VERSION ""

NS_ :

BS_:

BU_:

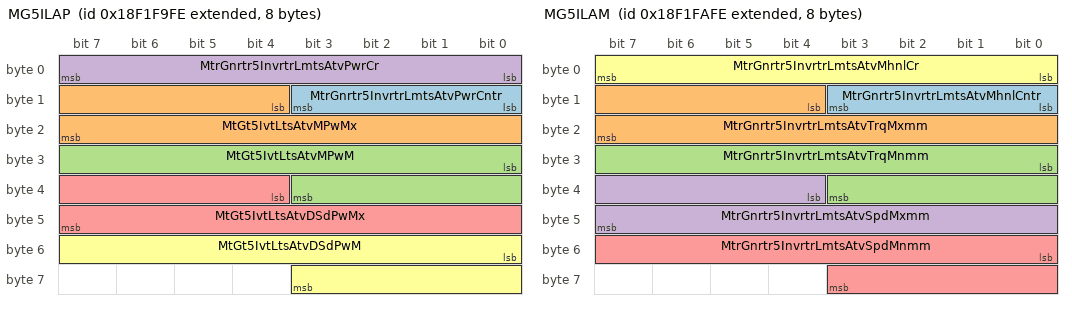
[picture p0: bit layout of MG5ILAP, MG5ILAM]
BO_ 2565995006 MG5ILAP: 8 Vector__XXX
 SG_ MtrGnrtr5InvrtrLmtsAtvPwrCntr : 8|4@1+ (1,0) [0|15] "" Vector__XXX
 SG_ MtGt5IvtLtsAtvMPwMx : 12|12@1+ (0.0625,-125) [-125|125.9375] "%" Vector__XXX
 SG_ MtGt5IvtLtsAtvMPwM : 24|12@1+ (0.0625,-125) [-125|125.9375] "%" Vector__XXX
 SG_ MtrGnrtr5InvrtrLmtsAtvPwrCr : 0|8@1+ (1,0) [0|250] "count" Vector__XXX
 SG_ MtGt5IvtLtsAtvDSdPwMx : 36|12@1+ (0.0625,-125) [-125|125.9375] "%" Vector__XXX
 SG_ MtGt5IvtLtsAtvDSdPwM : 48|12@1+ (0.0625,-125) [-125|125.9375] "%" Vector__XXX

BO_ 2565995262 MG5ILAM: 8 Vector__XXX
 SG_ MtrGnrtr5InvrtrLmtsAtvMhnlCntr : 8|4@1+ (1,0) [0|15] "" Vector__XXX
 SG_ MtrGnrtr5InvrtrLmtsAtvTrqMxmm : 12|12@1+ (0.0625,-125) [-125|125.9375] "%" Vector__XXX
 SG_ MtrGnrtr5InvrtrLmtsAtvTrqMnmm : 24|12@1+ (0.0625,-125) [-125|125.9375] "%" Vector__XXX
 SG_ MtrGnrtr5InvrtrLmtsAtvSpdMxmm : 36|12@1+ (0.0625,-125) [-125|125.9375] "%" Vector__XXX
 SG_ MtrGnrtr5InvrtrLmtsAtvSpdMnmm : 48|12@1+ (0.0625,-125) [-125|125.9375] "%" Vector__XXX
 SG_ MtrGnrtr5InvrtrLmtsAtvMhnlCr : 0|8@1+ (1,0) [0|250] "count" Vector__XXX

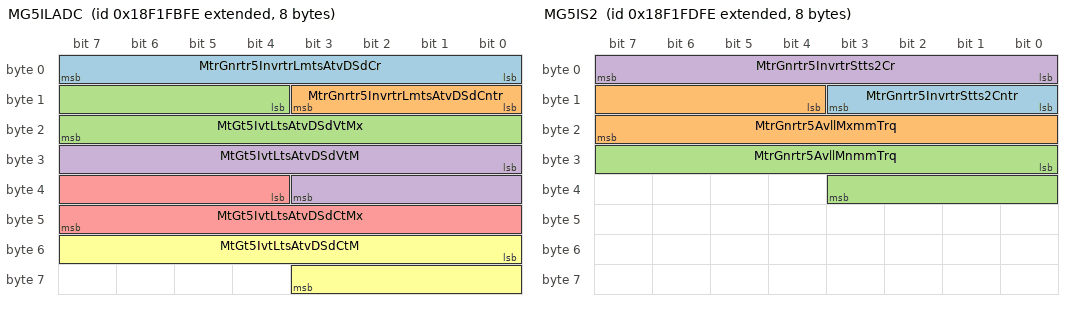
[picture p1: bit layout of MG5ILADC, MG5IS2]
BO_ 2565995518 MG5ILADC: 8 Vector__XXX
 SG_ MtrGnrtr5InvrtrLmtsAtvDSdCr : 0|8@1+ (1,0) [0|250] "count" Vector__XXX
 SG_ MtrGnrtr5InvrtrLmtsAtvDSdCntr : 8|4@1+ (1,0) [0|15] "" Vector__XXX
 SG_ MtGt5IvtLtsAtvDSdVtMx : 12|12@1+ (0.0625,-125) [-125|125.9375] "%" Vector__XXX
 SG_ MtGt5IvtLtsAtvDSdVtM : 24|12@1+ (0.0625,-125) [-125|125.9375] "%" Vector__XXX
 SG_ MtGt5IvtLtsAtvDSdCtMx : 36|12@1+ (0.0625,-125) [-125|125.9375] "%" Vector__XXX
 SG_ MtGt5IvtLtsAtvDSdCtM : 48|12@1+ (0.0625,-125) [-125|125.9375] "%" Vector__XXX

BO_ 2565995774 MG5ILV: 8 Vector__XXX
 SG_ MtrGnrtr5InvrtrSwthdIgntnVltg : 0|16@1+ (0.05,0) [0|3212.75] "V" Vector__XXX
 SG_ MtrGnrtr5InvrtrUnswthdSlVltg : 16|16@1+ (0.05,0) [0|3212.75] "V" Vector__XXX

BO_ 2565996030 MG5IS2: 8 Vector__XXX
 SG_ MtrGnrtr5InvrtrStts2Cntr : 8|4@1+ (1,0) [0|15] "" Vector__XXX
 SG_ MtrGnrtr5AvllMxmmTrq : 12|12@1+ (0.0625,-125) [-125|125.9375] "%" Vector__XXX
 SG_ MtrGnrtr5AvllMnmmTrq : 24|12@1+ (0.0625,-125) [-125|125.9375] "%" Vector__XXX
 SG_ MtrGnrtr5InvrtrStts2Cr : 0|8@1+ (1,0) [0|250] "count" Vector__XXX

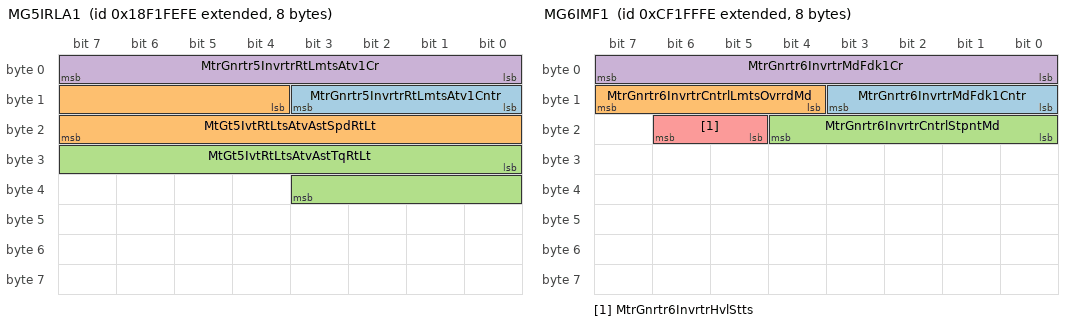
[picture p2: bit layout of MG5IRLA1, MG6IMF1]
BO_ 2565996286 MG5IRLA1: 8 Vector__XXX
 SG_ MtrGnrtr5InvrtrRtLmtsAtv1Cntr : 8|4@1+ (1,0) [0|15] "" Vector__XXX
 SG_ MtGt5IvtRtLtsAtvAstSpdRtLt : 12|12@1+ (0.25,0) [0|1003.75] "%/s" Vector__XXX
 SG_ MtGt5IvtRtLtsAtvAstTqRtLt : 24|12@1+ (2,0) [0|8030] "%/s" Vector__XXX
 SG_ MtrGnrtr5InvrtrRtLmtsAtv1Cr : 0|8@1+ (1,0) [0|250] "count" Vector__XXX

BO_ 2364669950 MG6IMF1: 8 Vector__XXX
 SG_ MtrGnrtr6InvrtrMdFdk1Cntr : 8|4@1+ (1,0) [0|15] "" Vector__XXX
 SG_ MtrGnrtr6InvrtrCntrlLmtsOvrrdMd : 12|4@1+ (1,0) [0|15] "" Vector__XXX
 SG_ MtrGnrtr6InvrtrCntrlStpntMd : 16|5@1+ (1,0) [0|31] "" Vector__XXX
 SG_ MtrGnrtr6InvrtrMdFdk1Cr : 0|8@1+ (1,0) [0|250] "count" Vector__XXX
 SG_ MtrGnrtr6InvrtrHvlStts : 21|2@1+ (1,0) [0|3] "" Vector__XXX

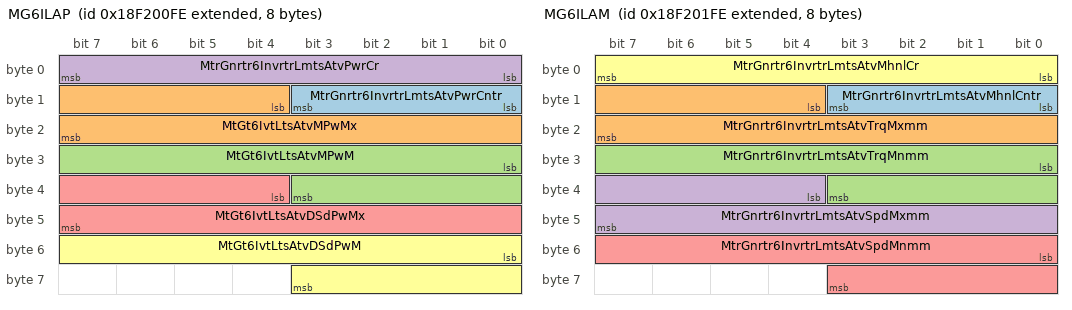
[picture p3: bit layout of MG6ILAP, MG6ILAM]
BO_ 2565996798 MG6ILAP: 8 Vector__XXX
 SG_ MtrGnrtr6InvrtrLmtsAtvPwrCntr : 8|4@1+ (1,0) [0|15] "" Vector__XXX
 SG_ MtGt6IvtLtsAtvMPwMx : 12|12@1+ (0.0625,-125) [-125|125.9375] "%" Vector__XXX
 SG_ MtGt6IvtLtsAtvMPwM : 24|12@1+ (0.0625,-125) [-125|125.9375] "%" Vector__XXX
 SG_ MtrGnrtr6InvrtrLmtsAtvPwrCr : 0|8@1+ (1,0) [0|250] "count" Vector__XXX
 SG_ MtGt6IvtLtsAtvDSdPwMx : 36|12@1+ (0.0625,-125) [-125|125.9375] "%" Vector__XXX
 SG_ MtGt6IvtLtsAtvDSdPwM : 48|12@1+ (0.0625,-125) [-125|125.9375] "%" Vector__XXX

BO_ 2565997054 MG6ILAM: 8 Vector__XXX
 SG_ MtrGnrtr6InvrtrLmtsAtvMhnlCntr : 8|4@1+ (1,0) [0|15] "" Vector__XXX
 SG_ MtrGnrtr6InvrtrLmtsAtvTrqMxmm : 12|12@1+ (0.0625,-125) [-125|125.9375] "%" Vector__XXX
 SG_ MtrGnrtr6InvrtrLmtsAtvTrqMnmm : 24|12@1+ (0.0625,-125) [-125|125.9375] "%" Vector__XXX
 SG_ MtrGnrtr6InvrtrLmtsAtvSpdMxmm : 36|12@1+ (0.0625,-125) [-125|125.9375] "%" Vector__XXX
 SG_ MtrGnrtr6InvrtrLmtsAtvSpdMnmm : 48|12@1+ (0.0625,-125) [-125|125.9375] "%" Vector__XXX
 SG_ MtrGnrtr6InvrtrLmtsAtvMhnlCr : 0|8@1+ (1,0) [0|250] "count" Vector__XXX

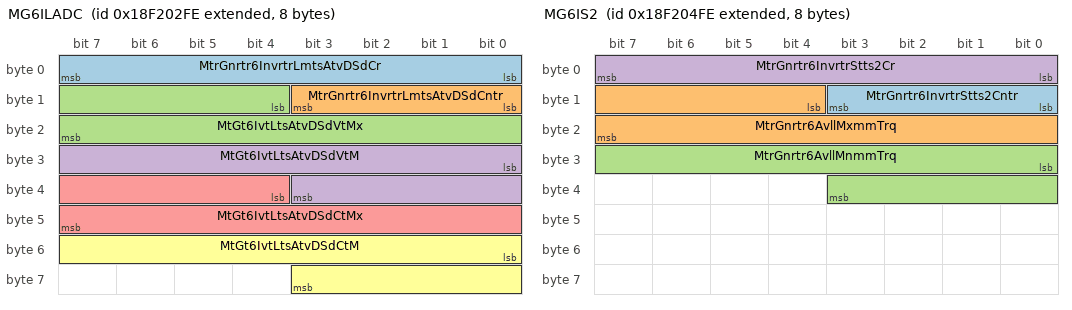
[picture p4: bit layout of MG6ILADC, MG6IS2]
BO_ 2565997310 MG6ILADC: 8 Vector__XXX
 SG_ MtrGnrtr6InvrtrLmtsAtvDSdCr : 0|8@1+ (1,0) [0|250] "count" Vector__XXX
 SG_ MtrGnrtr6InvrtrLmtsAtvDSdCntr : 8|4@1+ (1,0) [0|15] "" Vector__XXX
 SG_ MtGt6IvtLtsAtvDSdVtMx : 12|12@1+ (0.0625,-125) [-125|125.9375] "%" Vector__XXX
 SG_ MtGt6IvtLtsAtvDSdVtM : 24|12@1+ (0.0625,-125) [-125|125.9375] "%" Vector__XXX
 SG_ MtGt6IvtLtsAtvDSdCtMx : 36|12@1+ (0.0625,-125) [-125|125.9375] "%" Vector__XXX
 SG_ MtGt6IvtLtsAtvDSdCtM : 48|12@1+ (0.0625,-125) [-125|125.9375] "%" Vector__XXX

BO_ 2565997566 MG6ILV: 8 Vector__XXX
 SG_ MtrGnrtr6InvrtrSwthdIgntnVltg : 0|16@1+ (0.05,0) [0|3212.75] "V" Vector__XXX
 SG_ MtrGnrtr6InvrtrUnswthdSlVltg : 16|16@1+ (0.05,0) [0|3212.75] "V" Vector__XXX

BO_ 2565997822 MG6IS2: 8 Vector__XXX
 SG_ MtrGnrtr6InvrtrStts2Cntr : 8|4@1+ (1,0) [0|15] "" Vector__XXX
 SG_ MtrGnrtr6AvllMxmmTrq : 12|12@1+ (0.0625,-125) [-125|125.9375] "%" Vector__XXX
 SG_ MtrGnrtr6AvllMnmmTrq : 24|12@1+ (0.0625,-125) [-125|125.9375] "%" Vector__XXX
 SG_ MtrGnrtr6InvrtrStts2Cr : 0|8@1+ (1,0) [0|250] "count" Vector__XXX

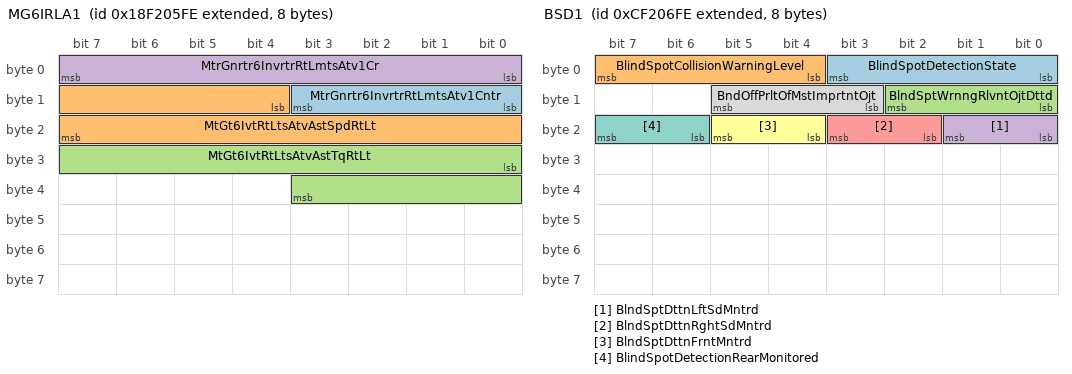
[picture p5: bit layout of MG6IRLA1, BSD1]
BO_ 2565998078 MG6IRLA1: 8 Vector__XXX
 SG_ MtrGnrtr6InvrtrRtLmtsAtv1Cntr : 8|4@1+ (1,0) [0|15] "" Vector__XXX
 SG_ MtGt6IvtRtLtsAtvAstSpdRtLt : 12|12@1+ (0.25,0) [0|1003.75] "%/s" Vector__XXX
 SG_ MtGt6IvtRtLtsAtvAstTqRtLt : 24|12@1+ (2,0) [0|8030] "%/s" Vector__XXX
 SG_ MtrGnrtr6InvrtrRtLmtsAtv1Cr : 0|8@1+ (1,0) [0|250] "count" Vector__XXX

BO_ 2364671742 BSD1: 8 Vector__XXX
 SG_ BlindSpotDetectionState : 0|4@1+ (1,0) [0|15] "" Vector__XXX
 SG_ BlindSpotCollisionWarningLevel : 4|4@1+ (1,0) [0|15] "" Vector__XXX
 SG_ BlndSptWrnngRlvntOjtDttd : 8|3@1+ (1,0) [0|7] "" Vector__XXX
 SG_ BlndSptDttnLftSdMntrd : 16|2@1+ (1,0) [0|3] "" Vector__XXX
 SG_ BlndSptDttnRghtSdMntrd : 18|2@1+ (1,0) [0|3] "" Vector__XXX
 SG_ BlndSptDttnFrntMntrd : 20|2@1+ (1,0) [0|3] "" Vector__XXX
 SG_ BlindSpotDetectionRearMonitored : 22|2@1+ (1,0) [0|3] "" Vector__XXX
 SG_ BndOffPrltOfMstImprtntOjt : 11|3@1+ (1,0) [0|7] "" Vector__XXX

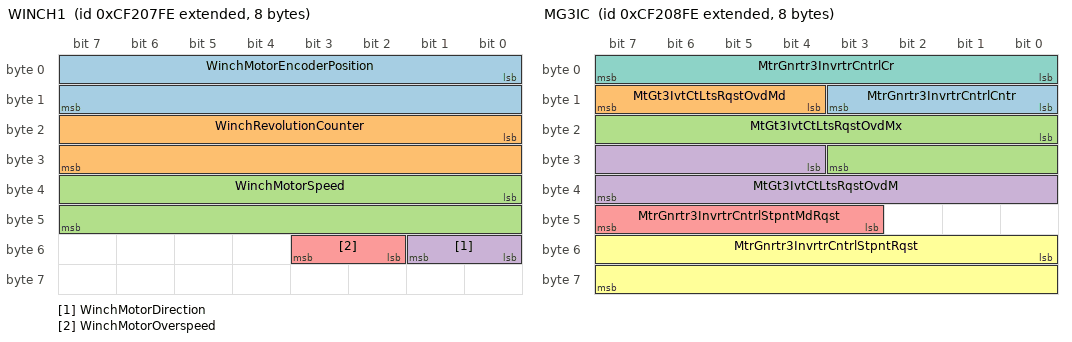
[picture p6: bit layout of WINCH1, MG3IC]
BO_ 2364671998 WINCH1: 8 Vector__XXX
 SG_ WinchMotorEncoderPosition : 0|16@1+ (1,0) [0|32767] "count" Vector__XXX
 SG_ WinchRevolutionCounter : 16|16@1+ (1,-32128) [-32128|32127] "count" Vector__XXX
 SG_ WinchMotorSpeed : 32|16@1+ (0.125,0) [0|8031.875] "rpm" Vector__XXX
 SG_ WinchMotorDirection : 48|2@1+ (1,0) [0|3] "" Vector__XXX
 SG_ WinchMotorOverspeed : 50|2@1+ (1,0) [0|3] "" Vector__XXX

BO_ 2364672254 MG3IC: 8 Vector__XXX
 SG_ MtrGnrtr3InvrtrCntrlCntr : 8|4@1+ (1,0) [0|15] "" Vector__XXX
 SG_ MtGt3IvtCtLtsRqstOvdMd : 12|4@1+ (1,0) [0|15] "" Vector__XXX
 SG_ MtGt3IvtCtLtsRqstOvdMx : 16|12@1+ (0.0625,-125) [-125|125.9375] "%" Vector__XXX
 SG_ MtGt3IvtCtLtsRqstOvdM : 28|12@1+ (0.0625,-125) [-125|125.9375] "%" Vector__XXX
 SG_ MtrGnrtr3InvrtrCntrlStpntMdRqst : 43|5@1+ (1,0) [0|31] "" Vector__XXX
 SG_ MtrGnrtr3InvrtrCntrlStpntRqst : 48|16@1+ (0.00390625,-125) [-125|125.99609375] "%" Vector__XXX
 SG_ MtrGnrtr3InvrtrCntrlCr : 0|8@1+ (1,0) [0|250] "count" Vector__XXX

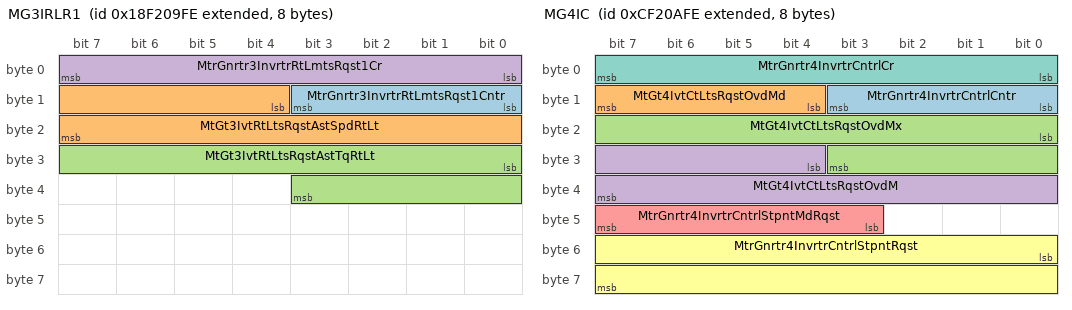
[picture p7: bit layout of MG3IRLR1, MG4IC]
BO_ 2565999102 MG3IRLR1: 8 Vector__XXX
 SG_ MtrGnrtr3InvrtrRtLmtsRqst1Cntr : 8|4@1+ (1,0) [0|15] "" Vector__XXX
 SG_ MtGt3IvtRtLtsRqstAstSpdRtLt : 12|12@1+ (0.25,0) [0|1003.75] "%/s" Vector__XXX
 SG_ MtGt3IvtRtLtsRqstAstTqRtLt : 24|12@1+ (2,0) [0|8030] "%/s" Vector__XXX
 SG_ MtrGnrtr3InvrtrRtLmtsRqst1Cr : 0|8@1+ (1,0) [0|250] "count" Vector__XXX

BO_ 2364672766 MG4IC: 8 Vector__XXX
 SG_ MtrGnrtr4InvrtrCntrlCntr : 8|4@1+ (1,0) [0|15] "" Vector__XXX
 SG_ MtGt4IvtCtLtsRqstOvdMd : 12|4@1+ (1,0) [0|15] "" Vector__XXX
 SG_ MtGt4IvtCtLtsRqstOvdMx : 16|12@1+ (0.0625,-125) [-125|125.9375] "%" Vector__XXX
 SG_ MtGt4IvtCtLtsRqstOvdM : 28|12@1+ (0.0625,-125) [-125|125.9375] "%" Vector__XXX
 SG_ MtrGnrtr4InvrtrCntrlStpntMdRqst : 43|5@1+ (1,0) [0|31] "" Vector__XXX
 SG_ MtrGnrtr4InvrtrCntrlStpntRqst : 48|16@1+ (0.00390625,-125) [-125|125.99609375] "%" Vector__XXX
 SG_ MtrGnrtr4InvrtrCntrlCr : 0|8@1+ (1,0) [0|250] "count" Vector__XXX

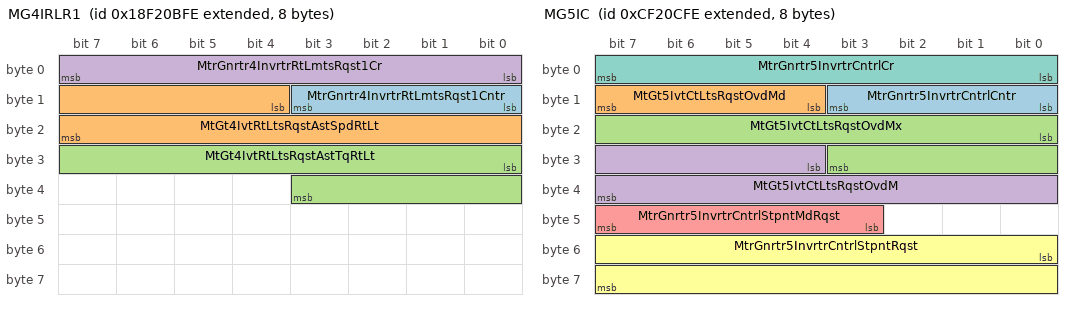
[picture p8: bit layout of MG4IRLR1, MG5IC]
BO_ 2565999614 MG4IRLR1: 8 Vector__XXX
 SG_ MtrGnrtr4InvrtrRtLmtsRqst1Cntr : 8|4@1+ (1,0) [0|15] "" Vector__XXX
 SG_ MtGt4IvtRtLtsRqstAstSpdRtLt : 12|12@1+ (0.25,0) [0|1003.75] "%/s" Vector__XXX
 SG_ MtGt4IvtRtLtsRqstAstTqRtLt : 24|12@1+ (2,0) [0|8030] "%/s" Vector__XXX
 SG_ MtrGnrtr4InvrtrRtLmtsRqst1Cr : 0|8@1+ (1,0) [0|250] "count" Vector__XXX

BO_ 2364673278 MG5IC: 8 Vector__XXX
 SG_ MtrGnrtr5InvrtrCntrlCntr : 8|4@1+ (1,0) [0|15] "" Vector__XXX
 SG_ MtGt5IvtCtLtsRqstOvdMd : 12|4@1+ (1,0) [0|15] "" Vector__XXX
 SG_ MtGt5IvtCtLtsRqstOvdMx : 16|12@1+ (0.0625,-125) [-125|125.9375] "%" Vector__XXX
 SG_ MtGt5IvtCtLtsRqstOvdM : 28|12@1+ (0.0625,-125) [-125|125.9375] "%" Vector__XXX
 SG_ MtrGnrtr5InvrtrCntrlStpntMdRqst : 43|5@1+ (1,0) [0|31] "" Vector__XXX
 SG_ MtrGnrtr5InvrtrCntrlStpntRqst : 48|16@1+ (0.00390625,-125) [-125|125.99609375] "%" Vector__XXX
 SG_ MtrGnrtr5InvrtrCntrlCr : 0|8@1+ (1,0) [0|250] "count" Vector__XXX

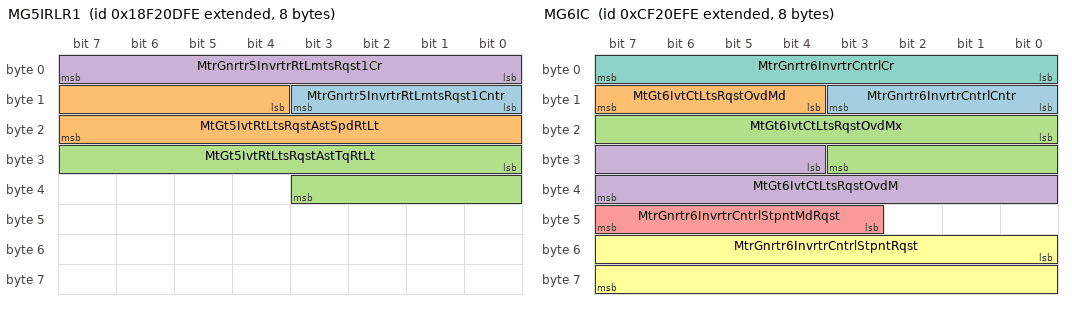
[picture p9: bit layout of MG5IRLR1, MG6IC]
BO_ 2566000126 MG5IRLR1: 8 Vector__XXX
 SG_ MtrGnrtr5InvrtrRtLmtsRqst1Cntr : 8|4@1+ (1,0) [0|15] "" Vector__XXX
 SG_ MtGt5IvtRtLtsRqstAstSpdRtLt : 12|12@1+ (0.25,0) [0|1003.75] "%/s" Vector__XXX
 SG_ MtGt5IvtRtLtsRqstAstTqRtLt : 24|12@1+ (2,0) [0|8030] "%/s" Vector__XXX
 SG_ MtrGnrtr5InvrtrRtLmtsRqst1Cr : 0|8@1+ (1,0) [0|250] "count" Vector__XXX

BO_ 2364673790 MG6IC: 8 Vector__XXX
 SG_ MtrGnrtr6InvrtrCntrlCntr : 8|4@1+ (1,0) [0|15] "" Vector__XXX
 SG_ MtGt6IvtCtLtsRqstOvdMd : 12|4@1+ (1,0) [0|15] "" Vector__XXX
 SG_ MtGt6IvtCtLtsRqstOvdMx : 16|12@1+ (0.0625,-125) [-125|125.9375] "%" Vector__XXX
 SG_ MtGt6IvtCtLtsRqstOvdM : 28|12@1+ (0.0625,-125) [-125|125.9375] "%" Vector__XXX
 SG_ MtrGnrtr6InvrtrCntrlStpntMdRqst : 43|5@1+ (1,0) [0|31] "" Vector__XXX
 SG_ MtrGnrtr6InvrtrCntrlStpntRqst : 48|16@1+ (0.00390625,-125) [-125|125.99609375] "%" Vector__XXX
 SG_ MtrGnrtr6InvrtrCntrlCr : 0|8@1+ (1,0) [0|250] "count" Vector__XXX

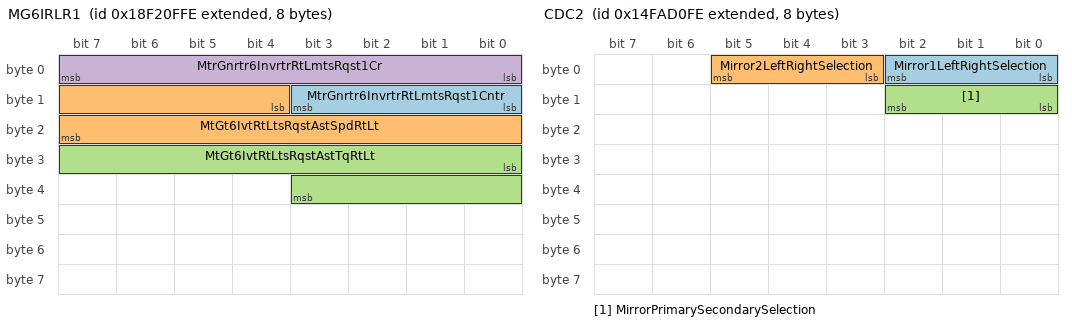
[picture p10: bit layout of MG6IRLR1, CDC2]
BO_ 2566000638 MG6IRLR1: 8 Vector__XXX
 SG_ MtrGnrtr6InvrtrRtLmtsRqst1Cntr : 8|4@1+ (1,0) [0|15] "" Vector__XXX
 SG_ MtGt6IvtRtLtsRqstAstSpdRtLt : 12|12@1+ (0.25,0) [0|1003.75] "%/s" Vector__XXX
 SG_ MtGt6IvtRtLtsRqstAstTqRtLt : 24|12@1+ (2,0) [0|8030] "%/s" Vector__XXX
 SG_ MtrGnrtr6InvrtrRtLmtsRqst1Cr : 0|8@1+ (1,0) [0|250] "count" Vector__XXX

BO_ 2566574078 EVCCD1: 12 Vector__XXX
 SG_ EvccControlPilotMaximumVoltage : 0|16@1+ (0.05,-1606) [-1606|1606.75] "V" Vector__XXX
 SG_ EvccControlPilotMinimumVoltage : 16|16@1+ (0.05,-1606) [-1606|1606.75] "V" Vector__XXX
 SG_ EvccControlPilotPwmFrequency : 32|16@1+ (1,0) [0|64255] "Hz" Vector__XXX
 SG_ EvccControlPilotDutyCycle : 48|8@1+ (0.5,0) [0|100] "%" Vector__XXX
 SG_ EvccControlPilotState : 56|4@1+ (1,0) [0|15] "" Vector__XXX
 SG_ EvccControlPilotSubState : 60|4@1+ (1,0) [0|15] "" Vector__XXX
 SG_ EvccProximityCircuitVoltage : 64|16@1+ (0.01,0) [0|642.55] "V" Vector__XXX
 SG_ EvccInletConnectorTemperature : 80|8@1+ (1,-40) [-40|210] "degC" Vector__XXX
 SG_ EvccCompatibilityCode : 88|4@1+ (1,0) [0|15] "" Vector__XXX

BO_ 2499465470 CDC2: 8 Vector__XXX
 SG_ Mirror1LeftRightSelection : 0|3@1+ (1,0) [0|7] "" Vector__XXX
 SG_ Mirror2LeftRightSelection : 3|3@1+ (1,0) [0|7] "" Vector__XXX
 SG_ MirrorPrimarySecondarySelection : 8|3@1+ (1,0) [0|7] "" Vector__XXX

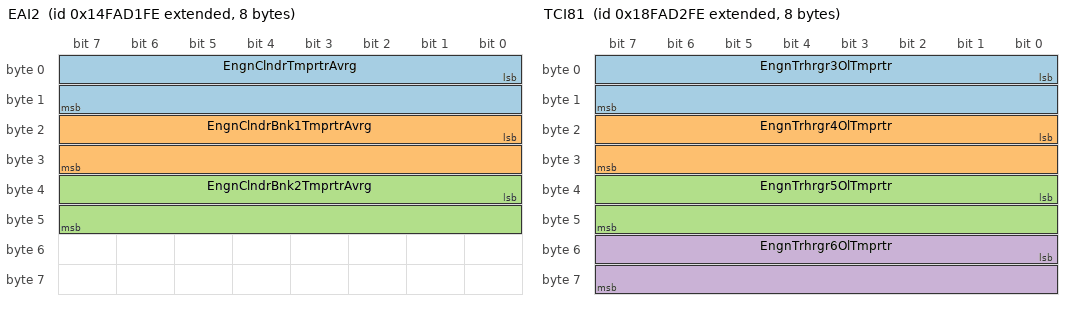
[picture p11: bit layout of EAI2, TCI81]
BO_ 2499465726 EAI2: 8 Vector__XXX
 SG_ EngnClndrTmprtrAvrg : 0|16@1+ (0.03125,-273) [-273|1734.96875] "degC" Vector__XXX
 SG_ EngnClndrBnk1TmprtrAvrg : 16|16@1+ (0.03125,-273) [-273|1734.96875] "degC" Vector__XXX
 SG_ EngnClndrBnk2TmprtrAvrg : 32|16@1+ (0.03125,-273) [-273|1734.96875] "degC" Vector__XXX

BO_ 2566574846 TCI81: 8 Vector__XXX
 SG_ EngnTrhrgr3OlTmprtr : 0|16@1+ (0.03125,-273) [-273|1734.96875] "degC" Vector__XXX
 SG_ EngnTrhrgr4OlTmprtr : 16|16@1+ (0.03125,-273) [-273|1734.96875] "degC" Vector__XXX
 SG_ EngnTrhrgr5OlTmprtr : 32|16@1+ (0.03125,-273) [-273|1734.96875] "degC" Vector__XXX
 SG_ EngnTrhrgr6OlTmprtr : 48|16@1+ (0.03125,-273) [-273|1734.96875] "degC" Vector__XXX

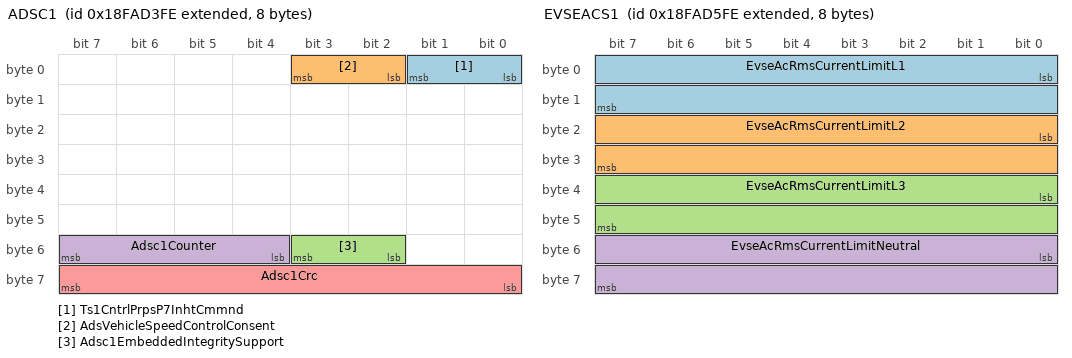
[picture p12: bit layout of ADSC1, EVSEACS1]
BO_ 2566575102 ADSC1: 8 Vector__XXX
 SG_ Ts1CntrlPrpsP7InhtCmmnd : 0|2@1+ (1,0) [0|3] "" Vector__XXX
 SG_ AdsVehicleSpeedControlConsent : 2|2@1+ (1,0) [0|3] "" Vector__XXX
 SG_ Adsc1EmbeddedIntegritySupport : 50|2@1+ (1,0) [0|3] "" Vector__XXX
 SG_ Adsc1Counter : 52|4@1+ (1,0) [0|15] "" Vector__XXX
 SG_ Adsc1Crc : 56|8@1+ (1,0) [0|250] "count" Vector__XXX

BO_ 2566575358 EVSEACS2: 8 Vector__XXX
 SG_ EvseAcRmsCurrent : 0|16@1+ (0.05,-1600) [-1600|1612.75] "A" Vector__XXX
 SG_ EvseAcRmsVoltage : 16|16@1+ (0.05,0) [0|3212.75] "V" Vector__XXX

BO_ 2566575614 EVSEACS1: 8 Vector__XXX
 SG_ EvseAcRmsCurrentLimitL1 : 0|16@1+ (0.0625,0) [0|4015.9375] "A" Vector__XXX
 SG_ EvseAcRmsCurrentLimitL2 : 16|16@1+ (0.0625,0) [0|4015.9375] "A" Vector__XXX
 SG_ EvseAcRmsCurrentLimitL3 : 32|16@1+ (0.0625,0) [0|4015.9375] "A" Vector__XXX
 SG_ EvseAcRmsCurrentLimitNeutral : 48|16@1+ (0.0625,0) [0|4015.9375] "A" Vector__XXX

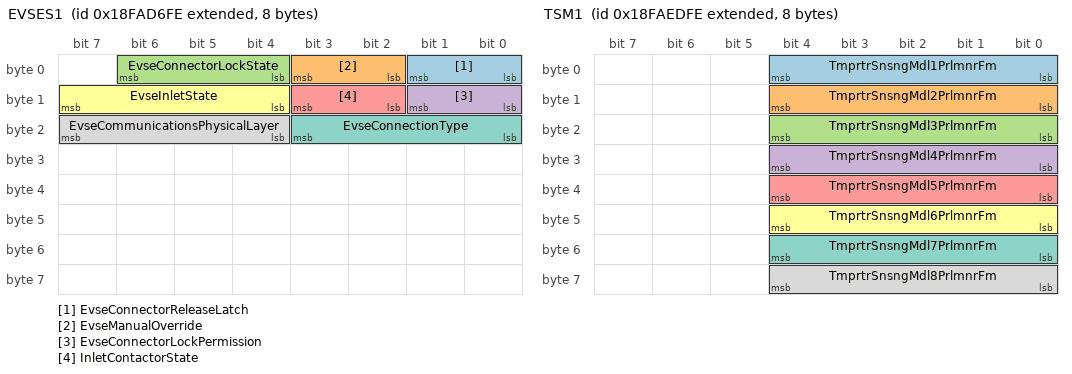
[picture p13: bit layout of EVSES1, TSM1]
BO_ 2566575870 EVSES1: 8 Vector__XXX
 SG_ EvseConnectorReleaseLatch : 0|2@1+ (1,0) [0|3] "" Vector__XXX
 SG_ EvseManualOverride : 2|2@1+ (1,0) [0|3] "" Vector__XXX
 SG_ EvseConnectorLockState : 4|3@1+ (1,0) [0|7] "" Vector__XXX
 SG_ EvseConnectorLockPermission : 8|2@1+ (1,0) [0|3] "" Vector__XXX
 SG_ InletContactorState : 10|2@1+ (1,0) [0|3] "" Vector__XXX
 SG_ EvseInletState : 12|4@1+ (1,0) [0|15] "" Vector__XXX
 SG_ EvseConnectionType : 16|4@1+ (1,0) [0|15] "" Vector__XXX
 SG_ EvseCommunicationsPhysicalLayer : 20|4@1+ (1,0) [0|15] "" Vector__XXX

BO_ 2566581758 TSM1: 8 Vector__XXX
 SG_ TmprtrSnsngMdl1PrlmnrFm : 0|5@1+ (1,0) [0|31] "" Vector__XXX
 SG_ TmprtrSnsngMdl2PrlmnrFm : 8|5@1+ (1,0) [0|31] "" Vector__XXX
 SG_ TmprtrSnsngMdl3PrlmnrFm : 16|5@1+ (1,0) [0|31] "" Vector__XXX
 SG_ TmprtrSnsngMdl4PrlmnrFm : 24|5@1+ (1,0) [0|31] "" Vector__XXX
 SG_ TmprtrSnsngMdl5PrlmnrFm : 32|5@1+ (1,0) [0|31] "" Vector__XXX
 SG_ TmprtrSnsngMdl6PrlmnrFm : 40|5@1+ (1,0) [0|31] "" Vector__XXX
 SG_ TmprtrSnsngMdl7PrlmnrFm : 48|5@1+ (1,0) [0|31] "" Vector__XXX
 SG_ TmprtrSnsngMdl8PrlmnrFm : 56|5@1+ (1,0) [0|31] "" Vector__XXX

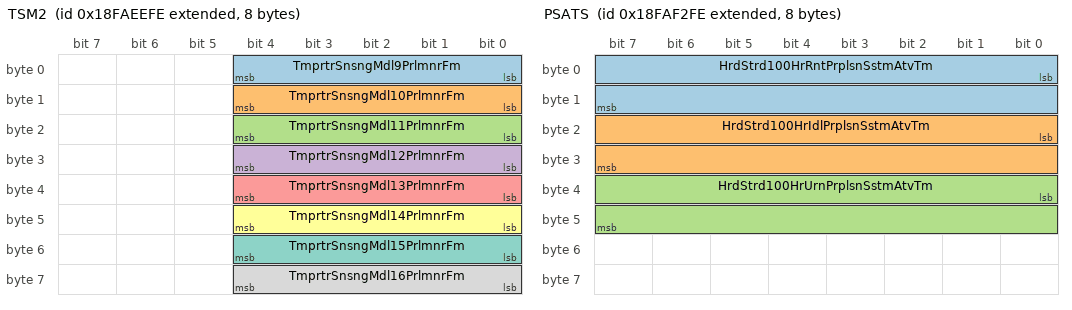
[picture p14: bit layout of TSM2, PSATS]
BO_ 2566582014 TSM2: 8 Vector__XXX
 SG_ TmprtrSnsngMdl9PrlmnrFm : 0|5@1+ (1,0) [0|31] "" Vector__XXX
 SG_ TmprtrSnsngMdl10PrlmnrFm : 8|5@1+ (1,0) [0|31] "" Vector__XXX
 SG_ TmprtrSnsngMdl11PrlmnrFm : 16|5@1+ (1,0) [0|31] "" Vector__XXX
 SG_ TmprtrSnsngMdl12PrlmnrFm : 24|5@1+ (1,0) [0|31] "" Vector__XXX
 SG_ TmprtrSnsngMdl13PrlmnrFm : 32|5@1+ (1,0) [0|31] "" Vector__XXX
 SG_ TmprtrSnsngMdl14PrlmnrFm : 40|5@1+ (1,0) [0|31] "" Vector__XXX
 SG_ TmprtrSnsngMdl15PrlmnrFm : 48|5@1+ (1,0) [0|31] "" Vector__XXX
 SG_ TmprtrSnsngMdl16PrlmnrFm : 56|5@1+ (1,0) [0|31] "" Vector__XXX

BO_ 2566582270 A2SCRSI3: 8 Vector__XXX
 SG_ Aftrtrtmnt2SrNrmlzdCnvrsnEffn : 0|8@1+ (0.4,0) [0|100] "%" Vector__XXX

BO_ 2566582526 A1SCRSI3: 8 Vector__XXX
 SG_ Aftrtrtmnt1SrNrmlzdCnvrsnEffn : 0|8@1+ (0.4,0) [0|100] "%" Vector__XXX
 SG_ Atttt1DsExstFdUsdTsOptC : 8|16@1+ (0.1,0) [0|6425.5] "l" Vector__XXX

BO_ 2566582782 PSATL: 12 Vector__XXX
 SG_ HrdLftmPrplsnSstmAtvTm : 0|32@1+ (1,0) [0|4211081215] "s" Vector__XXX
 SG_ HrdLftmIdlPrplsnSstmAtvTm : 32|32@1+ (1,0) [0|4211081215] "s" Vector__XXX
 SG_ HrdLftmUrnPrplsnSstmAtvTm : 64|32@1+ (1,0) [0|4211081215] "s" Vector__XXX

BO_ 2566583038 PSATS: 8 Vector__XXX
 SG_ HrdStrd100HrRntPrplsnSstmAtvTm : 0|16@1+ (10,0) [0|642550] "s" Vector__XXX
 SG_ HrdStrd100HrIdlPrplsnSstmAtvTm : 16|16@1+ (10,0) [0|642550] "s" Vector__XXX
 SG_ HrdStrd100HrUrnPrplsnSstmAtvTm : 32|16@1+ (10,0) [0|642550] "s" Vector__XXX

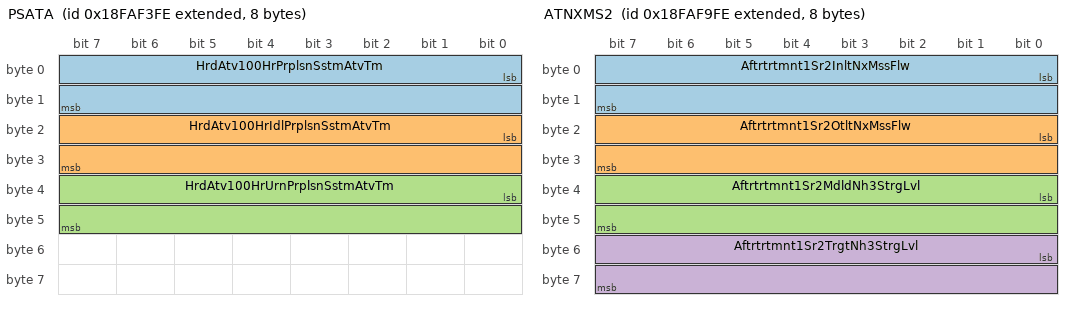
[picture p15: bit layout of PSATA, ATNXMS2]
BO_ 2566583294 PSATA: 8 Vector__XXX
 SG_ HrdAtv100HrPrplsnSstmAtvTm : 0|16@1+ (10,0) [0|642550] "s" Vector__XXX
 SG_ HrdAtv100HrIdlPrplsnSstmAtvTm : 16|16@1+ (10,0) [0|642550] "s" Vector__XXX
 SG_ HrdAtv100HrUrnPrplsnSstmAtvTm : 32|16@1+ (10,0) [0|642550] "s" Vector__XXX

BO_ 2566583550 HCDIOL: 32 Vector__XXX
 SG_ HdLtDstTvdICDptOptWtEO : 0|32@1+ (5,0) [0|21055406075] "m" Vector__XXX
 SG_ HdLtDstTvdICDptOptWtER : 32|32@1+ (5,0) [0|21055406075] "m" Vector__XXX
 SG_ HdLtDstTvdIDvStCIsOpt : 64|32@1+ (5,0) [0|21055406075] "m" Vector__XXX
 SG_ HrdLftmFlCnsmdInChrgDpltngOprtn : 96|32@1+ (0.5,0) [0|2105540607.5] "l" Vector__XXX
 SG_ HdLtFCsdIDvStCIsOpt : 128|32@1+ (0.5,0) [0|2105540607.5] "l" Vector__XXX
 SG_ HdLtGdECsdICDptOptWtEO : 160|32@1+ (1,0) [0|4211081215] "kWh" Vector__XXX
 SG_ HdLtGdECsdICDptOptWtER : 192|32@1+ (1,0) [0|4211081215] "kWh" Vector__XXX
 SG_ HrdLftmGrdEnrgIntThBttr : 224|32@1+ (1,0) [0|4211081215] "kWh" Vector__XXX

BO_ 2566583806 HCDIOS: 16 Vector__XXX
 SG_ HdStd100HDstTvdICDptOptWtEO : 0|16@1+ (0.25,0) [0|16063.75] "km" Vector__XXX
 SG_ HdStd100HDstTvdICDptOptWtER : 16|16@1+ (0.25,0) [0|16063.75] "km" Vector__XXX
 SG_ HdStd100HDstTvdIDvStCIsOpt : 32|16@1+ (0.25,0) [0|16063.75] "km" Vector__XXX
 SG_ HdStd100HFCsdICDptOpt : 48|16@1+ (0.5,0) [0|32127.5] "l" Vector__XXX
 SG_ HdStd100HFCsdIDvStCIsOpt : 64|16@1+ (0.5,0) [0|32127.5] "l" Vector__XXX
 SG_ HdStd100HGdECsdICDptOptWtEO : 80|16@1+ (1,0) [0|64255] "kWh" Vector__XXX
 SG_ HdStd100HGdECsdICDptOptWtER : 96|16@1+ (1,0) [0|64255] "kWh" Vector__XXX
 SG_ HrdStrd100HrGrdEnrgIntThBttr : 112|16@1+ (1,0) [0|64255] "kWh" Vector__XXX

BO_ 2566584062 HCDIOA: 16 Vector__XXX
 SG_ HdAtv100HDstTvdICDptOptWtEO : 0|16@1+ (0.25,0) [0|16063.75] "km" Vector__XXX
 SG_ HdAtv100HDstTvdICDptOptWtER : 16|16@1+ (0.25,0) [0|16063.75] "km" Vector__XXX
 SG_ HdAtv100HDstTvdIDvStCIsOpt : 32|16@1+ (0.25,0) [0|16063.75] "km" Vector__XXX
 SG_ HdAtv100HFCsdICDptOpt : 48|16@1+ (0.5,0) [0|32127.5] "l" Vector__XXX
 SG_ HdAtv100HFCsdIDvStCIsOpt : 64|16@1+ (0.5,0) [0|32127.5] "l" Vector__XXX
 SG_ HdAtv100HGdECsdICDptOptWtEO : 80|16@1+ (1,0) [0|64255] "kWh" Vector__XXX
 SG_ HdAtv100HGdECsdICDptOptWtER : 96|16@1+ (1,0) [0|64255] "kWh" Vector__XXX
 SG_ HrdAtv100HrGrdEnrgIntThBttr : 112|16@1+ (1,0) [0|64255] "kWh" Vector__XXX

BO_ 2566584318 AT1HI3: 32 Vector__XXX
 SG_ Atttt1TtERtWtNDDv : 192|32@1+ (1,0) [0|4211081215] "s" Vector__XXX
 SG_ Atttt1DpRtCptSttEVDst1 : 0|32@1+ (5,0) [0|21055406075] "m" Vector__XXX
 SG_ Atttt1DpRtCptEdEVDst1 : 32|32@1+ (5,0) [0|21055406075] "m" Vector__XXX
 SG_ Atttt1DpRtCptSttEVDst2 : 64|32@1+ (5,0) [0|21055406075] "m" Vector__XXX
 SG_ Atttt1DpRtCptEdEVDst2 : 96|32@1+ (0.125,0) [0|526385151.875] "km" Vector__XXX
 SG_ Atttt1DpRtCptSttEVDst3 : 128|32@1+ (5,0) [0|21055406075] "m" Vector__XXX
 SG_ Atttt1DpRtCptEdEVDst3 : 160|32@1+ (5,0) [0|21055406075] "m" Vector__XXX
 SG_ Atttt1TtTSItTptBw200Css : 224|32@1+ (1,0) [0|4211081215] "s" Vector__XXX

BO_ 2566584830 ATNXMS2: 8 Vector__XXX
 SG_ Aftrtrtmnt1Sr2InltNxMssFlw : 0|16@1+ (0.0001,0) [0|6.4255] "g/s" Vector__XXX
 SG_ Aftrtrtmnt1Sr2OtltNxMssFlw : 16|16@1+ (0.0001,0) [0|6.4255] "g/s" Vector__XXX
 SG_ Aftrtrtmnt1Sr2MdldNh3StrgLvl : 32|16@1+ (1,0) [0|64255] "mg/l" Vector__XXX
 SG_ Aftrtrtmnt1Sr2TrgtNh3StrgLvl : 48|16@1+ (1,0) [0|64255] "mg/l" Vector__XXX

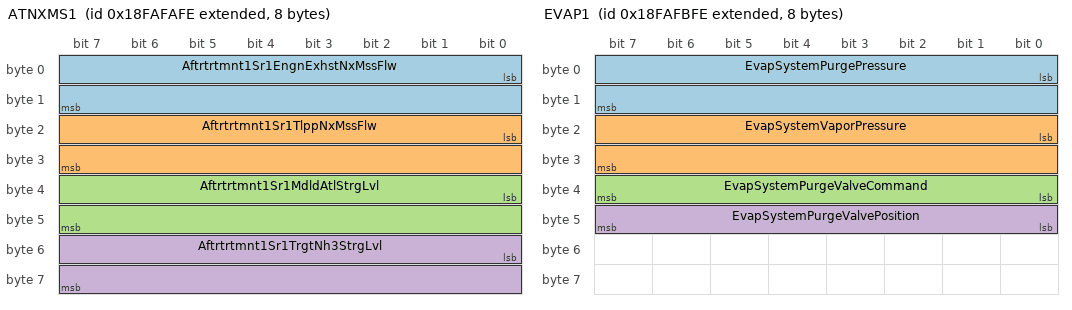
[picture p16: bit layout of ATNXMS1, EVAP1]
BO_ 2566585086 ATNXMS1: 8 Vector__XXX
 SG_ Aftrtrtmnt1Sr1EngnExhstNxMssFlw : 0|16@1+ (0.0001,0) [0|6.4255] "g/s" Vector__XXX
 SG_ Aftrtrtmnt1Sr1TlppNxMssFlw : 16|16@1+ (0.0001,0) [0|6.4255] "g/s" Vector__XXX
 SG_ Aftrtrtmnt1Sr1MdldAtlStrgLvl : 32|16@1+ (1,0) [0|64255] "mg/l" Vector__XXX
 SG_ Aftrtrtmnt1Sr1TrgtNh3StrgLvl : 48|16@1+ (1,0) [0|64255] "mg/l" Vector__XXX

BO_ 2566585342 EVAP1: 8 Vector__XXX
 SG_ EvapSystemPurgePressure : 0|16@1+ (4,0) [0|257020] "Pa" Vector__XXX
 SG_ EvapSystemVaporPressure : 16|16@1+ (4,0) [0|257020] "Pa" Vector__XXX
 SG_ EvapSystemPurgeValveCommand : 32|8@1+ (0.4,0) [0|100] "%" Vector__XXX
 SG_ EvapSystemPurgeValvePosition : 40|8@1+ (0.4,0) [0|100] "%" Vector__XXX

BO_ 2566585598 GHGTL: 52 Vector__XXX
 SG_ GhgTrkngLftmEngnRnTm : 0|32@1+ (1,0) [0|4211081215] "s" Vector__XXX
 SG_ GhgTrkngLftmVhlDstn : 32|32@1+ (5,0) [0|21055406075] "m" Vector__XXX
 SG_ GhgTrkngLftmVhlFlCnsmptn : 64|32@1+ (0.05,0) [0|210554060.75] "l" Vector__XXX
 SG_ GhgTrkngLftmEngnFlCnsmptn : 96|32@1+ (0.05,0) [0|210554060.75] "l" Vector__XXX
 SG_ GhgTrkngLftmEngnOtptEnrg : 128|32@1+ (1,0) [0|4211081215] "kWh" Vector__XXX
 SG_ GhgTrkngLftmPstvKntEnrgNmrtr : 160|32@1+ (5,0) [0|21055406075] "(km*km)/(h*h)" Vector__XXX
 SG_ GhgTrkngLftmUrnSpdRnTm : 192|32@1+ (1,0) [0|4211081215] "s" Vector__XXX
 SG_ GhgTrackingLifetimeIdleRunTime : 224|32@1+ (1,0) [0|4211081215] "s" Vector__XXX
 SG_ GhgTrkngLftmEngnIdlFlCnsmptn : 256|32@1+ (0.05,0) [0|210554060.75] "l" Vector__XXX
 SG_ GhgTrkngLftmEngnPwrTkOffRnTm : 288|32@1+ (1,0) [0|4211081215] "s" Vector__XXX
 SG_ GhgTrkngLftmStpStrtThnlgRnTm : 384|32@1+ (1,0) [0|4211081215] "s" Vector__XXX
 SG_ GTLtEPwTOFCspt : 320|32@1+ (0.05,0) [0|210554060.75] "l" Vector__XXX
 SG_ GTLtAttEStdwTAtvtCt : 352|32@1+ (1,0) [0|4211081215] "count" Vector__XXX

BO_ 2566585854 GHGTS1: 28 Vector__XXX
 SG_ GhgTrkngStrd100HrEngnRnTm : 0|16@1+ (10,0) [0|642550] "s" Vector__XXX
 SG_ GhgTrkngStrd100HrVhlDstn : 16|16@1+ (0.25,0) [0|16063.75] "km" Vector__XXX
 SG_ GhgTrkngStrd100HrVhlFlCnsmptn : 32|16@1+ (0.5,0) [0|32127.5] "l" Vector__XXX
 SG_ GhgTrkngStrd100HrEngnFlCnsmptn : 48|16@1+ (0.5,0) [0|32127.5] "l" Vector__XXX
 SG_ GhgTrkngStrd100HrEngnOtptEnrg : 64|16@1+ (1,0) [0|64255] "kWh" Vector__XXX
 SG_ GhgTrkngStrd100HrUrnSpdRnTm : 112|16@1+ (10,0) [0|642550] "s" Vector__XXX
 SG_ GhgTrkngStrd100HrIdlRnTm : 128|16@1+ (10,0) [0|642550] "s" Vector__XXX
 SG_ GTStd100HPstvKtENt : 80|32@1+ (1,0) [0|4211081215] "(km*km)/(h*h)" Vector__XXX
 SG_ GTStd100HEIdFCspt : 144|16@1+ (0.5,0) [0|32127.5] "l" Vector__XXX
 SG_ GTStd100HEPwTORT : 160|16@1+ (10,0) [0|642550] "s" Vector__XXX
 SG_ GTStd100HEPwTOFCspt : 176|16@1+ (0.5,0) [0|32127.5] "l" Vector__XXX
 SG_ GTStd100HAttEStdwTAtvtCt : 192|16@1+ (1,0) [0|64255] "count" Vector__XXX
 SG_ GTStd100HStpSttTRT : 208|16@1+ (10,0) [0|642550] "s" Vector__XXX

BO_ 2566586110 GHGTA1: 28 Vector__XXX
 SG_ GhgTrkngAtv100HrEngnRnTm : 0|16@1+ (10,0) [0|642550] "s" Vector__XXX
 SG_ GhgTrkngAtv100HrVhlDstn : 16|16@1+ (0.25,0) [0|16063.75] "km" Vector__XXX
 SG_ GhgTrkngAtv100HrVhlFlCnsmptn : 32|16@1+ (0.5,0) [0|32127.5] "l" Vector__XXX
 SG_ GhgTrkngAtv100HrEngnFlCnsmptn : 48|16@1+ (0.5,0) [0|32127.5] "l" Vector__XXX
 SG_ GhgTrkngAtv100HrEngnOtptEnrg : 64|16@1+ (1,0) [0|64255] "kWh" Vector__XXX
 SG_ GhgTrkngAtv100HrUrnSpdRnTm : 112|16@1+ (10,0) [0|642550] "s" Vector__XXX
 SG_ GhgTrkngAtv100HrIdlRnTm : 128|16@1+ (10,0) [0|642550] "s" Vector__XXX
 SG_ GTAtv100HPstvKtENt : 80|32@1+ (1,0) [0|4211081215] "(km*km)/(h*h)" Vector__XXX
 SG_ GTAtv100HEIdFCspt : 144|16@1+ (0.5,0) [0|32127.5] "l" Vector__XXX
 SG_ GTAtv100HEPwTORT : 160|16@1+ (10,0) [0|642550] "s" Vector__XXX
 SG_ GTAtv100HEPwTOFCspt : 176|16@1+ (0.5,0) [0|32127.5] "l" Vector__XXX
 SG_ GTAtv100HAttEStdwTAtvtCt : 192|16@1+ (1,0) [0|64255] "count" Vector__XXX
 SG_ GTAtv100HStpSttTRT : 208|16@1+ (10,0) [0|642550] "s" Vector__XXX

BO_ 2566587134 NTFCEA: 68 Vector__XXX
 SG_ NxTEAtvtLtFCsptB1Tt : 0|32@1+ (0.05,0) [0|210554060.75] "l" Vector__XXX
 SG_ NxTrkngEngnAtvtLftmFlCnsmptnBn2 : 32|32@1+ (0.05,0) [0|210554060.75] "l" Vector__XXX
 SG_ NxTrkngEngnAtvtLftmFlCnsmptnBn3 : 64|32@1+ (0.05,0) [0|210554060.75] "l" Vector__XXX
 SG_ NxTrkngEngnAtvtLftmFlCnsmptnBn4 : 96|32@1+ (0.05,0) [0|210554060.75] "l" Vector__XXX
 SG_ NxTrkngEngnAtvtLftmFlCnsmptnBn5 : 128|32@1+ (0.05,0) [0|210554060.75] "l" Vector__XXX
 SG_ NxTrkngEngnAtvtLftmFlCnsmptnBn6 : 160|32@1+ (0.05,0) [0|210554060.75] "l" Vector__XXX
 SG_ NxTrkngEngnAtvtLftmFlCnsmptnBn7 : 192|32@1+ (0.05,0) [0|210554060.75] "l" Vector__XXX
 SG_ NxTrkngEngnAtvtLftmFlCnsmptnBn8 : 224|32@1+ (0.05,0) [0|210554060.75] "l" Vector__XXX
 SG_ NxTrkngEngnAtvtLftmFlCnsmptnBn9 : 256|32@1+ (0.05,0) [0|210554060.75] "l" Vector__XXX
 SG_ NxTEAtvtLtFCsptB10 : 288|32@1+ (0.05,0) [0|210554060.75] "l" Vector__XXX
 SG_ NxTEAtvtLtFCsptB11 : 320|32@1+ (0.05,0) [0|210554060.75] "l" Vector__XXX
 SG_ NxTEAtvtLtFCsptB12 : 352|32@1+ (0.05,0) [0|210554060.75] "l" Vector__XXX
 SG_ NxTEAtvtLtFCsptB13 : 384|32@1+ (0.05,0) [0|210554060.75] "l" Vector__XXX
 SG_ NxTEAtvtLtFCsptB14 : 416|32@1+ (0.05,0) [0|210554060.75] "l" Vector__XXX
 SG_ NxTEAtvtLtFCsptB15NtB : 448|32@1+ (0.05,0) [0|210554060.75] "l" Vector__XXX
 SG_ NxTEAtvtLtFCsptB16RB : 480|32@1+ (0.05,0) [0|210554060.75] "l" Vector__XXX
 SG_ NxTEAtvtLtFCsptB17MOB : 512|32@1+ (0.05,0) [0|210554060.75] "l" Vector__XXX

BO_ 2566587390 NTEHEA: 68 Vector__XXX
 SG_ NxTEAtvtLtERTB1Tt : 0|32@1+ (1,0) [0|4211081215] "s" Vector__XXX
 SG_ NxTrkngEngnAtvtLftmEngnRnTmBn2 : 32|32@1+ (1,0) [0|4211081215] "s" Vector__XXX
 SG_ NxTrkngEngnAtvtLftmEngnRnTmBn3 : 64|32@1+ (1,0) [0|4211081215] "s" Vector__XXX
 SG_ NxTrkngEngnAtvtLftmEngnRnTmBn4 : 96|32@1+ (1,0) [0|4211081215] "s" Vector__XXX
 SG_ NxTrkngEngnAtvtLftmEngnRnTmBn5 : 128|32@1+ (1,0) [0|4211081215] "s" Vector__XXX
 SG_ NxTrkngEngnAtvtLftmEngnRnTmBn6 : 160|32@1+ (1,0) [0|4211081215] "s" Vector__XXX
 SG_ NxTrkngEngnAtvtLftmEngnRnTmBn7 : 192|32@1+ (1,0) [0|4211081215] "s" Vector__XXX
 SG_ NxTrkngEngnAtvtLftmEngnRnTmBn8 : 224|32@1+ (1,0) [0|4211081215] "s" Vector__XXX
 SG_ NxTrkngEngnAtvtLftmEngnRnTmBn9 : 256|32@1+ (1,0) [0|4211081215] "s" Vector__XXX
 SG_ NxTrkngEngnAtvtLftmEngnRnTmBn10 : 288|32@1+ (1,0) [0|4211081215] "s" Vector__XXX
 SG_ NxTrkngEngnAtvtLftmEngnRnTmBn11 : 320|32@1+ (1,0) [0|4211081215] "s" Vector__XXX
 SG_ NxTrkngEngnAtvtLftmEngnRnTmBn12 : 352|32@1+ (1,0) [0|4211081215] "s" Vector__XXX
 SG_ NxTrkngEngnAtvtLftmEngnRnTmBn13 : 384|32@1+ (1,0) [0|4211081215] "s" Vector__XXX
 SG_ NxTrkngEngnAtvtLftmEngnRnTmBn14 : 416|32@1+ (1,0) [0|4211081215] "s" Vector__XXX
 SG_ NxTEAtvtLtERTB15NtB : 448|32@1+ (1,0) [0|4211081215] "s" Vector__XXX
 SG_ NxTEAtvtLtERTB16RB : 480|32@1+ (1,0) [0|4211081215] "s" Vector__XXX
 SG_ NxTEAtvtLtERTB17MOB : 512|32@1+ (1,0) [0|4211081215] "s" Vector__XXX

BO_ 2566587646 NTVMEA: 68 Vector__XXX
 SG_ NxTEAtvtLtVDstB1Tt : 0|32@1+ (5,0) [0|21055406075] "m" Vector__XXX
 SG_ NxTrkngEngnAtvtLftmVhlDstnBn2 : 32|32@1+ (5,0) [0|21055406075] "m" Vector__XXX
 SG_ NxTrkngEngnAtvtLftmVhlDstnBn3 : 64|32@1+ (5,0) [0|21055406075] "m" Vector__XXX
 SG_ NxTrkngEngnAtvtLftmVhlDstnBn4 : 96|32@1+ (5,0) [0|21055406075] "m" Vector__XXX
 SG_ NxTrkngEngnAtvtLftmVhlDstnBn5 : 128|32@1+ (5,0) [0|21055406075] "m" Vector__XXX
 SG_ NxTrkngEngnAtvtLftmVhlDstnBn6 : 160|32@1+ (5,0) [0|21055406075] "m" Vector__XXX
 SG_ NxTrkngEngnAtvtLftmVhlDstnBn7 : 192|32@1+ (5,0) [0|21055406075] "m" Vector__XXX
 SG_ NxTrkngEngnAtvtLftmVhlDstnBn8 : 224|32@1+ (5,0) [0|21055406075] "m" Vector__XXX
 SG_ NxTrkngEngnAtvtLftmVhlDstnBn9 : 256|32@1+ (5,0) [0|21055406075] "m" Vector__XXX
 SG_ NxTrkngEngnAtvtLftmVhlDstnBn10 : 288|32@1+ (5,0) [0|21055406075] "m" Vector__XXX
 SG_ NxTrkngEngnAtvtLftmVhlDstnBn11 : 320|32@1+ (5,0) [0|21055406075] "m" Vector__XXX
 SG_ NxTrkngEngnAtvtLftmVhlDstnBn12 : 352|32@1+ (5,0) [0|21055406075] "m" Vector__XXX
 SG_ NxTrkngEngnAtvtLftmVhlDstnBn13 : 384|32@1+ (5,0) [0|21055406075] "m" Vector__XXX
 SG_ NxTrkngEngnAtvtLftmVhlDstnBn14 : 416|32@1+ (5,0) [0|21055406075] "m" Vector__XXX
 SG_ NxTEAtvtLtVDstB15NtB : 448|32@1+ (5,0) [0|21055406075] "m" Vector__XXX
 SG_ NxTEAtvtLtVDstB16RB : 480|32@1+ (5,0) [0|21055406075] "m" Vector__XXX
 SG_ NxTEAtvtLtVDstB17MOB : 512|32@1+ (5,0) [0|21055406075] "m" Vector__XXX

BO_ 2566587902 NTEEEA: 68 Vector__XXX
 SG_ NxTEAtvtLtEOtptEB1Tt : 0|32@1+ (1,0) [0|4211081215] "kWh" Vector__XXX
 SG_ NxTEAtvtLtEOtptEB2 : 32|32@1+ (1,0) [0|4211081215] "kWh" Vector__XXX
 SG_ NxTEAtvtLtEOtptEB3 : 64|32@1+ (1,0) [0|4211081215] "kWh" Vector__XXX
 SG_ NxTEAtvtLtEOtptEB4 : 96|32@1+ (1,0) [0|4211081215] "kWh" Vector__XXX
 SG_ NxTEAtvtLtEOtptEB5 : 128|32@1+ (1,0) [0|4211081215] "kWh" Vector__XXX
 SG_ NxTEAtvtLtEOtptEB6 : 160|32@1+ (1,0) [0|4211081215] "kWh" Vector__XXX
 SG_ NxTEAtvtLtEOtptEB7 : 192|32@1+ (1,0) [0|4211081215] "kWh" Vector__XXX
 SG_ NxTEAtvtLtEOtptEB8 : 224|32@1+ (1,0) [0|4211081215] "kWh" Vector__XXX
 SG_ NxTEAtvtLtEOtptEB9 : 256|32@1+ (1,0) [0|4211081215] "kWh" Vector__XXX
 SG_ NxTEAtvtLtEOtptEB10 : 288|32@1+ (1,0) [0|4211081215] "kWh" Vector__XXX
 SG_ NxTEAtvtLtEOtptEB11 : 320|32@1+ (1,0) [0|4211081215] "kWh" Vector__XXX
 SG_ NxTEAtvtLtEOtptEB12 : 352|32@1+ (1,0) [0|4211081215] "kWh" Vector__XXX
 SG_ NxTEAtvtLtEOtptEB13 : 384|32@1+ (1,0) [0|4211081215] "kWh" Vector__XXX
 SG_ NxTEAtvtLtEOtptEB14 : 416|32@1+ (1,0) [0|4211081215] "kWh" Vector__XXX
 SG_ NxTEAtvtLtEOtptEB15NtB : 448|32@1+ (1,0) [0|4211081215] "kWh" Vector__XXX
 SG_ NxTEAtvtLtEOtptEB16RB : 480|32@1+ (1,0) [0|4211081215] "kWh" Vector__XXX
 SG_ NxTEAtvtLtEOtptEB17MOB : 512|32@1+ (1,0) [0|4211081215] "kWh" Vector__XXX

BO_ 2566588158 NTFCV: 68 Vector__XXX
 SG_ NxTrkngVldNxLftmFlCnsmptnBn1Ttl : 0|32@1+ (0.05,0) [0|210554060.75] "l" Vector__XXX
 SG_ NxTrkngVldNxLftmFlCnsmptnBn2 : 32|32@1+ (0.05,0) [0|210554060.75] "l" Vector__XXX
 SG_ NxTrkngVldNxLftmFlCnsmptnBn3 : 64|32@1+ (0.05,0) [0|210554060.75] "l" Vector__XXX
 SG_ NxTrkngVldNxLftmFlCnsmptnBn4 : 96|32@1+ (0.05,0) [0|210554060.75] "l" Vector__XXX
 SG_ NxTrkngVldNxLftmFlCnsmptnBn5 : 128|32@1+ (0.05,0) [0|210554060.75] "l" Vector__XXX
 SG_ NxTrkngVldNxLftmFlCnsmptnBn6 : 160|32@1+ (0.05,0) [0|210554060.75] "l" Vector__XXX
 SG_ NxTrkngVldNxLftmFlCnsmptnBn7 : 192|32@1+ (0.05,0) [0|210554060.75] "l" Vector__XXX
 SG_ NxTrkngVldNxLftmFlCnsmptnBn8 : 224|32@1+ (0.05,0) [0|210554060.75] "l" Vector__XXX
 SG_ NxTrkngVldNxLftmFlCnsmptnBn9 : 256|32@1+ (0.05,0) [0|210554060.75] "l" Vector__XXX
 SG_ NxTrkngVldNxLftmFlCnsmptnBn10 : 288|32@1+ (0.05,0) [0|210554060.75] "l" Vector__XXX
 SG_ NxTrkngVldNxLftmFlCnsmptnBn11 : 320|32@1+ (0.05,0) [0|210554060.75] "l" Vector__XXX
 SG_ NxTrkngVldNxLftmFlCnsmptnBn12 : 352|32@1+ (0.05,0) [0|210554060.75] "l" Vector__XXX
 SG_ NxTrkngVldNxLftmFlCnsmptnBn13 : 384|32@1+ (0.05,0) [0|210554060.75] "l" Vector__XXX
 SG_ NxTrkngVldNxLftmFlCnsmptnBn14 : 416|32@1+ (0.05,0) [0|210554060.75] "l" Vector__XXX
 SG_ NxTVdNxLtFCsptB15NtB : 448|32@1+ (0.05,0) [0|210554060.75] "l" Vector__XXX
 SG_ NxTVdNxLtFCsptB16RB : 480|32@1+ (0.05,0) [0|210554060.75] "l" Vector__XXX
 SG_ NxTVdNxLtFCsptB17MOB : 512|32@1+ (0.05,0) [0|210554060.75] "l" Vector__XXX

BO_ 2566588414 NTEHV: 68 Vector__XXX
 SG_ NxTrkngVldNxLftmEngnRnTmBn1Ttl : 0|32@1+ (1,0) [0|4211081215] "s" Vector__XXX
 SG_ NxTrkngVldNxLftmEngnRnTmBn2 : 32|32@1+ (1,0) [0|4211081215] "s" Vector__XXX
 SG_ NxTrkngVldNxLftmEngnRnTmBn3 : 64|32@1+ (1,0) [0|4211081215] "s" Vector__XXX
 SG_ NxTrkngVldNxLftmEngnRnTmBn4 : 96|32@1+ (1,0) [0|4211081215] "s" Vector__XXX
 SG_ NxTrkngVldNxLftmEngnRnTmBn5 : 128|32@1+ (1,0) [0|4211081215] "s" Vector__XXX
 SG_ NxTrkngVldNxLftmEngnRnTmBn6 : 160|32@1+ (1,0) [0|4211081215] "s" Vector__XXX
 SG_ NxTrkngVldNxLftmEngnRnTmBn7 : 192|32@1+ (1,0) [0|4211081215] "s" Vector__XXX
 SG_ NxTrkngVldNxLftmEngnRnTmBn8 : 224|32@1+ (1,0) [0|4211081215] "s" Vector__XXX
 SG_ NxTrkngVldNxLftmEngnRnTmBn9 : 256|32@1+ (1,0) [0|4211081215] "s" Vector__XXX
 SG_ NxTrkngVldNxLftmEngnRnTmBn10 : 288|32@1+ (1,0) [0|4211081215] "s" Vector__XXX
 SG_ NxTrkngVldNxLftmEngnRnTmBn11 : 320|32@1+ (1,0) [0|4211081215] "s" Vector__XXX
 SG_ NxTrkngVldNxLftmEngnRnTmBn12 : 352|32@1+ (1,0) [0|4211081215] "s" Vector__XXX
 SG_ NxTrkngVldNxLftmEngnRnTmBn13 : 384|32@1+ (1,0) [0|4211081215] "s" Vector__XXX
 SG_ NxTrkngVldNxLftmEngnRnTmBn14 : 416|32@1+ (1,0) [0|4211081215] "s" Vector__XXX
 SG_ NxTVdNxLtERTB15NtB : 448|32@1+ (1,0) [0|4211081215] "s" Vector__XXX
 SG_ NxTVdNxLtERTB16RB : 480|32@1+ (1,0) [0|4211081215] "s" Vector__XXX
 SG_ NxTVdNxLtERTB17MOB : 512|32@1+ (1,0) [0|4211081215] "s" Vector__XXX

BO_ 2566588670 NTVMV: 68 Vector__XXX
 SG_ NxTrkngVldNxLftmVhlDstnBn1Ttl : 0|32@1+ (5,0) [0|21055406075] "m" Vector__XXX
 SG_ NxTrkngVldNxLftmVhlDstnBn2 : 32|32@1+ (5,0) [0|21055406075] "m" Vector__XXX
 SG_ NxTrkngVldNxLftmVhlDstnBn3 : 64|32@1+ (5,0) [0|21055406075] "m" Vector__XXX
 SG_ NxTrkngVldNxLftmVhlDstnBn4 : 96|32@1+ (5,0) [0|21055406075] "m" Vector__XXX
 SG_ NxTrkngVldNxLftmVhlDstnBn5 : 128|32@1+ (5,0) [0|21055406075] "m" Vector__XXX
 SG_ NxTrkngVldNxLftmVhlDstnBn6 : 160|32@1+ (5,0) [0|21055406075] "m" Vector__XXX
 SG_ NxTrkngVldNxLftmVhlDstnBn7 : 192|32@1+ (5,0) [0|21055406075] "m" Vector__XXX
 SG_ NxTrkngVldNxLftmVhlDstnBn8 : 224|32@1+ (5,0) [0|21055406075] "m" Vector__XXX
 SG_ NxTrkngVldNxLftmVhlDstnBn9 : 256|32@1+ (5,0) [0|21055406075] "m" Vector__XXX
 SG_ NxTrkngVldNxLftmVhlDstnBn10 : 288|32@1+ (5,0) [0|21055406075] "m" Vector__XXX
 SG_ NxTrkngVldNxLftmVhlDstnBn11 : 320|32@1+ (5,0) [0|21055406075] "m" Vector__XXX
 SG_ NxTrkngVldNxLftmVhlDstnBn12 : 352|32@1+ (5,0) [0|21055406075] "m" Vector__XXX
 SG_ NxTrkngVldNxLftmVhlDstnBn13 : 384|32@1+ (5,0) [0|21055406075] "m" Vector__XXX
 SG_ NxTrkngVldNxLftmVhlDstnBn14 : 416|32@1+ (5,0) [0|21055406075] "m" Vector__XXX
 SG_ NxTrkngVldNxLftmVhlDstnBn15NtBn : 448|32@1+ (5,0) [0|21055406075] "m" Vector__XXX
 SG_ NxTVdNxLtVDstB16RB : 480|32@1+ (5,0) [0|21055406075] "m" Vector__XXX
 SG_ NxTVdNxLtVDstB17MOB : 512|32@1+ (5,0) [0|21055406075] "m" Vector__XXX

BO_ 2566588926 NTEEV: 68 Vector__XXX
 SG_ NxTVdNxLtEOtptEB1Tt : 0|32@1+ (1,0) [0|4211081215] "kWh" Vector__XXX
 SG_ NxTrkngVldNxLftmEngnOtptEnrgBn2 : 32|32@1+ (1,0) [0|4211081215] "kWh" Vector__XXX
 SG_ NxTrkngVldNxLftmEngnOtptEnrgBn3 : 64|32@1+ (1,0) [0|4211081215] "kWh" Vector__XXX
 SG_ NxTrkngVldNxLftmEngnOtptEnrgBn4 : 96|32@1+ (1,0) [0|4211081215] "kWh" Vector__XXX
 SG_ NxTrkngVldNxLftmEngnOtptEnrgBn5 : 128|32@1+ (1,0) [0|4211081215] "kWh" Vector__XXX
 SG_ NxTrkngVldNxLftmEngnOtptEnrgBn6 : 160|32@1+ (1,0) [0|4211081215] "kWh" Vector__XXX
 SG_ NxTrkngVldNxLftmEngnOtptEnrgBn7 : 192|32@1+ (1,0) [0|4211081215] "kWh" Vector__XXX
 SG_ NxTrkngVldNxLftmEngnOtptEnrgBn8 : 224|32@1+ (1,0) [0|4211081215] "kWh" Vector__XXX
 SG_ NxTrkngVldNxLftmEngnOtptEnrgBn9 : 256|32@1+ (1,0) [0|4211081215] "kWh" Vector__XXX
 SG_ NxTVdNxLtEOtptEB10 : 288|32@1+ (1,0) [0|4211081215] "kWh" Vector__XXX
 SG_ NxTVdNxLtEOtptEB11 : 320|32@1+ (1,0) [0|4211081215] "kWh" Vector__XXX
 SG_ NxTVdNxLtEOtptEB12 : 352|32@1+ (1,0) [0|4211081215] "kWh" Vector__XXX
 SG_ NxTVdNxLtEOtptEB13 : 384|32@1+ (1,0) [0|4211081215] "kWh" Vector__XXX
 SG_ NxTVdNxLtEOtptEB14 : 416|32@1+ (1,0) [0|4211081215] "kWh" Vector__XXX
 SG_ NxTVdNxLtEOtptEB15NtB : 448|32@1+ (1,0) [0|4211081215] "kWh" Vector__XXX
 SG_ NxTVdNxLtEOtptEB16RB : 480|32@1+ (1,0) [0|4211081215] "kWh" Vector__XXX
 SG_ NxTVdNxLtEOtptEB17MOB : 512|32@1+ (1,0) [0|4211081215] "kWh" Vector__XXX

BO_ 2566589182 NTENV: 68 Vector__XXX
 SG_ NxTVdNxLtEOtNxMssB1Tt : 0|32@1+ (1,0) [0|4211081215] "g" Vector__XXX
 SG_ NxTrkngVldNxLftmEngnOtNxMssBn2 : 32|32@1+ (1,0) [0|4211081215] "g" Vector__XXX
 SG_ NxTrkngVldNxLftmEngnOtNxMssBn3 : 64|32@1+ (1,0) [0|4211081215] "g" Vector__XXX
 SG_ NxTrkngVldNxLftmEngnOtNxMssBn4 : 96|32@1+ (1,0) [0|4211081215] "g" Vector__XXX
 SG_ NxTrkngVldNxLftmEngnOtNxMssBn5 : 128|32@1+ (1,0) [0|4211081215] "g" Vector__XXX
 SG_ NxTrkngVldNxLftmEngnOtNxMssBn6 : 160|32@1+ (1,0) [0|4211081215] "g" Vector__XXX
 SG_ NxTrkngVldNxLftmEngnOtNxMssBn7 : 192|32@1+ (1,0) [0|4211081215] "g" Vector__XXX
 SG_ NxTrkngVldNxLftmEngnOtNxMssBn8 : 224|32@1+ (1,0) [0|4211081215] "g" Vector__XXX
 SG_ NxTrkngVldNxLftmEngnOtNxMssBn9 : 256|32@1+ (1,0) [0|4211081215] "g" Vector__XXX
 SG_ NxTrkngVldNxLftmEngnOtNxMssBn10 : 288|32@1+ (1,0) [0|4211081215] "g" Vector__XXX
 SG_ NxTrkngVldNxLftmEngnOtNxMssBn11 : 320|32@1+ (1,0) [0|4211081215] "g" Vector__XXX
 SG_ NxTrkngVldNxLftmEngnOtNxMssBn12 : 352|32@1+ (1,0) [0|4211081215] "g" Vector__XXX
 SG_ NxTrkngVldNxLftmEngnOtNxMssBn13 : 384|32@1+ (1,0) [0|4211081215] "g" Vector__XXX
 SG_ NxTrkngVldNxLftmEngnOtNxMssBn14 : 416|32@1+ (1,0) [0|4211081215] "g" Vector__XXX
 SG_ NxTVdNxLtEOtNxMssB15NtB : 448|32@1+ (1,0) [0|4211081215] "g" Vector__XXX
 SG_ NxTVdNxLtEOtNxMssB16RB : 480|32@1+ (1,0) [0|4211081215] "g" Vector__XXX
 SG_ NxTVdNxLtEOtNxMssB17MOB : 512|32@1+ (1,0) [0|4211081215] "g" Vector__XXX

BO_ 2566589438 NTSNV: 68 Vector__XXX
 SG_ NxTVdNxLtSstOtNxMssB1Tt : 0|32@1+ (1,0) [0|4211081215] "g" Vector__XXX
 SG_ NxTrkngVldNxLftmSstmOtNxMssBn2 : 32|32@1+ (1,0) [0|4211081215] "g" Vector__XXX
 SG_ NxTrkngVldNxLftmSstmOtNxMssBn3 : 64|32@1+ (1,0) [0|4211081215] "g" Vector__XXX
 SG_ NxTrkngVldNxLftmSstmOtNxMssBn4 : 96|32@1+ (1,0) [0|4211081215] "g" Vector__XXX
 SG_ NxTrkngVldNxLftmSstmOtNxMssBn5 : 128|32@1+ (1,0) [0|4211081215] "g" Vector__XXX
 SG_ NxTrkngVldNxLftmSstmOtNxMssBn6 : 160|32@1+ (1,0) [0|4211081215] "g" Vector__XXX
 SG_ NxTrkngVldNxLftmSstmOtNxMssBn7 : 192|32@1+ (1,0) [0|4211081215] "g" Vector__XXX
 SG_ NxTrkngVldNxLftmSstmOtNxMssBn8 : 224|32@1+ (1,0) [0|4211081215] "g" Vector__XXX
 SG_ NxTrkngVldNxLftmSstmOtNxMssBn9 : 256|32@1+ (1,0) [0|4211081215] "g" Vector__XXX
 SG_ NxTrkngVldNxLftmSstmOtNxMssBn10 : 288|32@1+ (1,0) [0|4211081215] "g" Vector__XXX
 SG_ NxTrkngVldNxLftmSstmOtNxMssBn11 : 320|32@1+ (1,0) [0|4211081215] "g" Vector__XXX
 SG_ NxTrkngVldNxLftmSstmOtNxMssBn12 : 352|32@1+ (1,0) [0|4211081215] "g" Vector__XXX
 SG_ NxTrkngVldNxLftmSstmOtNxMssBn13 : 384|32@1+ (1,0) [0|4211081215] "g" Vector__XXX
 SG_ NxTrkngVldNxLftmSstmOtNxMssBn14 : 416|32@1+ (1,0) [0|4211081215] "g" Vector__XXX
 SG_ NxTVdNxLtSstOtNxMssB15NtB : 448|32@1+ (1,0) [0|4211081215] "g" Vector__XXX
 SG_ NxTVdNxLtSstOtNxMssB16RB : 480|32@1+ (1,0) [0|4211081215] "g" Vector__XXX
 SG_ NxTVdNxLtSstOtNxMssB17MOB : 512|32@1+ (1,0) [0|4211081215] "g" Vector__XXX

BO_ 2566589694 NTFCS: 34 Vector__XXX
 SG_ NxTrkngStrd100HrFlCnsmptnBn1Ttl : 0|16@1+ (0.5,0) [0|32127.5] "l" Vector__XXX
 SG_ NxTrkngStrd100HrFlCnsmptnBn2 : 16|16@1+ (0.5,0) [0|32127.5] "l" Vector__XXX
 SG_ NxTrkngStrd100HrFlCnsmptnBn3 : 32|16@1+ (0.5,0) [0|32127.5] "l" Vector__XXX
 SG_ NxTrkngStrd100HrFlCnsmptnBn4 : 48|16@1+ (0.5,0) [0|32127.5] "l" Vector__XXX
 SG_ NxTrkngStrd100HrFlCnsmptnBn5 : 64|16@1+ (0.5,0) [0|32127.5] "l" Vector__XXX
 SG_ NxTrkngStrd100HrFlCnsmptnBn6 : 80|16@1+ (0.5,0) [0|32127.5] "l" Vector__XXX
 SG_ NxTrkngStrd100HrFlCnsmptnBn7 : 96|16@1+ (0.5,0) [0|32127.5] "l" Vector__XXX
 SG_ NxTrkngStrd100HrFlCnsmptnBn8 : 112|16@1+ (0.5,0) [0|32127.5] "l" Vector__XXX
 SG_ NxTrkngStrd100HrFlCnsmptnBn9 : 128|16@1+ (0.5,0) [0|32127.5] "l" Vector__XXX
 SG_ NxTrkngStrd100HrFlCnsmptnBn10 : 144|16@1+ (0.5,0) [0|32127.5] "l" Vector__XXX
 SG_ NxTrkngStrd100HrFlCnsmptnBn11 : 160|16@1+ (0.5,0) [0|32127.5] "l" Vector__XXX
 SG_ NxTrkngStrd100HrFlCnsmptnBn12 : 176|16@1+ (0.5,0) [0|32127.5] "l" Vector__XXX
 SG_ NxTrkngStrd100HrFlCnsmptnBn13 : 192|16@1+ (0.5,0) [0|32127.5] "l" Vector__XXX
 SG_ NxTrkngStrd100HrFlCnsmptnBn14 : 208|16@1+ (0.5,0) [0|32127.5] "l" Vector__XXX
 SG_ NxTStd100HFCsptB15NtB : 224|16@1+ (0.5,0) [0|32127.5] "l" Vector__XXX
 SG_ NxTStd100HFCsptB16RB : 240|16@1+ (0.5,0) [0|32127.5] "l" Vector__XXX
 SG_ NxTStd100HFCsptB17MOB : 256|16@1+ (0.5,0) [0|32127.5] "l" Vector__XXX

BO_ 2566589950 NTEHS: 34 Vector__XXX
 SG_ NxTrkngStrd100HrEngnRnTmBn1Ttl : 0|16@1+ (10,0) [0|642550] "s" Vector__XXX
 SG_ NxTrkngStrd100HrEngnRnTmBn2 : 16|16@1+ (10,0) [0|642550] "s" Vector__XXX
 SG_ NxTrkngStrd100HrEngnRnTmBn3 : 32|16@1+ (10,0) [0|642550] "s" Vector__XXX
 SG_ NxTrkngStrd100HrEngnRnTmBn4 : 48|16@1+ (10,0) [0|642550] "s" Vector__XXX
 SG_ NxTrkngStrd100HrEngnRnTmBn5 : 64|16@1+ (10,0) [0|642550] "s" Vector__XXX
 SG_ NxTrkngStrd100HrEngnRnTmBn6 : 80|16@1+ (10,0) [0|642550] "s" Vector__XXX
 SG_ NxTrkngStrd100HrEngnRnTmBn7 : 96|16@1+ (10,0) [0|642550] "s" Vector__XXX
 SG_ NxTrkngStrd100HrEngnRnTmBn8 : 112|16@1+ (10,0) [0|642550] "s" Vector__XXX
 SG_ NxTrkngStrd100HrEngnRnTmBn9 : 128|16@1+ (10,0) [0|642550] "s" Vector__XXX
 SG_ NxTrkngStrd100HrEngnRnTmBn10 : 144|16@1+ (10,0) [0|642550] "s" Vector__XXX
 SG_ NxTrkngStrd100HrEngnRnTmBn11 : 160|16@1+ (10,0) [0|642550] "s" Vector__XXX
 SG_ NxTrkngStrd100HrEngnRnTmBn12 : 176|16@1+ (10,0) [0|642550] "s" Vector__XXX
 SG_ NxTrkngStrd100HrEngnRnTmBn13 : 192|16@1+ (10,0) [0|642550] "s" Vector__XXX
 SG_ NxTrkngStrd100HrEngnRnTmBn14 : 208|16@1+ (10,0) [0|642550] "s" Vector__XXX
 SG_ NxTStd100HERTB15NtB : 224|16@1+ (10,0) [0|642550] "s" Vector__XXX
 SG_ NxTStd100HERTB16RB : 240|16@1+ (10,0) [0|642550] "s" Vector__XXX
 SG_ NxTStd100HERTB17MOB : 256|16@1+ (10,0) [0|642550] "s" Vector__XXX

BO_ 2566590206 NTVMS: 34 Vector__XXX
 SG_ NxTrkngStrd100HrVhlDstnBn1Ttl : 0|16@1+ (0.25,0) [0|16063.75] "km" Vector__XXX
 SG_ NxTrkngStrd100HrVhlDstnBn2 : 16|16@1+ (0.25,0) [0|16063.75] "km" Vector__XXX
 SG_ NxTrkngStrd100HrVhlDstnBn3 : 32|16@1+ (0.25,0) [0|16063.75] "km" Vector__XXX
 SG_ NxTrkngStrd100HrVhlDstnBn4 : 48|16@1+ (0.25,0) [0|16063.75] "km" Vector__XXX
 SG_ NxTrkngStrd100HrVhlDstnBn5 : 64|16@1+ (0.25,0) [0|16063.75] "km" Vector__XXX
 SG_ NxTrkngStrd100HrVhlDstnBn6 : 80|16@1+ (0.25,0) [0|16063.75] "km" Vector__XXX
 SG_ NxTrkngStrd100HrVhlDstnBn7 : 96|16@1+ (0.25,0) [0|16063.75] "km" Vector__XXX
 SG_ NxTrkngStrd100HrVhlDstnBn8 : 112|16@1+ (0.25,0) [0|16063.75] "km" Vector__XXX
 SG_ NxTrkngStrd100HrVhlDstnBn9 : 128|16@1+ (0.25,0) [0|16063.75] "km" Vector__XXX
 SG_ NxTrkngStrd100HrVhlDstnBn10 : 144|16@1+ (0.25,0) [0|16063.75] "km" Vector__XXX
 SG_ NxTrkngStrd100HrVhlDstnBn11 : 160|16@1+ (0.25,0) [0|16063.75] "km" Vector__XXX
 SG_ NxTrkngStrd100HrVhlDstnBn12 : 176|16@1+ (0.25,0) [0|16063.75] "km" Vector__XXX
 SG_ NxTrkngStrd100HrVhlDstnBn13 : 192|16@1+ (0.25,0) [0|16063.75] "km" Vector__XXX
 SG_ NxTrkngStrd100HrVhlDstnBn14 : 208|16@1+ (0.25,0) [0|16063.75] "km" Vector__XXX
 SG_ NxTrkngStrd100HrVhlDstnBn15NtBn : 224|16@1+ (0.25,0) [0|16063.75] "km" Vector__XXX
 SG_ NxTStd100HVDstB16RB : 240|16@1+ (0.25,0) [0|16063.75] "km" Vector__XXX
 SG_ NxTStd100HVDstB17MOB : 256|16@1+ (0.25,0) [0|16063.75] "km" Vector__XXX

CM_ BO_ 2565995006 "Motor/Generator 5 Inverter Limits Active Power";
CM_ SG_ 2565995006 MtrGnrtr5InvrtrLmtsAtvPwrCntr "Motor/Generator 5 Inverter Limits Active Power Counter: The message counter is used to detect situations where the transmitting ECU malfunction repeats the same frame all the time. The receiver of the information may use the counter parameter to dete...";
CM_ SG_ 2565995006 MtGt5IvtLtsAtvMPwMx "Motor/Generator 5 Inverter Limits Active Mechanical Power Maximum: The inverter keeps the mechanical motor power below this value.   This limit may be set in response to a Limits Request or determined by the inverter based on operating conditions.Ref...";
CM_ SG_ 2565995006 MtGt5IvtLtsAtvMPwM "Motor/Generator 5 Inverter Limits Active Mechanical Power Minimum: The inverter keeps the mechanical motor power above this value.   This limit may be set in response to a Limits Request or determined by the inverter based on operating conditions.Ref...";
CM_ SG_ 2565995006 MtrGnrtr5InvrtrLmtsAtvPwrCr "Motor/Generator 5 Inverter Limits Active Power CRC: The CRC is defined as follows: - Length: 8 bits- Polynomial: x^8+x^5+x^3+x^2+x+1- Initial Value: FFh- Input Data Reflection: Not reflected- Result Data Reflection: Not reflected- XOR value: FFh SAE ...";
CM_ SG_ 2565995006 MtGt5IvtLtsAtvDSdPwMx "Motor/Generator 5 Inverter Limits Active DC Side Power Maximum: The inverter keeps the DC Side power below this value.   This limit may be set in response to a Limits Request or determined by the inverter based on operating conditions.Refer to SPN 12...";
CM_ SG_ 2565995006 MtGt5IvtLtsAtvDSdPwM "Motor/Generator 5 Inverter Limits Active DC Side Power Minimum: The inverter keeps the DC side power above this value.   This limit may be set in response to a Limits Request or determined by the inverter based on operating conditions.Refer to SPN 12...";
CM_ BO_ 2565995262 "Motor/Generator 5 Inverter Limits Active Mechanical";
CM_ SG_ 2565995262 MtrGnrtr5InvrtrLmtsAtvMhnlCntr "Motor/Generator 5 Inverter Limits Active Mechanical Counter: The message counter is used to detect situations where the transmitting ECU malfunction repeats the same frame all the time. The receiver of the information may use the counter parameter to...";
CM_ SG_ 2565995262 MtrGnrtr5InvrtrLmtsAtvTrqMxmm "Motor/Generator 5 Inverter Limits Active Torque Maximum: The inverter keeps the motor torque below this value.  This limit may be set in response to a Limits Request or determined by the inverter based on operating conditions.Refer to SPN 12057 [Refe...";
CM_ SG_ 2565995262 MtrGnrtr5InvrtrLmtsAtvTrqMnmm "Motor/Generator 5 Inverter Limits Active Torque Minimum: The inverter keeps the motor torque above this value.  This limit may be set in response to a Limits Request or determined by the inverter based on operating conditions.Refer to SPN 12057 [Refe...";
CM_ SG_ 2565995262 MtrGnrtr5InvrtrLmtsAtvSpdMxmm "Motor/Generator 5 Inverter Limits Active Speed Maximum: The inverter keeps the motor speed below this value.  This limit may be set in response to a Limits Request or determined by the inverter based on operating conditions.Refer to SPN 12058 [Refere...";
CM_ SG_ 2565995262 MtrGnrtr5InvrtrLmtsAtvSpdMnmm "Motor/Generator 5 Inverter Limits Active Speed Minimum: The inverter keeps the motor Speed above this value.  This limit may be set in response to a Limits Request or determined by the inverter based on operating conditions.Refer to SPN 12058 [Refere...";
CM_ SG_ 2565995262 MtrGnrtr5InvrtrLmtsAtvMhnlCr "Motor/Generator 5 Inverter Limits Active Mechanical CRC: The CRC is defined as follows: - Length: 8 bits- Polynomial: x^8+x^5+x^3+x^2+x+1- Initial Value: FFh- Input Data Reflection: Not reflected- Result Data Reflection: Not reflected- XOR value: FFh...";
CM_ BO_ 2565995518 "Motor/Generator 5 Inverter Limits Active DC Side";
CM_ SG_ 2565995518 MtrGnrtr5InvrtrLmtsAtvDSdCr "Motor/Generator 5 Inverter Limits Active DC Side CRC: The CRC is defined as follows: - Length: 8 bits- Polynomial: x^8+x^5+x^3+x^2+x+1- Initial Value: FFh- Input Data Reflection: Not reflected- Result Data Reflection: Not reflected- XOR value: FFh SA...";
CM_ SG_ 2565995518 MtrGnrtr5InvrtrLmtsAtvDSdCntr "Motor/Generator 5 Inverter Limits Active DC Side Counter: The message counter is used to detect situations where the transmitting ECU malfunction repeats the same frame all the time. The receiver of the information may use the counter parameter to de...";
CM_ SG_ 2565995518 MtGt5IvtLtsAtvDSdVtMx "Motor/Generator 5 Inverter Limits Active DC Side Voltage Maximum: The inverter keeps the DC side voltage below this value.  This limit may be set in response to a Limits Request or determined by the inverter based on operating conditions.Refer to SPN...";
CM_ SG_ 2565995518 MtGt5IvtLtsAtvDSdVtM "Motor/Generator 5 Inverter Limits Active DC Side Voltage Minimum: The inverter keeps the DC side voltage above this value.  This limit may be set in response to a Limits Request or determined by the inverter based on operating conditions.Refer to SPN...";
CM_ SG_ 2565995518 MtGt5IvtLtsAtvDSdCtMx "Motor/Generator 5 Inverter Limits Active DC Side Current Maximum: The inverter keeps the DC side current below this value.  This limit may be set in response to a Limits Request or determined by the inverter based on operating conditions. Refer to SP...";
CM_ SG_ 2565995518 MtGt5IvtLtsAtvDSdCtM "Motor/Generator 5 Inverter Limits Active DC Side Current Minimum: The inverter keeps the DC side current above this value.  This limit may be set in response to a Limits Request or determined by the inverter based on operating conditions.Refer to SPN...";
CM_ BO_ 2565995774 "Motor/Generator 5 Inverter Low Voltage";
CM_ SG_ 2565995774 MtrGnrtr5InvrtrSwthdIgntnVltg "Motor/Generator 5 Inverter Switched Ignition Voltage: Switched Ignition voltage supplied to this instance of the inverter controller.";
CM_ SG_ 2565995774 MtrGnrtr5InvrtrUnswthdSlVltg "Motor/Generator 5 Inverter Unswitched SLI Voltage: Continuously supplied SLI power to this instance of the inverter controller.";
CM_ BO_ 2565996030 "Motor/Generator 5 Inverter Status 2";
CM_ SG_ 2565996030 MtrGnrtr5InvrtrStts2Cntr "Motor/Generator 5 Inverter Status 2 Counter: The message counter is used to detect situations where the transmitting ECU malfunction repeats the same frame all the time. The receiver of the information may use the counter parameter to detect this sit...";
CM_ SG_ 2565996030 MtrGnrtr5AvllMxmmTrq "Motor/Generator 5 Available Maximum Torque: This is an estimate of the maximum available motor torque including active deratings at the present motor speed.  This refers to the motor rotor output and excludes any gearbox that may be attached to the m...";
CM_ SG_ 2565996030 MtrGnrtr5AvllMnmmTrq "Motor/Generator 5 Available Minimum Torque: This is an estimate of the minimum available motor torque including active deratings at the present motor speed.  This refers to the motor rotor output and excludes any gearbox that may be attached to the m...";
CM_ SG_ 2565996030 MtrGnrtr5InvrtrStts2Cr "Motor/Generator 5 Inverter Status 2 CRC: The CRC is defined as follows: - Length: 8 bits- Polynomial: x^8+x^5+x^3+x^2+x+1- Initial Value: FFh- Input Data Reflection: Not reflected- Result Data Reflection: Not reflected- XOR value: FFh SAE makes no cl...";
CM_ BO_ 2565996286 "Motor/Generator 5 Inverter Rate Limits Active 1";
CM_ SG_ 2565996286 MtrGnrtr5InvrtrRtLmtsAtv1Cntr "Motor/Generator 5 Inverter Rate Limits Active 1 Counter: The message counter is used to detect situations where the transmitting ECU malfunction repeats the same frame all the time. The receiver of the information may use the counter parameter to det...";
CM_ SG_ 2565996286 MtGt5IvtRtLtsAtvAstSpdRtLt "Motor/Generator 5 Inverter Rate Limits Active Absolute Speed Rate Limit: The active maximum rate of change for the absolute motor speed  (i.e. |d(speed)|/dt) in all control modes of this motor/generator inverter instance. Refer to SPN 12058 [Referenc...";
CM_ SG_ 2565996286 MtGt5IvtRtLtsAtvAstTqRtLt "Motor/Generator 5 Inverter Rate Limits Active Absolute Torque Rate Limit: The active maximum rate of change for the absolute motor torque (i.e. |d(torque)|/dt) in all control modes of this motor/generator inverter instance. Refer to SPN 12057 [Refere...";
CM_ SG_ 2565996286 MtrGnrtr5InvrtrRtLmtsAtv1Cr "Motor/Generator 5 Inverter Rate Limits Active 1 CRC: The CRC is defined as follows: - Length: 8 bits- Polynomial: x^8+x^5+x^3+x^2+x+1- Initial Value: FFh- Input Data Reflection: Not reflected- Result Data Reflection: Not reflected- XOR value: FFh SAE...";
CM_ BO_ 2364669950 "Motor/Generator 6 Inverter Mode Feedback 1";
CM_ SG_ 2364669950 MtrGnrtr6InvrtrMdFdk1Cntr "Motor/Generator 6 Inverter Mode Feedback 1 Counter: The message counter is used to detect situations where the transmitting ECU malfunction repeats the same frame all the time. The receiver of the information may use the counter parameter to detect t...";
CM_ SG_ 2364669950 MtrGnrtr6InvrtrCntrlLmtsOvrrdMd "Motor/Generator 6 Inverter Control Limits Override Mode: During normal operation this will have the same value as SPN 12164 [Control Limits Request Override Mode].  0 = Operating limits are not overridden.  If a limit was previously active, then it h...";
CM_ SG_ 2364669950 MtrGnrtr6InvrtrCntrlStpntMd "Motor/Generator 6 Inverter Control Setpoint Mode: Reports the inverter mode (See SPN 12167 [Control Setpoint Mode Request] for requested mode).Passive modes:  0 = Powered On - the inverter is commanded to be powered on and able to communicate, but th...";
CM_ SG_ 2364669950 MtrGnrtr6InvrtrMdFdk1Cr "Motor/Generator 6 Inverter Mode Feedback 1 CRC: The CRC is defined as follows: - Length: 8 bits- Polynomial: x^8+x^5+x^3+x^2+x+1- Initial Value: FFh- Input Data Reflection: Not reflected- Result Data Reflection: Not reflected- XOR value: FFh SAE make...";
CM_ SG_ 2364669950 MtrGnrtr6InvrtrHvlStts "Motor/Generator 6 Inverter HVIL Status: Reports the High Voltage Interlock Loop (HVIL) state.00b = HVIL Closed01b = HVIL Open10b = Error11b = Not Available";
CM_ BO_ 2565996798 "Motor/Generator 6 Inverter Limits Active Power";
CM_ SG_ 2565996798 MtrGnrtr6InvrtrLmtsAtvPwrCntr "Motor/Generator 6 Inverter Limits Active Power Counter: The message counter is used to detect situations where the transmitting ECU malfunction repeats the same frame all the time. The receiver of the information may use the counter parameter to dete...";
CM_ SG_ 2565996798 MtGt6IvtLtsAtvMPwMx "Motor/Generator 6 Inverter Limits Active Mechanical Power Maximum: The inverter keeps the mechanical motor power below this value.   This limit may be set in response to a Limits Request or determined by the inverter based on operating conditions.Ref...";
CM_ SG_ 2565996798 MtGt6IvtLtsAtvMPwM "Motor/Generator 6 Inverter Limits Active Mechanical Power Minimum: The inverter keeps the mechanical motor power above this value.   This limit may be set in response to a Limits Request or determined by the inverter based on operating conditions.Ref...";
CM_ SG_ 2565996798 MtrGnrtr6InvrtrLmtsAtvPwrCr "Motor/Generator 6 Inverter Limits Active Power CRC: The CRC is defined as follows: - Length: 8 bits- Polynomial: x^8+x^5+x^3+x^2+x+1- Initial Value: FFh- Input Data Reflection: Not reflected- Result Data Reflection: Not reflected- XOR value: FFh SAE ...";
CM_ SG_ 2565996798 MtGt6IvtLtsAtvDSdPwMx "Motor/Generator 6 Inverter Limits Active DC Side Power Maximum: The inverter keeps the DC Side power below this value.   This limit may be set in response to a Limits Request or determined by the inverter based on operating conditions.Refer to SPN 12...";
CM_ SG_ 2565996798 MtGt6IvtLtsAtvDSdPwM "Motor/Generator 6 Inverter Limits Active DC Side Power Minimum: The inverter keeps the DC side power above this value.   This limit may be set in response to a Limits Request or determined by the inverter based on operating conditions.Refer to SPN 12...";
CM_ BO_ 2565997054 "Motor/Generator 6 Inverter Limits Active Mechanical";
CM_ SG_ 2565997054 MtrGnrtr6InvrtrLmtsAtvMhnlCntr "Motor/Generator 6 Inverter Limits Active Mechanical Counter: The message counter is used to detect situations where the transmitting ECU malfunction repeats the same frame all the time. The receiver of the information may use the counter parameter to...";
CM_ SG_ 2565997054 MtrGnrtr6InvrtrLmtsAtvTrqMxmm "Motor/Generator 6 Inverter Limits Active Torque Maximum: The inverter keeps the motor torque below this value.  This limit may be set in response to a Limits Request or determined by the inverter based on operating conditions.Refer to SPN 12175 [Refe...";
CM_ SG_ 2565997054 MtrGnrtr6InvrtrLmtsAtvTrqMnmm "Motor/Generator 6 Inverter Limits Active Torque Minimum: The inverter keeps the motor torque above this value.  This limit may be set in response to a Limits Request or determined by the inverter based on operating conditions.Refer to SPN 12175 [Refe...";
CM_ SG_ 2565997054 MtrGnrtr6InvrtrLmtsAtvSpdMxmm "Motor/Generator 6 Inverter Limits Active Speed Maximum: The inverter keeps the motor speed below this value.  This limit may be set in response to a Limits Request or determined by the inverter based on operating conditions.Refer to SPN 12176 [Refere...";
CM_ SG_ 2565997054 MtrGnrtr6InvrtrLmtsAtvSpdMnmm "Motor/Generator 6 Inverter Limits Active Speed Minimum: The inverter keeps the motor Speed above this value.  This limit may be set in response to a Limits Request or determined by the inverter based on operating conditions.Refer to SPN 12176 [Refere...";
CM_ SG_ 2565997054 MtrGnrtr6InvrtrLmtsAtvMhnlCr "Motor/Generator 6 Inverter Limits Active Mechanical CRC: The CRC is defined as follows: - Length: 8 bits- Polynomial: x^8+x^5+x^3+x^2+x+1- Initial Value: FFh- Input Data Reflection: Not reflected- Result Data Reflection: Not reflected- XOR value: FFh...";
CM_ BO_ 2565997310 "Motor/Generator 6 Inverter Limits Active DC Side";
CM_ SG_ 2565997310 MtrGnrtr6InvrtrLmtsAtvDSdCr "Motor/Generator 6 Inverter Limits Active DC Side CRC: The CRC is defined as follows: - Length: 8 bits- Polynomial: x^8+x^5+x^3+x^2+x+1- Initial Value: FFh- Input Data Reflection: Not reflected- Result Data Reflection: Not reflected- XOR value: FFh SA...";
CM_ SG_ 2565997310 MtrGnrtr6InvrtrLmtsAtvDSdCntr "Motor/Generator 6 Inverter Limits Active DC Side Counter: The message counter is used to detect situations where the transmitting ECU malfunction repeats the same frame all the time. The receiver of the information may use the counter parameter to de...";
CM_ SG_ 2565997310 MtGt6IvtLtsAtvDSdVtMx "Motor/Generator 6 Inverter Limits Active DC Side Voltage Maximum: The inverter keeps the DC side voltage below this value.  This limit may be set in response to a Limits Request or determined by the inverter based on operating conditions.Refer to SPN...";
CM_ SG_ 2565997310 MtGt6IvtLtsAtvDSdVtM "Motor/Generator 6 Inverter Limits Active DC Side Voltage Minimum: The inverter keeps the DC side voltage above this value.  This limit may be set in response to a Limits Request or determined by the inverter based on operating conditions.Refer to SPN...";
CM_ SG_ 2565997310 MtGt6IvtLtsAtvDSdCtMx "Motor/Generator 6 Inverter Limits Active DC Side Current Maximum: The inverter keeps the DC side current below this value.  This limit may be set in response to a Limits Request or determined by the inverter based on operating conditions. Refer to SP...";
CM_ SG_ 2565997310 MtGt6IvtLtsAtvDSdCtM "Motor/Generator 6 Inverter Limits Active DC Side Current Minimum: The inverter keeps the DC side current above this value.  This limit may be set in response to a Limits Request or determined by the inverter based on operating conditions.Refer to SPN...";
CM_ BO_ 2565997566 "Motor/Generator 6 Inverter Low Voltage";
CM_ SG_ 2565997566 MtrGnrtr6InvrtrSwthdIgntnVltg "Motor/Generator 6 Inverter Switched Ignition Voltage: Switched Ignition voltage supplied to this instance of the inverter controller.";
CM_ SG_ 2565997566 MtrGnrtr6InvrtrUnswthdSlVltg "Motor/Generator 6 Inverter Unswitched SLI Voltage: Continuously supplied SLI power to this instance of the inverter controller.";
CM_ BO_ 2565997822 "Motor/Generator 6 Inverter Status 2";
CM_ SG_ 2565997822 MtrGnrtr6InvrtrStts2Cntr "Motor/Generator 6 Inverter Status 2 Counter: The message counter is used to detect situations where the transmitting ECU malfunction repeats the same frame all the time. The receiver of the information may use the counter parameter to detect this sit...";
CM_ SG_ 2565997822 MtrGnrtr6AvllMxmmTrq "Motor/Generator 6 Available Maximum Torque: This is an estimate of the maximum available motor torque including active deratings at the present motor speed.  This refers to the motor rotor output and excludes any gearbox that may be attached to the m...";
CM_ SG_ 2565997822 MtrGnrtr6AvllMnmmTrq "Motor/Generator 6 Available Minimum Torque: This is an estimate of the minimum available motor torque including active deratings at the present motor speed.  This refers to the motor rotor output and excludes any gearbox that may be attached to the m...";
CM_ SG_ 2565997822 MtrGnrtr6InvrtrStts2Cr "Motor/Generator 6 Inverter Status 2 CRC: The CRC is defined as follows: - Length: 8 bits- Polynomial: x^8+x^5+x^3+x^2+x+1- Initial Value: FFh- Input Data Reflection: Not reflected- Result Data Reflection: Not reflected- XOR value: FFh SAE makes no cl...";
CM_ BO_ 2565998078 "Motor/Generator 6 Inverter Rate Limits Active 1";
CM_ SG_ 2565998078 MtrGnrtr6InvrtrRtLmtsAtv1Cntr "Motor/Generator 6 Inverter Rate Limits Active 1 Counter: The message counter is used to detect situations where the transmitting ECU malfunction repeats the same frame all the time. The receiver of the information may use the counter parameter to det...";
CM_ SG_ 2565998078 MtGt6IvtRtLtsAtvAstSpdRtLt "Motor/Generator 6 Inverter Rate Limits Active Absolute Speed Rate Limit: The active maximum rate of change for the absolute motor speed  (i.e. |d(speed)|/dt) in all control modes of this motor/generator inverter instance. Refer to SPN 12176 [Referenc...";
CM_ SG_ 2565998078 MtGt6IvtRtLtsAtvAstTqRtLt "Motor/Generator 6 Inverter Rate Limits Active Absolute Torque Rate Limit: The active maximum rate of change for the absolute motor torque (i.e. |d(torque)|/dt) in all control modes of this motor/generator inverter instance. Refer to SPN 12175 [Refere...";
CM_ SG_ 2565998078 MtrGnrtr6InvrtrRtLmtsAtv1Cr "Motor/Generator 6 Inverter Rate Limits Active 1 CRC: The CRC is defined as follows: - Length: 8 bits- Polynomial: x^8+x^5+x^3+x^2+x+1- Initial Value: FFh- Input Data Reflection: Not reflected- Result Data Reflection: Not reflected- XOR value: FFh SAE...";
CM_ BO_ 2364671742 "Blind Spot Detection 1";
CM_ SG_ 2364671742 BlindSpotDetectionState "Blind Spot Detection State: Current operational state of the blind spot detection function. 0000b = system is not ready (initialization not finished) 0001b = system is temporarily not available (e.g. due to boundary conditions necessary for operation...";
CM_ SG_ 2364671742 BlindSpotCollisionWarningLevel "Blind Spot Collision Warning Level: To implement different human machine interface (HMI) concepts, e.g. visual only, visual/audible, different warning tones etc., the object detection provides different levels of collision warning. 0000b = no warning...";
CM_ SG_ 2364671742 BlndSptWrnngRlvntOjtDttd "Blind Spot Warning Relevant Object Detected: Indication if the blind spot detection system (BSD) is monitoring a relevant object.000b = No relevant object monitored 001b = Single relevant object is being monitored 010b = Multiple relevant objects are...";
CM_ SG_ 2364671742 BlndSptDttnLftSdMntrd "Blind Spot Detection Left Side Monitored: Indicates if left side area is monitored by the blind spot detection system. This signal can be used to trigger the correct warning(s) in the human machine interface (HMI).00b = Not being monitored 01b = Moni...";
CM_ SG_ 2364671742 BlndSptDttnRghtSdMntrd "Blind Spot Detection Right Side Monitored: Indicates if right side area is monitored by the blind spot detection system. This signal can be used to trigger the correct warning(s) in the human machine interface (HMI).00b = Not being monitored 01b = Mo...";
CM_ SG_ 2364671742 BlndSptDttnFrntMntrd "Blind Spot Detection Front Monitored: Indicates if front area is monitored by the blind spot detection system. This signal can be used to trigger the correct warning(s) in the human machine interface (HMI).00b = Not being monitored 01b = Monitored10b...";
CM_ SG_ 2364671742 BlindSpotDetectionRearMonitored "Blind Spot Detection Rear Monitored: Indicates if rear area is monitored by the blind spot detection system. This signal can be used to trigger the correct warning(s) in the human machine interface (HMI).00b = Not being monitored 01b = Monitored10b =...";
CM_ SG_ 2364671742 BndOffPrltOfMstImprtntOjt "Bend-Off Probability of Most Important Object: Probabilty if the most important monitored relevant object might start a bend-off maneuver (e.g. turning), which could clear the travelling path of the host vehicle. 000b = no indication for a bend-off m...";
CM_ BO_ 2364671998 "Winch Information 1";
CM_ SG_ 2364671998 WinchMotorEncoderPosition "Winch Motor Encoder Position: Angular position of the winch motor shaft where 0 represents the initial position, with the value incrementing up to 32767 before rolling over to 0 at one complete revolution.  Likewise, the value decrements for reverse ...";
CM_ SG_ 2364671998 WinchRevolutionCounter "Winch Revolution Counter: Count of complete revolutions since reset. Value increments in forward direction and decrements in reverse direction.";
CM_ SG_ 2364671998 WinchMotorSpeed "Winch Motor Speed: Rotational speed of the winch motor.";
CM_ SG_ 2364671998 WinchMotorDirection "Winch Motor Direction: Direction of rotation of the winch motor as viewed from the motor end of the winch looking into the gearbox/drum.00b = CounterClockWise (CCW)01b = ClockWise (CW)10b = Unknown (Rotation Direction Unknown)11b = Not AvailableNote:...";
CM_ SG_ 2364671998 WinchMotorOverspeed "Winch Motor Overspeed: Indicates whether the winch motor is exceeding the recommended maximum speed.00b = No overspeed01b = Overspeed10b = Error11b = Not available";
CM_ BO_ 2364672254 "Motor/Generator 3 Inverter Control";
CM_ SG_ 2364672254 MtrGnrtr3InvrtrCntrlCntr "Motor/Generator 3 Inverter Control Counter: The message counter is used to detect situations where the transmitting ECU malfunction repeats the same frame all the time. The receiver of the information may use the counter parameter to detect this situ...";
CM_ SG_ 2364672254 MtGt3IvtCtLtsRqstOvdMd "Motor/Generator 3 Inverter Control Limits Request Override Mode: This parameter provides a way to temporarily override limits that are being received by the inverter in other messages.  It allows a specific type of limit to be transmitted at a high r...";
CM_ SG_ 2364672254 MtGt3IvtCtLtsRqstOvdMx "Motor/Generator 3 Inverter Control Limits Request Override Maximum: The Maximum limit requested by this parameter depends on the value of SPN 11810 [Control Limits Request Override Mode].In normal operating conditions, the inverter operating limits a...";
CM_ SG_ 2364672254 MtGt3IvtCtLtsRqstOvdM "Motor/Generator 3 Inverter Control Limits Request Override Minimum : The Minimum limit requested by this parameter depends on the value of SPN 11810 [Control Limits Request Override Mode].In normal operating conditions, the inverter operating limits ...";
CM_ SG_ 2364672254 MtrGnrtr3InvrtrCntrlStpntMdRqst "Motor/Generator 3 Inverter Control Setpoint Mode Request: Requests the modes for this instance of the inverter.  See SPN 11818 [Control Setpoint Mode] for the feedback to this request.Passive modes:  Modes where the inverter does not actively control...";
CM_ SG_ 2364672254 MtrGnrtr3InvrtrCntrlStpntRqst "Motor/Generator 3 Inverter Control Setpoint Request: Requests the set point for this inverter.  The type of set point requested by this parameter depends on the value of SPN 11813 [Control Setpoint Mode Request] as follows:Passive Modes: In any Passi...";
CM_ SG_ 2364672254 MtrGnrtr3InvrtrCntrlCr "Motor/Generator 3 Inverter Control CRC: The CRC is defined as follows: - Length: 8 bits- Polynomial: x^8+x^5+x^3+x^2+x+1- Initial Value: FFh- Input Data Reflection: Not reflected- Result Data Reflection: Not reflected- XOR value: FFh SAE makes no cla...";
CM_ BO_ 2565999102 "Motor/Generator 3 Inverter Rate Limits Request 1";
CM_ SG_ 2565999102 MtrGnrtr3InvrtrRtLmtsRqst1Cntr "Motor/Generator 3 Inverter Rate Limits Request 1 Counter: The message counter is used to detect situations where the transmitting ECU malfunction repeats the same frame all the time. The receiver of the information may use the counter parameter to de...";
CM_ SG_ 2565999102 MtGt3IvtRtLtsRqstAstSpdRtLt "Motor/Generator 3 Inverter Rate Limits Request Absolute Speed Rate Limit: The maximum rate of change for the absolute motor speed  (i.e. |d(speed)|/dt) in all control modes. This limit shall solely lead to reducing the absolute torque, not increasing...";
CM_ SG_ 2565999102 MtGt3IvtRtLtsRqstAstTqRtLt "Motor/Generator 3 Inverter Rate Limits Request Absolute Torque Rate Limit: The maximum rate of change for the absolute motor torque (i.e. |d(torque)|/dt) in all control modes. Refer to SPN 11821 [Reference Torque] to convert %/sec to Nm/sec. Request ...";
CM_ SG_ 2565999102 MtrGnrtr3InvrtrRtLmtsRqst1Cr "Motor/Generator 3 Inverter Rate Limits Request 1 CRC: The CRC is defined as follows: - Length: 8 bits- Polynomial: x^8+x^5+x^3+x^2+x+1- Initial Value: FFh- Input Data Reflection: Not reflected- Result Data Reflection: Not reflected- XOR value: FFh SA...";
CM_ BO_ 2364672766 "Motor/Generator 4 Inverter Control";
CM_ SG_ 2364672766 MtrGnrtr4InvrtrCntrlCntr "Motor/Generator 4 Inverter Control Counter: The message counter is used to detect situations where the transmitting ECU malfunction repeats the same frame all the time. The receiver of the information may use the counter parameter to detect this situ...";
CM_ SG_ 2364672766 MtGt4IvtCtLtsRqstOvdMd "Motor/Generator 4 Inverter Control Limits Request Override Mode: This parameter provides a way to temporarily override limits that are being received by the inverter in other messages.  It allows a specific type of limit to be transmitted at a high r...";
CM_ SG_ 2364672766 MtGt4IvtCtLtsRqstOvdMx "Motor/Generator 4 Inverter Control Limits Request Override Maximum: The Maximum limit requested by this parameter depends on the value of SPN 11928 [Control Limits Request Override Mode].In normal operating conditions, the inverter operating limits a...";
CM_ SG_ 2364672766 MtGt4IvtCtLtsRqstOvdM "Motor/Generator 4 Inverter Control Limits Request Override Minimum : The Minimum limit requested by this parameter depends on the value of SPN 11928 [Control Limits Request Override Mode].In normal operating conditions, the inverter operating limits ...";
CM_ SG_ 2364672766 MtrGnrtr4InvrtrCntrlStpntMdRqst "Motor/Generator 4 Inverter Control Setpoint Mode Request: Requests the modes for this instance of the inverter.  See SPN 11936 [Control Setpoint Mode] for the feedback to this request.Passive modes:  Modes where the inverter does not actively control...";
CM_ SG_ 2364672766 MtrGnrtr4InvrtrCntrlStpntRqst "Motor/Generator 4 Inverter Control Setpoint Request: Requests the set point for this inverter.  The type of set point requested by this parameter depends on the value of SPN 11931 [Control Setpoint Mode Request] as follows:Passive Modes: In any Passi...";
CM_ SG_ 2364672766 MtrGnrtr4InvrtrCntrlCr "Motor/Generator 4 Inverter Control CRC: The CRC is defined as follows: - Length: 8 bits- Polynomial: x^8+x^5+x^3+x^2+x+1- Initial Value: FFh- Input Data Reflection: Not reflected- Result Data Reflection: Not reflected- XOR value: FFh SAE makes no cla...";
CM_ BO_ 2565999614 "Motor/Generator 4 Inverter Rate Limits Request 1";
CM_ SG_ 2565999614 MtrGnrtr4InvrtrRtLmtsRqst1Cntr "Motor/Generator 4 Inverter Rate Limits Request 1 Counter: The message counter is used to detect situations where the transmitting ECU malfunction repeats the same frame all the time. The receiver of the information may use the counter parameter to de...";
CM_ SG_ 2565999614 MtGt4IvtRtLtsRqstAstSpdRtLt "Motor/Generator 4 Inverter Rate Limits Request Absolute Speed Rate Limit: The maximum rate of change for the absolute motor speed  (i.e. |d(speed)|/dt) in all control modes. This limit shall solely lead to reducing the absolute torque, not increasing...";
CM_ SG_ 2565999614 MtGt4IvtRtLtsRqstAstTqRtLt "Motor/Generator 4 Inverter Rate Limits Request Absolute Torque Rate Limit: The maximum rate of change for the absolute motor torque (i.e. |d(torque)|/dt) in all control modes. Refer to SPN 11939 [Reference Torque] to convert %/sec to Nm/sec. Request ...";
CM_ SG_ 2565999614 MtrGnrtr4InvrtrRtLmtsRqst1Cr "Motor/Generator 4 Inverter Rate Limits Request 1 CRC: The CRC is defined as follows: - Length: 8 bits- Polynomial: x^8+x^5+x^3+x^2+x+1- Initial Value: FFh- Input Data Reflection: Not reflected- Result Data Reflection: Not reflected- XOR value: FFh SA...";
CM_ BO_ 2364673278 "Motor/Generator 5 Inverter Control";
CM_ SG_ 2364673278 MtrGnrtr5InvrtrCntrlCntr "Motor/Generator 5 Inverter Control Counter: The message counter is used to detect situations where the transmitting ECU malfunction repeats the same frame all the time. The receiver of the information may use the counter parameter to detect this situ...";
CM_ SG_ 2364673278 MtGt5IvtCtLtsRqstOvdMd "Motor/Generator 5 Inverter Control Limits Request Override Mode: This parameter provides a way to temporarily override limits that are being received by the inverter in other messages.  It allows a specific type of limit to be transmitted at a high r...";
CM_ SG_ 2364673278 MtGt5IvtCtLtsRqstOvdMx "Motor/Generator 5 Inverter Control Limits Request Override Maximum: The Maximum limit requested by this parameter depends on the value of SPN 12046 [Control Limits Request Override Mode].In normal operating conditions, the inverter operating limits a...";
CM_ SG_ 2364673278 MtGt5IvtCtLtsRqstOvdM "Motor/Generator 5 Inverter Control Limits Request Override Minimum : The Minimum limit requested by this parameter depends on the value of SPN 12046 [Control Limits Request Override Mode].In normal operating conditions, the inverter operating limits ...";
CM_ SG_ 2364673278 MtrGnrtr5InvrtrCntrlStpntMdRqst "Motor/Generator 5 Inverter Control Setpoint Mode Request: Requests the modes for this instance of the inverter.  See SPN 12054 [Control Setpoint Mode] for the feedback to this request.Passive modes:  Modes where the inverter does not actively control...";
CM_ SG_ 2364673278 MtrGnrtr5InvrtrCntrlStpntRqst "Motor/Generator 5 Inverter Control Setpoint Request: Requests the set point for this inverter.  The type of set point requested by this parameter depends on the value of SPN 12049 [Control Setpoint Mode Request] as follows:Passive Modes: In any Passi...";
CM_ SG_ 2364673278 MtrGnrtr5InvrtrCntrlCr "Motor/Generator 5 Inverter Control CRC: The CRC is defined as follows: - Length: 8 bits- Polynomial: x^8+x^5+x^3+x^2+x+1- Initial Value: FFh- Input Data Reflection: Not reflected- Result Data Reflection: Not reflected- XOR value: FFh SAE makes no cla...";
CM_ BO_ 2566000126 "Motor/Generator 5 Inverter Rate Limits Request 1";
CM_ SG_ 2566000126 MtrGnrtr5InvrtrRtLmtsRqst1Cntr "Motor/Generator 5 Inverter Rate Limits Request 1 Counter: The message counter is used to detect situations where the transmitting ECU malfunction repeats the same frame all the time. The receiver of the information may use the counter parameter to de...";
CM_ SG_ 2566000126 MtGt5IvtRtLtsRqstAstSpdRtLt "Motor/Generator 5 Inverter Rate Limits Request Absolute Speed Rate Limit: The maximum rate of change for the absolute motor speed  (i.e. |d(speed)|/dt) in all control modes. This limit shall solely lead to reducing the absolute torque, not increasing...";
CM_ SG_ 2566000126 MtGt5IvtRtLtsRqstAstTqRtLt "Motor/Generator 5 Inverter Rate Limits Request Absolute Torque Rate Limit: The maximum rate of change for the absolute motor torque (i.e. |d(torque)|/dt) in all control modes. Refer to SPN 12057 [Reference Torque] to convert %/sec to Nm/sec. Request ...";
CM_ SG_ 2566000126 MtrGnrtr5InvrtrRtLmtsRqst1Cr "Motor/Generator 5 Inverter Rate Limits Request 1 CRC: The CRC is defined as follows: - Length: 8 bits- Polynomial: x^8+x^5+x^3+x^2+x+1- Initial Value: FFh- Input Data Reflection: Not reflected- Result Data Reflection: Not reflected- XOR value: FFh SA...";
CM_ BO_ 2364673790 "Motor/Generator 6 Inverter Control";
CM_ SG_ 2364673790 MtrGnrtr6InvrtrCntrlCntr "Motor/Generator 6 Inverter Control Counter: The message counter is used to detect situations where the transmitting ECU malfunction repeats the same frame all the time. The receiver of the information may use the counter parameter to detect this situ...";
CM_ SG_ 2364673790 MtGt6IvtCtLtsRqstOvdMd "Motor/Generator 6 Inverter Control Limits Request Override Mode: This parameter provides a way to temporarily override limits that are being received by the inverter in other messages.  It allows a specific type of limit to be transmitted at a high r...";
CM_ SG_ 2364673790 MtGt6IvtCtLtsRqstOvdMx "Motor/Generator 6 Inverter Control Limits Request Override Maximum: The Maximum limit requested by this parameter depends on the value of SPN 12164 [Control Limits Request Override Mode].In normal operating conditions, the inverter operating limits a...";
CM_ SG_ 2364673790 MtGt6IvtCtLtsRqstOvdM "Motor/Generator 6 Inverter Control Limits Request Override Minimum : The Minimum limit requested by this parameter depends on the value of SPN 12164 [Control Limits Request Override Mode].In normal operating conditions, the inverter operating limits ...";
CM_ SG_ 2364673790 MtrGnrtr6InvrtrCntrlStpntMdRqst "Motor/Generator 6 Inverter Control Setpoint Mode Request: Requests the modes for this instance of the inverter.  See SPN 12172 [Control Setpoint Mode] for the feedback to this request.Passive modes:  Modes where the inverter does not actively control...";
CM_ SG_ 2364673790 MtrGnrtr6InvrtrCntrlStpntRqst "Motor/Generator 6 Inverter Control Setpoint Request: Requests the set point for this inverter.  The type of set point requested by this parameter depends on the value of SPN 12167 [Control Setpoint Mode Request] as follows:Passive Modes: In any Passi...";
CM_ SG_ 2364673790 MtrGnrtr6InvrtrCntrlCr "Motor/Generator 6 Inverter Control CRC: The CRC is defined as follows: - Length: 8 bits- Polynomial: x^8+x^5+x^3+x^2+x+1- Initial Value: FFh- Input Data Reflection: Not reflected- Result Data Reflection: Not reflected- XOR value: FFh SAE makes no cla...";
CM_ BO_ 2566000638 "Motor/Generator 6 Inverter Rate Limits Request 1";
CM_ SG_ 2566000638 MtrGnrtr6InvrtrRtLmtsRqst1Cntr "Motor/Generator 6 Inverter Rate Limits Request 1 Counter: The message counter is used to detect situations where the transmitting ECU malfunction repeats the same frame all the time. The receiver of the information may use the counter parameter to de...";
CM_ SG_ 2566000638 MtGt6IvtRtLtsRqstAstSpdRtLt "Motor/Generator 6 Inverter Rate Limits Request Absolute Speed Rate Limit: The maximum rate of change for the absolute motor speed  (i.e. |d(speed)|/dt) in all control modes. This limit shall solely lead to reducing the absolute torque, not increasing...";
CM_ SG_ 2566000638 MtGt6IvtRtLtsRqstAstTqRtLt "Motor/Generator 6 Inverter Rate Limits Request Absolute Torque Rate Limit: The maximum rate of change for the absolute motor torque (i.e. |d(torque)|/dt) in all control modes. Refer to SPN 12175 [Reference Torque] to convert %/sec to Nm/sec. Request ...";
CM_ SG_ 2566000638 MtrGnrtr6InvrtrRtLmtsRqst1Cr "Motor/Generator 6 Inverter Rate Limits Request 1 CRC: The CRC is defined as follows: - Length: 8 bits- Polynomial: x^8+x^5+x^3+x^2+x+1- Initial Value: FFh- Input Data Reflection: Not reflected- Result Data Reflection: Not reflected- XOR value: FFh SA...";
CM_ BO_ 2566574078 "EVCC Diagnostic Data 1";
CM_ SG_ 2566574078 EvccControlPilotMaximumVoltage "EVCC Control Pilot maximum voltage: The control pilot from the off-board EVSE is either a DC signal or a square wave. This parameter contains the DC value or the maximum voltage of the square wave.";
CM_ SG_ 2566574078 EvccControlPilotMinimumVoltage "EVCC Control Pilot minimum voltage: The control pilot from the off-board EVSE is either a DC signal or a square wave. This parameter contains the DC value or the minimum voltage of the square wave.";
CM_ SG_ 2566574078 EvccControlPilotPwmFrequency "EVCC Control Pilot PWM frequency: The control pilot from the off-board EVSE is either a DC signal or a square wave. This parameter contains either zero when a DC value or the frequency when a square wave.";
CM_ SG_ 2566574078 EvccControlPilotDutyCycle "EVCC Control Pilot Duty Cycle: The control pilot from the off-board EVSE is either a DC signal or a square wave. This parameter contains the duty cycle of the PWM square wave. ";
CM_ SG_ 2566574078 EvccControlPilotState "EVCC Control Pilot State: Indicates the EVSE state as determined by the peak voltage level of the Control Pilot and representing states A to F as defined by IEC-61851 and J1772.0000b = State A, EVSE Disconnected0001b = State B, EVSE Connected, Power ...";
CM_ SG_ 2566574078 EvccControlPilotSubState "EVCC Control Pilot Sub-State: Indicates the EVSE sub-state as determined by the frequency of the Control Pilot as defined by IEC-61851 and J1772.0000b = Sub-state 1 - DC Level, EVSE not ready/able to enable power0001b = Sub-state 2 - Valid PWM, EVSE ...";
CM_ SG_ 2566574078 EvccProximityCircuitVoltage "EVCC Proximity circuit voltage: The cable from the EVSE may contain a resistive proximity circuit.  Resistors are built into both the cable and inlet sides of the connectors and are supplied from a DC source.The voltage interpretation will depend on ...";
CM_ SG_ 2566574078 EvccInletConnectorTemperature "EVCC Inlet connector temperature: Temperature reading at the vehicle inlet connector.";
CM_ SG_ 2566574078 EvccCompatibilityCode "EVCC Compatibility Code: Indicates incompatability between the vehicle and the EVSE.0000b = EVSE is compatible0001b = Digital Communications. The EVSE has attempted to establish commuications but the protocol is not supported by the EVCC.0010b = Vent...";
CM_ BO_ 2499465470 "Cab Door Control 2";
CM_ SG_ 2499465470 Mirror1LeftRightSelection "Mirror 1 Left/Right Selection: Indicates the position of a switch that selects between left or right mirror control. Signal may be used to provide visual indication of selected mirror.000b = No Mirror Selected (Neutral Position)001b = Mirror 1 Left S...";
CM_ SG_ 2499465470 Mirror2LeftRightSelection "Mirror 2 Left/Right Selection: Indicates the position of a switch that selects between left or right mirror control. Signal may be used to provide visual indication of selected mirror.000b = No Mirror Selected (Neutral Position)001b = Mirror 2 Left S...";
CM_ SG_ 2499465470 MirrorPrimarySecondarySelection "Mirror Primary/Secondary Selection: Indicates the position of a switch that selects between primary and secondary mirror sets. Signal may be used to provide visual indication of selected mirror.000b = No Mirror Selected (Neutral Position)001b = Prima...";
CM_ BO_ 2499465726 "Engine Average Information 2";
CM_ SG_ 2499465726 EngnClndrTmprtrAvrg "Engine Cylinder Temperature Average: The calculated average temperature based upon all of the engine cylinder temperatures measured at the head of each cylinder. This is the average temperature based upon the measurements in each of the engine cylind...";
CM_ SG_ 2499465726 EngnClndrBnk1TmprtrAvrg "Engine Cylinder Bank 1 Temperature Average: The calculated average temperature based upon all of the Bank 1 (left bank) engine cylinders measured at the head of each cylinder. This is the average temperature measurement of each of the engine cylinder...";
CM_ SG_ 2499465726 EngnClndrBnk2TmprtrAvrg "Engine Cylinder Bank 2 Temperature Average: The calculated average temperature based upon all of the Bank 2 (right bank) engine cylinders measured at the head of each cylinder. This is the average temperature measurement of each of the engine cylinde...";
CM_ BO_ 2566574846 "Turbocharger Information 9";
CM_ SG_ 2566574846 EngnTrhrgr3OlTmprtr "Engine Turbocharger 3 Oil Temperature: Temperature of the lubricant for the third turbocharger.";
CM_ SG_ 2566574846 EngnTrhrgr4OlTmprtr "Engine Turbocharger 4 Oil Temperature: Temperature of the lubricant for the fourth turbocharger.";
CM_ SG_ 2566574846 EngnTrhrgr5OlTmprtr "Engine Turbocharger 5 Oil Temperature: Temperature of the lubricant for the fifth turbocharger.";
CM_ SG_ 2566574846 EngnTrhrgr6OlTmprtr "Engine Turbocharger 6 Oil Temperature: Temperature of the lubricant for the sixth turbocharger.";
CM_ BO_ 2566575102 "Automated Driving System Control 1";
CM_ SG_ 2566575102 Ts1CntrlPrpsP7InhtCmmnd "TSC1 Control Purpose P7 Inhibit Command: Signal which indicates sending TSC1 Control Purpose P7 is inhibited or not. Devices shall not send TSC1 Control Purpose P7 when the received SPN 12868 (TSC1 Control Purpose P7 Inhibit Command) is 01b. If those...";
CM_ SG_ 2566575102 AdsVehicleSpeedControlConsent "ADS Vehicle Speed Control Consent: Indicates the consent for ADS Vehicle Speed Control Command (SPN 15248) of the automated driving system (ADS)Devices shall not send ADS Vehicle Speed Control Command when ADS Vehicle Speed Control Consent (SPN 15247...";
CM_ SG_ 2566575102 Adsc1EmbeddedIntegritySupport "ADSC1 Embedded Integrity Support: Indicates that SPN 22267 (ADSC1 CRC) and SPN 22266 (ADSC1 Counter) are supported by the sender.00b = ADSC1 embedded CRC and Counter are supported by the sender01b = ADSC1 protection is provided using an external (not...";
CM_ SG_ 2566575102 Adsc1Counter "ADSC1 Counter: The message counter is used to detect situations where the transmitting ECU malfunction repeats the same frame all the time. The receiver of the information may use the counter parameter to detect this situation. The transmitting devic...";
CM_ SG_ 2566575102 Adsc1Crc "ADSC1 CRC: The CRC is defined as follows:- Length: 8 bits- Polynomial: x^8+x^5+x^3+x^2+x+1- Initial Value: FFh- Input Data Reflection: Not reflected- Result Data Reflection: Not reflected- XOR value: FFhSAE makes no claim of the functional safety lev...";
CM_ BO_ 2566575358 "EVSE AC Status 2";
CM_ SG_ 2566575358 EvseAcRmsCurrent "EVSE AC RMS Current: AC RMS current being drawn from the EVSE.Negative values indicate power being drained from the vehicle and returned to the grid.";
CM_ SG_ 2566575358 EvseAcRmsVoltage "EVSE AC RMS Voltage: AC RMS Voltage of this connected EVSE supply.";
CM_ BO_ 2566575614 "EVSE AC Status 1";
CM_ SG_ 2566575614 EvseAcRmsCurrentLimitL1 "EVSE AC RMS Current Limit L1: Maximum AC RMS current that can be supplied by the EVSE on a single phase AC supply or L1 of a 3-phase AC supply.";
CM_ SG_ 2566575614 EvseAcRmsCurrentLimitL2 "EVSE AC RMS Current Limit L2: Maximum AC RMS current that can be supplied by the EVSE on L2 of a 3-phase AC supply.";
CM_ SG_ 2566575614 EvseAcRmsCurrentLimitL3 "EVSE AC RMS Current Limit L3: Maximum AC RMS current that can be supplied by the EVSE on L3 of a 3-phase AC supply.";
CM_ SG_ 2566575614 EvseAcRmsCurrentLimitNeutral "EVSE AC RMS Current Limit Neutral: Maximum AC RMS current that can carried on the neutral connection from the EVSE.If this parameter is set to 0 A then only symmetrical 3-phase operation is allowed.";
CM_ BO_ 2566575870 "EVSE Status 1";
CM_ SG_ 2566575870 EvseConnectorReleaseLatch "EVSE Connector Release Latch: Indicates the Release Latch status of this EVSE Connector.SAE J1772 and IEC-61851-1 describes a momentary push-to-break switch (S3) that will be opened when the Release Latch is operated prior to removal of the connector...";
CM_ SG_ 2566575870 EvseManualOverride "EVSE Manual Override: Indicates the state of a manual override switch on the vehicle, if present. The switch may be used to disable charging and unlock the the connector.00b = Manual override not active01b = Manual override active10b = Error11b = Not...";
CM_ SG_ 2566575870 EvseConnectorLockState "EVSE Connector Lock State: Indicates the state of this EVSE Connector Lock (if present).000b = Unlocked001b = Locked010b = In transition to/from Locked011b = Reserved100b = Reserved101b = No locking mechanism is available on this vehicle110b = Error1...";
CM_ SG_ 2566575870 EvseConnectorLockPermission "EVSE Connector Lock Permission: Indicates whether the connector lock is currently able to be controlled by EVSE Connector Lock Request, SPN 12864.This SP should be used in conjunction with the EVSE Connector Lock State, SPN 12863.Some charging standa...";
CM_ SG_ 2566575870 InletContactorState "Inlet Contactor State: The state of the contactors fitted to this power inlet.If the EVCC controls contactors fitted to its associated power inlet then this SP shall report their state.00b = Contactor Open01b = Contactor Closed10b = Error - Contactor...";
CM_ SG_ 2566575870 EvseInletState "EVSE Inlet State: Overall state for this EVSE power connection.For systems that support multiple concurrently active power connections, this SP shall be used instead of SPN 7890 in PGN 32768 (HSC1).Validating: Indicates that there is a new connection...";
CM_ SG_ 2566575870 EvseConnectionType "EVSE Connection Type: Indicates the type of the connected EVSE.If the CA only supports one type of EVSE this SP may be statically set to the appropriate value.  For systems that support multiple concurrently active connections this SP must be used in...";
CM_ SG_ 2566575870 EvseCommunicationsPhysicalLayer "EVSE Communications Physical Layer: Type of communications established with the EVSE.0000b = Protocol yet to be determined0001b = Control Pilot PWM (e.g. as used by single phase AC systems)0010b = LIN Bus (e.g. as used by 3-phase systems supporting J...";
CM_ BO_ 2566581758 "Temperature Sensing Module 1";
CM_ SG_ 2566581758 TmprtrSnsngMdl1PrlmnrFm "Temperature Sensing Module 1 Preliminary FMI: Used to identify the applicable J1939-73 FMI detected in the Temperature Sensing Module 1 by the manufacturer's software. When there are multiple failures, the most severe is transmitted.  A value of 31 i...";
CM_ SG_ 2566581758 TmprtrSnsngMdl2PrlmnrFm "Temperature Sensing Module 2 Preliminary FMI: Used to identify the applicable J1939-73 FMI detected in the Temperature Sensing Module 2 by the manufacturer's software. When there are multiple failures, the most severe is transmitted.  A value of 31 i...";
CM_ SG_ 2566581758 TmprtrSnsngMdl3PrlmnrFm "Temperature Sensing Module 3 Preliminary FMI: Used to identify the applicable J1939-73 FMI detected in the Temperature Sensing Module 3 by the manufacturer's software. When there are multiple failures, the most severe is transmitted.  A value of 31 i...";
CM_ SG_ 2566581758 TmprtrSnsngMdl4PrlmnrFm "Temperature Sensing Module 4 Preliminary FMI: Used to identify the applicable J1939-73 FMI detected in the Temperature Sensing Module 4 by the manufacturer's software. When there are multiple failures, the most severe is transmitted.  A value of 31 i...";
CM_ SG_ 2566581758 TmprtrSnsngMdl5PrlmnrFm "Temperature Sensing Module 5 Preliminary FMI: Used to identify the applicable J1939-73 FMI detected in the Temperature Sensing Module 5 by the manufacturer's software. When there are multiple failures, the most severe is transmitted.  A value of 31 i...";
CM_ SG_ 2566581758 TmprtrSnsngMdl6PrlmnrFm "Temperature Sensing Module 6 Preliminary FMI: Used to identify the applicable J1939-73 FMI detected in the Temperature Sensing Module 6 by the manufacturer's software. When there are multiple failures, the most severe is transmitted.  A value of 31 i...";
CM_ SG_ 2566581758 TmprtrSnsngMdl7PrlmnrFm "Temperature Sensing Module 7 Preliminary FMI: Used to identify the applicable J1939-73 FMI detected in the Temperature Sensing Module 7 by the manufacturer's software. When there are multiple failures, the most severe is transmitted.  A value of 31 i...";
CM_ SG_ 2566581758 TmprtrSnsngMdl8PrlmnrFm "Temperature Sensing Module 8 Preliminary FMI: Used to identify the applicable J1939-73 FMI detected in the Temperature Sensing Module 8 by the manufacturer's software. When there are multiple failures, the most severe is transmitted.  A value of 31 i...";
CM_ BO_ 2566582014 "Temperature Sensing Module 2";
CM_ SG_ 2566582014 TmprtrSnsngMdl9PrlmnrFm "Temperature Sensing Module 9 Preliminary FMI: Used to identify the applicable J1939-73 FMI detected in the Temperature Sensing Module 9 by the manufacturer's software. When there are multiple failures, the most severe is transmitted.  A value of 31 i...";
CM_ SG_ 2566582014 TmprtrSnsngMdl10PrlmnrFm "Temperature Sensing Module 10 Preliminary FMI: Used to identify the applicable J1939-73 FMI detected in the Temperature Sensing Module 10 by the manufacturer's software. When there are multiple failures, the most severe is transmitted.  A value of 31...";
CM_ SG_ 2566582014 TmprtrSnsngMdl11PrlmnrFm "Temperature Sensing Module 11 Preliminary FMI: Used to identify the applicable J1939-73 FMI detected in the Temperature Sensing Module 11 by the manufacturer's software. When there are multiple failures, the most severe is transmitted.  A value of 31...";
CM_ SG_ 2566582014 TmprtrSnsngMdl12PrlmnrFm "Temperature Sensing Module 12 Preliminary FMI: Used to identify the applicable J1939-73 FMI detected in the Temperature Sensing Module 12 by the manufacturer's software. When there are multiple failures, the most severe is transmitted.  A value of 31...";
CM_ SG_ 2566582014 TmprtrSnsngMdl13PrlmnrFm "Temperature Sensing Module 13 Preliminary FMI: Used to identify the applicable J1939-73 FMI detected in the Temperature Sensing Module 13 by the manufacturer's software. When there are multiple failures, the most severe is transmitted.  A value of 31...";
CM_ SG_ 2566582014 TmprtrSnsngMdl14PrlmnrFm "Temperature Sensing Module 14 Preliminary FMI: Used to identify the applicable J1939-73 FMI detected in the Temperature Sensing Module 14 by the manufacturer's software. When there are multiple failures, the most severe is transmitted.  A value of 31...";
CM_ SG_ 2566582014 TmprtrSnsngMdl15PrlmnrFm "Temperature Sensing Module 15 Preliminary FMI: Used to identify the applicable J1939-73 FMI detected in the Temperature Sensing Module 15 by the manufacturer's software. When there are multiple failures, the most severe is transmitted.  A value of 31...";
CM_ SG_ 2566582014 TmprtrSnsngMdl16PrlmnrFm "Temperature Sensing Module 16 Preliminary FMI: Used to identify the applicable J1939-73 FMI detected in the Temperature Sensing Module 16 by the manufacturer's software. When there are multiple failures, the most severe is transmitted.  A value of 31...";
CM_ BO_ 2566582270 "Aftertreatment 2 SCR Service Information 3";
CM_ SG_ 2566582270 Aftrtrtmnt2SrNrmlzdCnvrsnEffn "Aftertreatment 2 SCR Normalized Conversion Efficiency: The ratio of measured SCR Catalyst conversion efficiency to the estimated nominal SCR Catalyst conversion efficiency, represented as a percentage.";
CM_ BO_ 2566582526 "Aftertreatment 1 SCR Service Information 3";
CM_ SG_ 2566582526 Aftrtrtmnt1SrNrmlzdCnvrsnEffn "Aftertreatment 1 SCR Normalized Conversion Efficiency: The ratio of measured SCR Catalyst conversion efficiency to the estimated nominal SCR Catalyst conversion efficiency, represented as a percentage.";
CM_ SG_ 2566582526 Atttt1DsExstFdUsdTsOptC "Aftertreatment 1 Diesel Exhaust Fluid Used This Operating Cycle: Total amount of DEF used by aftertreatment device 1 over the current operating cycle (from engine start to engine start).Note: See SPN 12748 for total accumulation of aftertreatment dev...";
CM_ BO_ 2566582782 "PSA Times Lifetime Hours";
CM_ SG_ 2566582782 HrdLftmPrplsnSstmAtvTm "Hybrid Lifetime Propulsion System Active Time : Total propulsion system active time during the lifetime of the vehicle. OBD requires all hybrids to support this parameter. ";
CM_ SG_ 2566582782 HrdLftmIdlPrplsnSstmAtvTm "Hybrid Lifetime Idle Propulsion System Active Time : Total idle propulsion system active time (v <= 1.6 km/h) during the lifetime of the vehicle. OBD requires all hybrids to support this parameter.";
CM_ SG_ 2566582782 HrdLftmUrnPrplsnSstmAtvTm "Hybrid Lifetime Urban Propulsion System Active Time : Total urban (1.6 km/h < v <= 60 km/h) propulsion system active time during the lifetime of the vehicle. OBD requires all hybrids to support this parameter.";
CM_ BO_ 2566583038 "PSA Times Stored 100 Hours";
CM_ SG_ 2566583038 HrdStrd100HrRntPrplsnSstmAtvTm "Hybrid Stored 100 Hour Recent Propulsion System Active Time : Most recent stored cumulative propulsion system active time during 100 hours of vehicle operation. OBD requires all hybrids to support this parameter. ";
CM_ SG_ 2566583038 HrdStrd100HrIdlPrplsnSstmAtvTm "Hybrid Stored 100 Hour Idle Propulsion System Active Time: Most recent stored cumulative idle (v <= 1.6 km/h) propulsion system active time during 100 hours of vehicle operation. OBD requires all hybrids to support this parameter.";
CM_ SG_ 2566583038 HrdStrd100HrUrnPrplsnSstmAtvTm "Hybrid Stored 100 Hour Urban Propulsion System Active Time : Most recent stored cumulative urban (1.6 km/h < v <= 60 km/h) propulsion system active time during 100 hours of vehicle operation. OBD requires all hybrids to support this parameter.";
CM_ BO_ 2566583294 "PSA Times Active 100 Hours";
CM_ SG_ 2566583294 HrdAtv100HrPrplsnSstmAtvTm "Hybrid Active 100 Hour Propulsion System Active Time : Cumulative propulsion system active time during recent operation (time < 100 hours). OBD requires all hybrids to support this parameter.";
CM_ SG_ 2566583294 HrdAtv100HrIdlPrplsnSstmAtvTm "Hybrid Active 100 Hour Idle Propulsion System Active Time : Cumulative idle (v <= 1.6 km/h) propulsion system active time during recent operation (time < 100 hours). OBD requires all hybrids to support this parameter.";
CM_ SG_ 2566583294 HrdAtv100HrUrnPrplsnSstmAtvTm "Hybrid Active 100 Hour Urban Propulsion System Active Time : Cumulative urban  (1.6 km/h < v <= 60 km/h) propulsion system active time during recent operation (time < 100 hours). OBD requires all hybrids to support this parameter.";
CM_ BO_ 2566583550 "Hybrid Charge Depleting or Increasing Operation Lifetime Hours";
CM_ SG_ 2566583550 HdLtDstTvdICDptOptWtEO "Hybrid Lifetime Distance Traveled in Charge Depleting Operation with Engine off : Total distance traveled while in charge depleting operation with engine off during the lifetime of the vehicle. OBD requires hybrids that are plugin vehicles to support...";
CM_ SG_ 2566583550 HdLtDstTvdICDptOptWtER "Hybrid Lifetime Distance Traveled in Charge Depleting Operation with Engine Running : Total distance traveled while in charge depleting operation with engine running during the lifetime of the vehicle. OBD requires hybrids that are plugin vehicles to...";
CM_ SG_ 2566583550 HdLtDstTvdIDvStCIsOpt "Hybrid Lifetime Distance Traveled in Driver-Selectable Charge Increasing Operation : Total distance traveled while in driver-selectable charge increasing operation during the lifetime of the vehicle. OBD requires hybrids that are plugin vehicles to s...";
CM_ SG_ 2566583550 HrdLftmFlCnsmdInChrgDpltngOprtn "Hybrid Lifetime Fuel Consumed in Charge Depleting Operation : Total fuel consumption during charge-depleting operation during the lifetime of the vehicle. OBD requires hybrids that are plugin vehicles to support this parameter.  ";
CM_ SG_ 2566583550 HdLtFCsdIDvStCIsOpt "Hybrid Lifetime Fuel Consumed in Driver-Selectable Charge Increasing Operation : Total fuel consumption during driver-selectable charge increasing operation during the lifetime of the vehicle. OBD requires hybrids that are plugin vehicles to support ...";
CM_ SG_ 2566583550 HdLtGdECsdICDptOptWtEO "Hybrid Lifetime Grid Energy Consumed in Charge Depleting Operation with Engine off : Total grid energy supplied by the battery pack in charge depleting operation with engine off during the lifetime of the vehicle. OBD requires hybrids that are plugin...";
CM_ SG_ 2566583550 HdLtGdECsdICDptOptWtER "Hybrid Lifetime Grid Energy Consumed in Charge Depleting Operation with Engine Running : Total grid energy supplied by the battery pack in charge depleting operation with engine running during the lifetime of the vehicle. OBD requires hybrids that ar...";
CM_ SG_ 2566583550 HrdLftmGrdEnrgIntThBttr "Hybrid Lifetime Grid Energy into the Battery : Total grid energy into the battery during the lifetime of the vehicle. OBD requires hybrids that are plugin vehicles to support this parameter.  ";
CM_ BO_ 2566583806 "Hybrid Charge Depleting or Increasing Operation Stored 100 Hours";
CM_ SG_ 2566583806 HdStd100HDstTvdICDptOptWtEO "Hybrid Stored 100 Hour Distance Traveled in Charge Depleting Operation with Engine off : Most recent stored 100-hour cumulative distance traveled while in charge depleting operation with engine off. OBD requires hybrids that are plugin vehicles to su...";
CM_ SG_ 2566583806 HdStd100HDstTvdICDptOptWtER "Hybrid Stored 100 Hour Distance Traveled in Charge Depleting Operation with Engine Running : Most recent stored 100-hour cumulative distance traveled while in charge depleting operation with engine running. OBD requires hybrids that are plugin vehicl...";
CM_ SG_ 2566583806 HdStd100HDstTvdIDvStCIsOpt "Hybrid Stored 100 Hour Distance Traveled in Driver-Selectable Charge Increasing Operation : Most recent stored 100-hour cumulative distance traveled while in driver-selectable charge increasing operation. OBD requires hybrids that are plugin vehicles...";
CM_ SG_ 2566583806 HdStd100HFCsdICDptOpt "Hybrid Stored 100 Hour Fuel Consumed in Charge Depleting Operation : Most recent stored 100-hour cumulative fuel consumed during charge-depleting operation. OBD requires hybrids that are plugin vehicles to support this parameter.  ";
CM_ SG_ 2566583806 HdStd100HFCsdIDvStCIsOpt "Hybrid Stored 100 Hour Fuel Consumed in Driver-Selectable Charge Increasing Operation : Most recent stored 100-hour cumulative fuel consumed during charge-depleting operation. OBD requires hybrids that are plugin vehicles to support this parameter.  ";
CM_ SG_ 2566583806 HdStd100HGdECsdICDptOptWtEO "Hybrid Stored 100 Hour Grid Energy Consumed in Charge Depleting Operation with Engine off : Most recent stored 100-hour cumulative grid energy consumed during charge depleting operation with engine off. OBD requires hybrids that are plugin vehicles t...";
CM_ SG_ 2566583806 HdStd100HGdECsdICDptOptWtER "Hybrid Stored 100 Hour Grid Energy Consumed in Charge Depleting Operation with Engine Running : Most recent stored 100-hour cumulative grid energy consumed during charge depleting operation with engine running. OBD requires hybrids that are plugin ve...";
CM_ SG_ 2566583806 HrdStrd100HrGrdEnrgIntThBttr "Hybrid Stored 100 Hour Grid Energy into the Battery : Most recent stored 100-hour cumulative grid energy into the Battery. OBD requires hybrids that are plugin vehicles to support this parameter.  ";
CM_ BO_ 2566584062 "Hybrid Charge Depleting or Increasing Operation Active 100 Hours";
CM_ SG_ 2566584062 HdAtv100HDstTvdICDptOptWtEO "Hybrid Active 100 Hour Distance Traveled in Charge Depleting Operation with Engine off : Cumulative distance traveled while in charge depleting operation with engine off during recent operation (time < 100 hours). OBD requires hybrids that are plugin...";
CM_ SG_ 2566584062 HdAtv100HDstTvdICDptOptWtER "Hybrid Active 100 Hour Distance Traveled in Charge Depleting Operation with Engine Running : Cumulative distance traveled while in charge depleting operation with engine running during recent operation (time < 100 hours). OBD requires hybrids that ar...";
CM_ SG_ 2566584062 HdAtv100HDstTvdIDvStCIsOpt "Hybrid Active 100 Hour Distance Traveled in Driver-Selectable Charge Increasing Operation : Cumulative distance traveled while in driver-selectable charge increasing operation during recent operation (time < 100 hours). OBD requires hybrids that are ...";
CM_ SG_ 2566584062 HdAtv100HFCsdICDptOpt "Hybrid Active 100 Hour Fuel Consumed in Charge Depleting Operation : Cumulative fuel consumption during charge-depleting operation during recent operation (time < 100 hours). OBD requires hybrids that are plugin vehicles to support this parameter.  ";
CM_ SG_ 2566584062 HdAtv100HFCsdIDvStCIsOpt "Hybrid Active 100 Hour Fuel Consumed in Driver-Selectable Charge Increasing Operation : Cumulative fuel consumption during driver-selectable charge increasing operation during recent operation (time < 100 hours). OBD requires hybrids that are plugin ...";
CM_ SG_ 2566584062 HdAtv100HGdECsdICDptOptWtEO "Hybrid Active 100 Hour Grid Energy Consumed in Charge Depleting Operation with Engine off : Cumulative grid energy supplied by the battery pack in charge depleting operation with engine off during recent operation (time < 100 hours). OBD requires hyb...";
CM_ SG_ 2566584062 HdAtv100HGdECsdICDptOptWtER "Hybrid Active 100 Hour Grid Energy Consumed in Charge Depleting Operation with Engine Running : Cumulative grid energy supplied by the battery pack in charge depleting operation with engine running during recent operation (time < 100 hours). OBD requ...";
CM_ SG_ 2566584062 HrdAtv100HrGrdEnrgIntThBttr "Hybrid Active 100 Hour Grid Energy into the Battery : Cumulative grid energy into the battery during recent operation (time < 100 hours). OBD requires hybrids that are plugin vehicles to support this parameter.  ";
CM_ BO_ 2566584318 "Aftertreatment 1 Historical Information 3";
CM_ SG_ 2566584318 Atttt1TtERtWtNDDv "Aftertreatment 1 Total Engine Runtime With No DEF Delivery: Total engine run time with no delivery of reductant (e.g., diesel exhaust fluid) used to control NOx emissions due to insufficient exhaust temperature.Note: For dual SCR catalyst systems, ti...";
CM_ SG_ 2566584318 Atttt1DpRtCptSttEVDst1 "Aftertreatment 1 DPF Regeneration Complete Starting Engine Vehicle Distance 1: The engine vehicle distance for the initiation of instance one of the last 3 complete DPF regenerations. Note: Engine vehicle distance data need not be presented in ascend...";
CM_ SG_ 2566584318 Atttt1DpRtCptEdEVDst1 "Aftertreatment 1 DPF Regeneration Complete Ending Engine Vehicle Distance 1: The engine vehicle distance for the completion of instance one of the last 3 complete DPF regenerations. Note: Engine vehicle distance data need not be presented in ascendin...";
CM_ SG_ 2566584318 Atttt1DpRtCptSttEVDst2 "Aftertreatment 1 DPF Regeneration Complete Starting Engine Vehicle Distance 2: The engine vehicle distance for the initiation of instance two of the last 3 complete DPF regenerations. Note: Engine vehicle distance data need not be presented in ascend...";
CM_ SG_ 2566584318 Atttt1DpRtCptEdEVDst2 "Aftertreatment 1 DPF Regeneration Complete Ending Engine Vehicle Distance 2: The engine vehicle distance for the completion of instance two of the last 3 complete DPF regenerations. Note: Engine vehicle distance data need not be presented in ascendin...";
CM_ SG_ 2566584318 Atttt1DpRtCptSttEVDst3 "Aftertreatment 1 DPF Regeneration Complete Starting Engine Vehicle Distance 3: The engine vehicle distance for the initiation of instance three of the last 3 complete DPF regenerations. Note: Engine vehicle distance data need not be presented in asce...";
CM_ SG_ 2566584318 Atttt1DpRtCptEdEVDst3 "Aftertreatment 1 DPF Regeneration Complete Ending Engine Vehicle Distance 3: The engine vehicle distance for the completion of instance three of the last 3 complete DPF regenerations.Note: Engine vehicle distance data need not be presented in ascendi...";
CM_ SG_ 2566584318 Atttt1TtTSItTptBw200Css "Aftertreatment 1 Total Time SCR Inlet Temperature Below 200 Celsius: Total engine run time with exhaust temperature below 200 degrees Celsius as measured just upstream of the NOx converting catalyst. Note: If an engine has more than one NOx convertin...";
CM_ BO_ 2566584830 "Aftertreatment 1 SCR 2 NOx Mass and NH3 Storage";
CM_ SG_ 2566584830 Aftrtrtmnt1Sr2InltNxMssFlw "Aftertreatment 1 SCR 2 Inlet NOx Mass Flow: The mass flow of the NOx in the engine exhaust stream before the second NOx converting catalyst in aftertreatment 1.This SP provides the NOx mass flow for the outlet of the first SCR catalyst for systems wi...";
CM_ SG_ 2566584830 Aftrtrtmnt1Sr2OtltNxMssFlw "Aftertreatment 1 SCR 2 Outlet NOx Mass Flow: The mass flow of the NOx in the engine exhaust stream after the NOx converting catalyst in aftertreatment 1.This SP shall be omitted for aftertreatment systems with exhaust flow through sequential SCR cata...";
CM_ SG_ 2566584830 Aftrtrtmnt1Sr2MdldNh3StrgLvl "Aftertreatment 1 SCR 2 Modeled NH3 Storage Level: The modeled or actual NH3 storage level in the second SCR catalyst in aftertreatment 1.";
CM_ SG_ 2566584830 Aftrtrtmnt1Sr2TrgtNh3StrgLvl "Aftertreatment 1 SCR 2 Target NH3 Storage Level: The target NH3 storage level in the second SCR catalyst in aftertreatment 1.";
CM_ BO_ 2566585086 "Aftertreatment 1 SCR 1 NOx Mass and NH3 Storage";
CM_ SG_ 2566585086 Aftrtrtmnt1Sr1EngnExhstNxMssFlw "Aftertreatment 1 SCR 1 Engine Exhaust NOx Mass Flow: The mass flow of the NOx in the engine exhaust stream before the NOx converting catalyst in aftertreatment 1.If there is only one sensor that provides the engine outlet NOx mass flow in a system wi...";
CM_ SG_ 2566585086 Aftrtrtmnt1Sr1TlppNxMssFlw "Aftertreatment 1 SCR 1 Tailpipe NOx Mass Flow: The mass flow of the NOx in the engine exhaust stream after all NOx converting catalysts in aftertreatment 1.For systems with a second, parallel flow SCR catalyst, SPN 12755 shall be used to provide the ...";
CM_ SG_ 2566585086 Aftrtrtmnt1Sr1MdldAtlStrgLvl "Aftertreatment 1 SCR 1 Modeled/Actual Storage Level: The modeled or actual NH3 storage level in the first SCR catalyst in aftertreatment 1.";
CM_ SG_ 2566585086 Aftrtrtmnt1Sr1TrgtNh3StrgLvl "Aftertreatment 1 SCR 1 Target NH3 Storage Level: The target NH3 storage level in the first SCR catalyst in aftertreatment 1.";
CM_ BO_ 2566585342 "Evaporative System Pressure and Control";
CM_ SG_ 2566585342 EvapSystemPurgePressure "EVAP System Purge Pressure: Absolute pressure of the purge element measured in the EVAP System.";
CM_ SG_ 2566585342 EvapSystemVaporPressure "EVAP System Vapor Pressure : Absolute pressure of the fuel vapor measured in the EVAP System.";
CM_ SG_ 2566585342 EvapSystemPurgeValveCommand "EVAP System Purge Valve Command: Commanded relative position of the EVAP System Purge Valve ";
CM_ SG_ 2566585342 EvapSystemPurgeValvePosition "EVAP System Purge Valve Position: Relative position of the EVAP System Purge Valve";
CM_ BO_ 2566585598 "GHG Tracking Lifetime Array Data";
CM_ SG_ 2566585598 GhgTrkngLftmEngnRnTm "GHG Tracking Lifetime Engine Run Time: Accumulated engine run time over the lifetime of the vehicle for GHG Tracking.  ";
CM_ SG_ 2566585598 GhgTrkngLftmVhlDstn "GHG Tracking Lifetime Vehicle Distance: Accumulated vehicle distance over the lifetime of the vehicle for GHG Tracking.  ";
CM_ SG_ 2566585598 GhgTrkngLftmVhlFlCnsmptn "GHG Tracking Lifetime Vehicle Fuel Consumption: Accumulated vehicle fuel consumption over the lifetime of the vehicle for GHG Tracking.  ";
CM_ SG_ 2566585598 GhgTrkngLftmEngnFlCnsmptn "GHG Tracking Lifetime Engine Fuel Consumption: Accumulated engine fuel consumption over the lifetime of the vehicle for GHG Tracking.  ";
CM_ SG_ 2566585598 GhgTrkngLftmEngnOtptEnrg "GHG Tracking Lifetime Engine Output Energy: Accumulated engine output energy over the lifetime of the vehicle for GHG Tracking.  ";
CM_ SG_ 2566585598 GhgTrkngLftmPstvKntEnrgNmrtr "GHG Tracking Lifetime Positive Kinetic Energy Numerator: Accumulated positive kinetic energy numerator (as delta-V-squared) over the lifetime of the vehicle for GHG Tracking.    The PKE Denominator is provided by GHG Tracking Lifetime Vehicle Distanc...";
CM_ SG_ 2566585598 GhgTrkngLftmUrnSpdRnTm "GHG Tracking Lifetime Urban Speed Run Time: Accumulated time at urban vehicle speeds (1.6 km/h < v <= 60 km/h) over the lifetime of the vehicle for GHG Tracking.";
CM_ SG_ 2566585598 GhgTrackingLifetimeIdleRunTime "GHG Tracking Lifetime Idle Run Time: Accumulated engine run time under idle conditions (v <= 1.6 km/h) over the lifetime of the vehicle for GHG Tracking.";
CM_ SG_ 2566585598 GhgTrkngLftmEngnIdlFlCnsmptn "GHG Tracking Lifetime Engine Idle Fuel Consumption: Accumulated fuel consumption under idle conditions (v <= 1.6 km/h) over the lifetime of the vehicle for GHG Tracking.";
CM_ SG_ 2566585598 GhgTrkngLftmEngnPwrTkOffRnTm "GHG Tracking Lifetime Engine Power Take Off Run Time: Accumulated engine runtime under power take off [PTO] governor control over the lifetime of the vehicle for GHG Tracking.  ";
CM_ SG_ 2566585598 GhgTrkngLftmStpStrtThnlgRnTm "GHG Tracking Lifetime Stop-Start Technology Run Time: Accumulated time where the stop start system is commanding the engine off over the lifetime of the vehicle for GHG Tracking.  ";
CM_ SG_ 2566585598 GTLtEPwTOFCspt "GHG Tracking Lifetime Engine Power Take Off Fuel Consumption: Accumulated fuel consumption under power take off [PTO] governor control over the lifetime of the vehicle for GHG Tracking.  ";
CM_ SG_ 2566585598 GTLtAttEStdwTAtvtCt "GHG Tracking Lifetime Automatic Engine Shutdown Technology Activation Count: Accumulated activation counts of the automatic engine [idle] shutdown (AES) system over the lifetime of the vehicle for GHG Tracking.  [Ed note:  Change SLOT to SAEct07; PGN...";
CM_ BO_ 2566585854 "GHG Tracking Stored 100 Hour Array Data";
CM_ SG_ 2566585854 GhgTrkngStrd100HrEngnRnTm "GHG Tracking Stored 100 Hour Engine Run Time: Accumulated engine run time over the prior 100 hour period for GHG Tracking.  ";
CM_ SG_ 2566585854 GhgTrkngStrd100HrVhlDstn "GHG Tracking Stored 100 Hour Vehicle Distance: Accumulated vehicle distance over the prior 100 hour period for GHG Tracking.  ";
CM_ SG_ 2566585854 GhgTrkngStrd100HrVhlFlCnsmptn "GHG Tracking Stored 100 Hour Vehicle Fuel Consumption: Accumulated vehicle fuel consumption over the prior 100 hour period for GHG Tracking.  ";
CM_ SG_ 2566585854 GhgTrkngStrd100HrEngnFlCnsmptn "GHG Tracking Stored 100 Hour Engine Fuel Consumption: Accumulated engine fuel consumption over the prior 100 hour period for GHG Tracking.  ";
CM_ SG_ 2566585854 GhgTrkngStrd100HrEngnOtptEnrg "GHG Tracking Stored 100 Hour Engine Output Energy: Accumulated engine output energy over the prior 100 hour period for GHG Tracking.  ";
CM_ SG_ 2566585854 GhgTrkngStrd100HrUrnSpdRnTm "GHG Tracking Stored 100 Hour Urban Speed Run Time: Accumulated time at urban vehicle speeds (1.6 km/h < v <= 60 km/h) over the prior 100 hour period for GHG Tracking.";
CM_ SG_ 2566585854 GhgTrkngStrd100HrIdlRnTm "GHG Tracking Stored 100 Hour Idle Run Time: Accumulated engine run time under idle conditions (v <= 1.6 km/h) over the prior 100 hour period for GHG Tracking.";
CM_ SG_ 2566585854 GTStd100HPstvKtENt "GHG Tracking Stored 100 Hour Positive Kinetic Energy Numerator: Accumulated positive kinetic energy numerator (as delta-V-squared) over the prior 100 hour period for GHG Tracking.  The PKE denominator is GHG Tracking Stored 100 Hour Vehicle Distance....";
CM_ SG_ 2566585854 GTStd100HEIdFCspt "GHG Tracking Stored 100 Hour Engine Idle Fuel Consumption: Accumulated fuel consumption under idle conditions (v <= 1.6 km/h) over the prior 100 hour period for GHG Tracking.";
CM_ SG_ 2566585854 GTStd100HEPwTORT "GHG Tracking Stored 100 Hour Engine Power Take Off Run Time: Accumulated engine runtime under power take off [PTO] governor control over the prior 100 hour period for GHG Tracking.  ";
CM_ SG_ 2566585854 GTStd100HEPwTOFCspt "GHG Tracking Stored 100 Hour Engine Power Take Off Fuel Consumption: Accumulated fuel consumption under power take off [PTO] governor control over the prior 100 hour period for GHG Tracking.  ";
CM_ SG_ 2566585854 GTStd100HAttEStdwTAtvtCt "GHG Tracking Stored 100 Hour Automatic Engine Shutdown Technology Activation Count: Accumulated activation counts of the automatic engine [idle] shutdown (AES) system over the prior 100 hour period for GHG Tracking.  ";
CM_ SG_ 2566585854 GTStd100HStpSttTRT "GHG Tracking Stored 100 Hour Stop-Start Technology Run Time: Accumulated time where the stop start system is commanding the engine off over the prior 100 hour period for GHG Tracking.  ";
CM_ BO_ 2566586110 "GHG Tracking Active 100 Hour Array Data";
CM_ SG_ 2566586110 GhgTrkngAtv100HrEngnRnTm "GHG Tracking Active 100 Hour Engine Run Time: Accumulated engine run time over the current 100 hour period for GHG Tracking.  ";
CM_ SG_ 2566586110 GhgTrkngAtv100HrVhlDstn "GHG Tracking Active 100 Hour Vehicle Distance: Accumulated vehicle distance over the current 100 hour period for GHG Tracking.  ";
CM_ SG_ 2566586110 GhgTrkngAtv100HrVhlFlCnsmptn "GHG Tracking Active 100 Hour Vehicle Fuel Consumption: Accumulated vehicle fuel consumption over the current 100 hour period for GHG Tracking.  ";
CM_ SG_ 2566586110 GhgTrkngAtv100HrEngnFlCnsmptn "GHG Tracking Active 100 Hour Engine Fuel Consumption: Accumulated engine fuel consumption over the current 100 hour period for GHG Tracking.  ";
CM_ SG_ 2566586110 GhgTrkngAtv100HrEngnOtptEnrg "GHG Tracking Active 100 Hour Engine Output Energy: Accumulated engine output energy over the current 100 hour period for GHG Tracking.  ";
CM_ SG_ 2566586110 GhgTrkngAtv100HrUrnSpdRnTm "GHG Tracking Active 100 Hour Urban Speed Run Time: Accumulated time at urban vehicle speeds (1.6 km/h < v <= 60 km/h) over the current 100 hour period for GHG Tracking.";
CM_ SG_ 2566586110 GhgTrkngAtv100HrIdlRnTm "GHG Tracking Active 100 Hour Idle Run Time: Accumulated engine run time under idle conditions (v <= 1.6 km/h) over the current 100 hour period for GHG Tracking.";
CM_ SG_ 2566586110 GTAtv100HPstvKtENt "GHG Tracking Active 100 Hour Positive Kinetic Energy Numerator: Accumulated positive kinetic energy numerator (as delta-V-squared) over the current 100 hour period for GHG Tracking.  The PKE denominator is GHG Tracking Active 100 Hour Vehicle Distanc...";
CM_ SG_ 2566586110 GTAtv100HEIdFCspt "GHG Tracking Active 100 Hour Engine Idle Fuel Consumption: Accumulated fuel consumption under idle conditions (v <= 1.6 km/h) over the current 100 hour period for GHG Tracking.";
CM_ SG_ 2566586110 GTAtv100HEPwTORT "GHG Tracking Active 100 Hour Engine Power Take Off Run Time: Accumulated engine runtime under power take off [PTO] governor control over the current 100 hour period for GHG Tracking.  ";
CM_ SG_ 2566586110 GTAtv100HEPwTOFCspt "GHG Tracking Active 100 Hour Engine Power Take Off Fuel Consumption: Accumulated fuel consumption under power take off [PTO] governor control over the current 100 hour period for GHG Tracking.  ";
CM_ SG_ 2566586110 GTAtv100HAttEStdwTAtvtCt "GHG Tracking Active 100 Hour Automatic Engine Shutdown Technology Activation Count: Accumulated activation counts of the automatic engine [idle] shutdown (AES) system over the current 100 hour period for GHG Tracking.  ";
CM_ SG_ 2566586110 GTAtv100HStpSttTRT "GHG Tracking Active 100 Hour Stop-Start Technology Run Time: Accumulated time where the stop start system is commanding the engine off over the current 100 hour period for GHG Tracking.  ";
CM_ BO_ 2566587134 "NOx Tracking Engine Activity Lifetime Fuel Consumption Bins ";
CM_ SG_ 2566587134 NxTEAtvtLtFCsptB1Tt "NOx Tracking Engine Activity Lifetime Fuel Consumption Bin 1 (Total): Accumulated Fuel consumption regardless of NOx sensor status over the lifetime of the vehicle for Bin 1 [Note Bin 1 is the total of Bins 2-14]";
CM_ SG_ 2566587134 NxTrkngEngnAtvtLftmFlCnsmptnBn2 "NOx Tracking Engine Activity Lifetime Fuel Consumption Bin 2 : Accumulated Fuel consumption regardless of NOx sensor status over the lifetime of the vehicle for Bin 2 [Note Bin 2 is the 'idle' bin]";
CM_ SG_ 2566587134 NxTrkngEngnAtvtLftmFlCnsmptnBn3 "NOx Tracking Engine Activity Lifetime Fuel Consumption Bin 3 : Accumulated Fuel consumption regardless of NOx sensor status over the lifetime of the vehicle for Bin 3. ";
CM_ SG_ 2566587134 NxTrkngEngnAtvtLftmFlCnsmptnBn4 "NOx Tracking Engine Activity Lifetime Fuel Consumption Bin 4: Accumulated Fuel consumption regardless of NOx sensor status over the lifetime of the vehicle for Bin 4. ";
CM_ SG_ 2566587134 NxTrkngEngnAtvtLftmFlCnsmptnBn5 "NOx Tracking Engine Activity Lifetime Fuel Consumption Bin 5: Accumulated Fuel consumption regardless of NOx sensor status over the lifetime of the vehicle for Bin 5.";
CM_ SG_ 2566587134 NxTrkngEngnAtvtLftmFlCnsmptnBn6 "NOx Tracking Engine Activity Lifetime Fuel Consumption Bin 6: Accumulated Fuel consumption regardless of NOx sensor status over the lifetime of the vehicle for Bin 6. ";
CM_ SG_ 2566587134 NxTrkngEngnAtvtLftmFlCnsmptnBn7 "NOx Tracking Engine Activity Lifetime Fuel Consumption Bin 7: Accumulated Fuel consumption regardless of NOx sensor status over the lifetime of the vehicle for Bin 7. ";
CM_ SG_ 2566587134 NxTrkngEngnAtvtLftmFlCnsmptnBn8 "NOx Tracking Engine Activity Lifetime Fuel Consumption Bin 8: Accumulated Fuel consumption regardless of NOx sensor status over the lifetime of the vehicle for Bin 8. ";
CM_ SG_ 2566587134 NxTrkngEngnAtvtLftmFlCnsmptnBn9 "NOx Tracking Engine Activity Lifetime Fuel Consumption Bin 9: Accumulated Fuel consumption regardless of NOx sensor status over the lifetime of the vehicle for Bin 9";
CM_ SG_ 2566587134 NxTEAtvtLtFCsptB10 "NOx Tracking Engine Activity Lifetime Fuel Consumption Bin 10: Accumulated Fuel consumption regardless of NOx sensor status over the lifetime of the vehicle for Bin 10";
CM_ SG_ 2566587134 NxTEAtvtLtFCsptB11 "NOx Tracking Engine Activity Lifetime Fuel Consumption Bin 11: Accumulated Fuel consumption regardless of NOx sensor status over the lifetime of the vehicle for Bin 11";
CM_ SG_ 2566587134 NxTEAtvtLtFCsptB12 "NOx Tracking Engine Activity Lifetime Fuel Consumption Bin 12: Accumulated Fuel consumption regardless of NOx sensor status over the lifetime of the vehicle for Bin 12";
CM_ SG_ 2566587134 NxTEAtvtLtFCsptB13 "NOx Tracking Engine Activity Lifetime Fuel Consumption Bin 13: Accumulated Fuel consumption regardless of NOx sensor status over the lifetime of the vehicle for Bin 13";
CM_ SG_ 2566587134 NxTEAtvtLtFCsptB14 "NOx Tracking Engine Activity Lifetime Fuel Consumption Bin 14 : Accumulated Fuel consumption regardless of NOx sensor status over the lifetime of the vehicle for Bin 14";
CM_ SG_ 2566587134 NxTEAtvtLtFCsptB15NtB "NOx Tracking Engine Activity Lifetime Fuel Consumption Bin 15 (NTE BIN): Accumulated Fuel consumption regardless of NOx sensor status over the lifetime of the vehicle for Bin 15 [Note Bin 15 is the NTE Bin]";
CM_ SG_ 2566587134 NxTEAtvtLtFCsptB16RB "NOx Tracking Engine Activity Lifetime Fuel Consumption Bin 16 (Regen Bin) : Accumulated Fuel consumption regardless of NOx sensor status over the lifetime of the vehicle for Bin 16 [Note Bin 16 is the Regen Bin]";
CM_ SG_ 2566587134 NxTEAtvtLtFCsptB17MOB "NOx Tracking Engine Activity Lifetime Fuel Consumption Bin 17 (MIL On Bin): Accumulated Fuel consumption regardless of NOx sensor status over the lifetime of the vehicle for Bin 17 [Note Bin 17 is the MIL On  bin].";
CM_ BO_ 2566587390 "NOx Tracking Engine Activity Lifetime Engine Run Time Bins ";
CM_ SG_ 2566587390 NxTEAtvtLtERTB1Tt "NOx Tracking Engine Activity Lifetime Engine Run Time Bin 1 (Total): Accumulated Engine run time regardless of NOx sensor status over the lifetime of the vehicle for Bin 1 [Note Bin 1 is the total of Bins 2-14]";
CM_ SG_ 2566587390 NxTrkngEngnAtvtLftmEngnRnTmBn2 "NOx Tracking Engine Activity Lifetime Engine Run Time Bin 2 : Accumulated Engine run time regardless of NOx sensor status over the lifetime of the vehicle for Bin 2 [Note Bin 2 is the 'idle' bin]";
CM_ SG_ 2566587390 NxTrkngEngnAtvtLftmEngnRnTmBn3 "NOx Tracking Engine Activity Lifetime Engine Run Time Bin 3 : Accumulated Engine run time regardless of NOx sensor status over the lifetime of the vehicle for Bin 3. ";
CM_ SG_ 2566587390 NxTrkngEngnAtvtLftmEngnRnTmBn4 "NOx Tracking Engine Activity Lifetime Engine Run Time Bin 4: Accumulated Engine run time regardless of NOx sensor status over the lifetime of the vehicle for Bin 4.";
CM_ SG_ 2566587390 NxTrkngEngnAtvtLftmEngnRnTmBn5 "NOx Tracking Engine Activity Lifetime Engine Run Time Bin 5: Accumulated Engine run time regardless of NOx sensor status over the lifetime of the vehicle for Bin 5.";
CM_ SG_ 2566587390 NxTrkngEngnAtvtLftmEngnRnTmBn6 "NOx Tracking Engine Activity Lifetime Engine Run Time Bin 6: Accumulated Engine run time regardless of NOx sensor status over the lifetime of the vehicle for Bin 6. ";
CM_ SG_ 2566587390 NxTrkngEngnAtvtLftmEngnRnTmBn7 "NOx Tracking Engine Activity Lifetime Engine Run Time Bin 7: Accumulated Engine run time regardless of NOx sensor status over the lifetime of the vehicle for Bin 7. ";
CM_ SG_ 2566587390 NxTrkngEngnAtvtLftmEngnRnTmBn8 "NOx Tracking Engine Activity Lifetime Engine Run Time Bin 8: Accumulated Engine run time regardless of NOx sensor status over the lifetime of the vehicle for Bin 8. ";
CM_ SG_ 2566587390 NxTrkngEngnAtvtLftmEngnRnTmBn9 "NOx Tracking Engine Activity Lifetime Engine Run Time Bin 9: Accumulated Engine run time regardless of NOx sensor status over the lifetime of the vehicle for Bin 9";
CM_ SG_ 2566587390 NxTrkngEngnAtvtLftmEngnRnTmBn10 "NOx Tracking Engine Activity Lifetime Engine Run Time Bin 10: Accumulated Engine run time regardless of NOx sensor status over the lifetime of the vehicle for Bin 10";
CM_ SG_ 2566587390 NxTrkngEngnAtvtLftmEngnRnTmBn11 "NOx Tracking Engine Activity Lifetime Engine Run Time Bin 11: Accumulated Engine run time regardless of NOx sensor status over the lifetime of the vehicle for Bin 11";
CM_ SG_ 2566587390 NxTrkngEngnAtvtLftmEngnRnTmBn12 "NOx Tracking Engine Activity Lifetime Engine Run Time Bin 12: Accumulated Engine run time regardless of NOx sensor status over the lifetime of the vehicle for Bin 12";
CM_ SG_ 2566587390 NxTrkngEngnAtvtLftmEngnRnTmBn13 "NOx Tracking Engine Activity Lifetime Engine Run Time Bin 13: Accumulated Engine run time regardless of NOx sensor status over the lifetime of the vehicle for Bin 13";
CM_ SG_ 2566587390 NxTrkngEngnAtvtLftmEngnRnTmBn14 "NOx Tracking Engine Activity Lifetime Engine Run Time Bin 14 : Accumulated Engine run time regardless of NOx sensor status over the lifetime of the vehicle for Bin 14";
CM_ SG_ 2566587390 NxTEAtvtLtERTB15NtB "NOx Tracking Engine Activity Lifetime Engine Run Time Bin 15 (NTE BIN): Accumulated Engine run time regardless of NOx sensor status over the lifetime of the vehicle for Bin 15 [Note Bin 15 is the NTE Bin]";
CM_ SG_ 2566587390 NxTEAtvtLtERTB16RB "NOx Tracking Engine Activity Lifetime Engine Run Time Bin 16 (Regen Bin) : Accumulated Engine run time regardless of NOx sensor status over the lifetime of the vehicle for Bin 16 [Note Bin 16 is the Regen Bin]";
CM_ SG_ 2566587390 NxTEAtvtLtERTB17MOB "NOx Tracking Engine Activity Lifetime Engine Run Time Bin 17 (MIL On Bin): Accumulated Engine run time regardless of NOx sensor status over the lifetime of the vehicle for Bin 17 [Note Bin 17 is the MIL On Bin].";
CM_ BO_ 2566587646 "NOx Tracking Engine Activity Lifetime Vehicle Distance Bins ";
CM_ SG_ 2566587646 NxTEAtvtLtVDstB1Tt "NOx Tracking Engine Activity Lifetime Vehicle Distance Bin 1 (Total): Accumulated Vehicle distance regardless of NOx sensor status over the lifetime of the vehicle for Bin 1 [Note Bin 1 is the total of Bins 2-14]";
CM_ SG_ 2566587646 NxTrkngEngnAtvtLftmVhlDstnBn2 "NOx Tracking Engine Activity Lifetime Vehicle Distance Bin 2 : Accumulated Vehicle distance regardless of NOx sensor status over the lifetime of the vehicle for Bin 2 [Note Bin 2 is the 'idle' bin]";
CM_ SG_ 2566587646 NxTrkngEngnAtvtLftmVhlDstnBn3 "NOx Tracking Engine Activity Lifetime Vehicle Distance Bin 3 : Accumulated Vehicle distance regardless of NOx sensor status over the lifetime of the vehicle for Bin 3.";
CM_ SG_ 2566587646 NxTrkngEngnAtvtLftmVhlDstnBn4 "NOx Tracking Engine Activity Lifetime Vehicle Distance Bin 4: Accumulated Vehicle distance regardless of NOx sensor status over the lifetime of the vehicle for Bin 4.";
CM_ SG_ 2566587646 NxTrkngEngnAtvtLftmVhlDstnBn5 "NOx Tracking Engine Activity Lifetime Vehicle Distance Bin 5: Accumulated Vehicle distance regardless of NOx sensor status over the lifetime of the vehicle for Bin 5.";
CM_ SG_ 2566587646 NxTrkngEngnAtvtLftmVhlDstnBn6 "NOx Tracking Engine Activity Lifetime Vehicle Distance Bin 6: Accumulated Vehicle distance regardless of NOx sensor status over the lifetime of the vehicle for Bin 6. ";
CM_ SG_ 2566587646 NxTrkngEngnAtvtLftmVhlDstnBn7 "NOx Tracking Engine Activity Lifetime Vehicle Distance Bin 7: Accumulated Vehicle distance regardless of NOx sensor status over the lifetime of the vehicle for Bin 7. ";
CM_ SG_ 2566587646 NxTrkngEngnAtvtLftmVhlDstnBn8 "NOx Tracking Engine Activity Lifetime Vehicle Distance Bin 8: Accumulated Vehicle distance regardless of NOx sensor status over the lifetime of the vehicle for Bin 8. ";
CM_ SG_ 2566587646 NxTrkngEngnAtvtLftmVhlDstnBn9 "NOx Tracking Engine Activity Lifetime Vehicle Distance Bin 9: Accumulated Vehicle distance regardless of NOx sensor status over the lifetime of the vehicle for Bin 9";
CM_ SG_ 2566587646 NxTrkngEngnAtvtLftmVhlDstnBn10 "NOx Tracking Engine Activity Lifetime Vehicle Distance Bin 10: Accumulated Vehicle distance regardless of NOx sensor status over the lifetime of the vehicle for Bin 10";
CM_ SG_ 2566587646 NxTrkngEngnAtvtLftmVhlDstnBn11 "NOx Tracking Engine Activity Lifetime Vehicle Distance Bin 11: Accumulated Vehicle distance regardless of NOx sensor status over the lifetime of the vehicle for Bin 11";
CM_ SG_ 2566587646 NxTrkngEngnAtvtLftmVhlDstnBn12 "NOx Tracking Engine Activity Lifetime Vehicle Distance Bin 12: Accumulated Vehicle distance regardless of NOx sensor status over the lifetime of the vehicle for Bin 12";
CM_ SG_ 2566587646 NxTrkngEngnAtvtLftmVhlDstnBn13 "NOx Tracking Engine Activity Lifetime Vehicle Distance Bin 13: Accumulated Vehicle distance regardless of NOx sensor status over the lifetime of the vehicle for Bin 13";
CM_ SG_ 2566587646 NxTrkngEngnAtvtLftmVhlDstnBn14 "NOx Tracking Engine Activity Lifetime Vehicle Distance Bin 14 : Accumulated Vehicle distance regardless of NOx sensor status over the lifetime of the vehicle for Bin 14";
CM_ SG_ 2566587646 NxTEAtvtLtVDstB15NtB "NOx Tracking Engine Activity Lifetime Vehicle Distance Bin 15 (NTE BIN): Accumulated Vehicle distance regardless of NOx sensor status over the lifetime of the vehicle for Bin 15 [Note Bin 15 is the NTE Bin]";
CM_ SG_ 2566587646 NxTEAtvtLtVDstB16RB "NOx Tracking Engine Activity Lifetime Vehicle Distance Bin 16 (Regen Bin) : Accumulated Vehicle distance regardless of NOx sensor status over the lifetime of the vehicle for Bin 16 [Note Bin 16 is the Regen Bin]";
CM_ SG_ 2566587646 NxTEAtvtLtVDstB17MOB "NOx Tracking Engine Activity Lifetime Vehicle Distance Bin 17 (MIL On Bin): Accumulated Vehicle distance regardless of NOx sensor status over the lifetime of the vehicle for Bin 17 [Note Bin 17 is the MIL On Bin].";
CM_ BO_ 2566587902 "NOx Tracking Engine Activity Lifetime Engine Output Energy Bins ";
CM_ SG_ 2566587902 NxTEAtvtLtEOtptEB1Tt "NOx Tracking Engine Activity Lifetime Engine Output Energy Bin 1 (Total) : Accumulated Engine output energy regardless of NOx sensor status over the lifetime of the vehicle for Bin 1 [Note Bin 1 is the total of bins 2-14]";
CM_ SG_ 2566587902 NxTEAtvtLtEOtptEB2 "NOx Tracking Engine Activity Lifetime Engine Output Energy Bin 2 : Accumulated Engine output energy regardless of NOx sensor status over the lifetime of the vehicle for Bin 2 [Note Bin 2 is the 'idle' bin]";
CM_ SG_ 2566587902 NxTEAtvtLtEOtptEB3 "NOx Tracking Engine Activity Lifetime Engine Output Energy Bin 3 : Accumulated Engine output energy regardless of NOx sensor status over the lifetime of the vehicle for Bin 3.";
CM_ SG_ 2566587902 NxTEAtvtLtEOtptEB4 "NOx Tracking Engine Activity Lifetime Engine Output Energy Bin 4: Accumulated Engine output energy regardless of NOx sensor status over the lifetime of the vehicle for Bin 4. ";
CM_ SG_ 2566587902 NxTEAtvtLtEOtptEB5 "NOx Tracking Engine Activity Lifetime Engine Output Energy Bin 5: Accumulated Engine output energy regardless of NOx sensor status over the lifetime of the vehicle for Bin 5.";
CM_ SG_ 2566587902 NxTEAtvtLtEOtptEB6 "NOx Tracking Engine Activity Lifetime Engine Output Energy Bin 6: Accumulated Engine output energy regardless of NOx sensor status over the lifetime of the vehicle for Bin 6. ";
CM_ SG_ 2566587902 NxTEAtvtLtEOtptEB7 "NOx Tracking Engine Activity Lifetime Engine Output Energy Bin 7: Accumulated Engine output energy regardless of NOx sensor status over the lifetime of the vehicle for Bin 7. ";
CM_ SG_ 2566587902 NxTEAtvtLtEOtptEB8 "NOx Tracking Engine Activity Lifetime Engine Output Energy Bin 8: Accumulated Engine output energy regardless of NOx sensor status over the lifetime of the vehicle for Bin 8. ";
CM_ SG_ 2566587902 NxTEAtvtLtEOtptEB9 "NOx Tracking Engine Activity Lifetime Engine Output Energy Bin 9: Accumulated Engine output energy regardless of NOx sensor status over the lifetime of the vehicle for Bin 9";
CM_ SG_ 2566587902 NxTEAtvtLtEOtptEB10 "NOx Tracking Engine Activity Lifetime Engine Output Energy Bin 10: Accumulated Engine output energy regardless of NOx sensor status over the lifetime of the vehicle for Bin 10";
CM_ SG_ 2566587902 NxTEAtvtLtEOtptEB11 "NOx Tracking Engine Activity Lifetime Engine Output Energy Bin 11: Accumulated Engine output energy regardless of NOx sensor status over the lifetime of the vehicle for Bin 11";
CM_ SG_ 2566587902 NxTEAtvtLtEOtptEB12 "NOx Tracking Engine Activity Lifetime Engine Output Energy Bin 12: Accumulated Engine output energy regardless of NOx sensor status over the lifetime of the vehicle for Bin 12";
CM_ SG_ 2566587902 NxTEAtvtLtEOtptEB13 "NOx Tracking Engine Activity Lifetime Engine Output Energy Bin 13: Accumulated Engine output energy regardless of NOx sensor status over the lifetime of the vehicle for Bin 13";
CM_ SG_ 2566587902 NxTEAtvtLtEOtptEB14 "NOx Tracking Engine Activity Lifetime Engine Output Energy Bin 14 : Accumulated Engine output energy regardless of NOx sensor status over the lifetime of the vehicle for Bin 14";
CM_ SG_ 2566587902 NxTEAtvtLtEOtptEB15NtB "NOx Tracking Engine Activity Lifetime Engine Output Energy Bin 15 (NTE BIN): Accumulated Engine output energy regardless of NOx sensor status over the lifetime of the vehicle for Bin 15 [Note Bin 15 is the NTE Bin]";
CM_ SG_ 2566587902 NxTEAtvtLtEOtptEB16RB "NOx Tracking Engine Activity Lifetime Engine Output Energy Bin 16 (Regen Bin) : Accumulated Engine output energy regardless of NOx sensor status over the lifetime of the vehicle for Bin 16 [Note Bin 16 is the Regen Bin]";
CM_ SG_ 2566587902 NxTEAtvtLtEOtptEB17MOB "NOx Tracking Engine Activity Lifetime Engine Output Energy Bin 17 (MIL On Bin): Accumulated Engine output energy regardless of NOx sensor status over the lifetime of the vehicle for Bin 17 [Note Bin 17 is the MIL On Bin].";
CM_ BO_ 2566588158 "NOx Tracking Valid NOx Lifetime Fuel Consumption Bins ";
CM_ SG_ 2566588158 NxTrkngVldNxLftmFlCnsmptnBn1Ttl "NOx Tracking Valid NOx Lifetime Fuel Consumption Bin 1 (Total): Accumulated Fuel consumption while all NOx sensors are active over the lifetime of the vehicle for Bin 1 [Note Bin 1 is the total of Bins 2-14]";
CM_ SG_ 2566588158 NxTrkngVldNxLftmFlCnsmptnBn2 "NOx Tracking Valid NOx Lifetime Fuel Consumption Bin 2 : Accumulated Fuel consumption while all NOx sensors are active over the lifetime of the vehicle for Bin 2 [Note Bin 2 is the 'idle' bin]";
CM_ SG_ 2566588158 NxTrkngVldNxLftmFlCnsmptnBn3 "NOx Tracking Valid NOx Lifetime Fuel Consumption Bin 3 : Accumulated Fuel consumption while all NOx sensors are active over the lifetime of the vehicle for Bin 3. ";
CM_ SG_ 2566588158 NxTrkngVldNxLftmFlCnsmptnBn4 "NOx Tracking Valid NOx Lifetime Fuel Consumption Bin 4: Accumulated Fuel consumption while all NOx sensors are active over the lifetime of the vehicle for Bin 4. ";
CM_ SG_ 2566588158 NxTrkngVldNxLftmFlCnsmptnBn5 "NOx Tracking Valid NOx Lifetime Fuel Consumption Bin 5: Accumulated Fuel consumption while all NOx sensors are active over the lifetime of the vehicle for Bin 5.";
CM_ SG_ 2566588158 NxTrkngVldNxLftmFlCnsmptnBn6 "NOx Tracking Valid NOx Lifetime Fuel Consumption Bin 6: Accumulated Fuel consumption while all NOx sensors are active over the lifetime of the vehicle for Bin 6. ";
CM_ SG_ 2566588158 NxTrkngVldNxLftmFlCnsmptnBn7 "NOx Tracking Valid NOx Lifetime Fuel Consumption Bin 7: Accumulated Fuel consumption while all NOx sensors are active over the lifetime of the vehicle for Bin 7. ";
CM_ SG_ 2566588158 NxTrkngVldNxLftmFlCnsmptnBn8 "NOx Tracking Valid NOx Lifetime Fuel Consumption Bin 8: Accumulated Fuel consumption while all NOx sensors are active over the lifetime of the vehicle for Bin 8. ";
CM_ SG_ 2566588158 NxTrkngVldNxLftmFlCnsmptnBn9 "NOx Tracking Valid NOx Lifetime Fuel Consumption Bin 9: Accumulated Fuel consumption while all NOx sensors are active over the lifetime of the vehicle for Bin 9";
CM_ SG_ 2566588158 NxTrkngVldNxLftmFlCnsmptnBn10 "NOx Tracking Valid NOx Lifetime Fuel Consumption Bin 10: Accumulated Fuel consumption while all NOx sensors are active over the lifetime of the vehicle for Bin 10";
CM_ SG_ 2566588158 NxTrkngVldNxLftmFlCnsmptnBn11 "NOx Tracking Valid NOx Lifetime Fuel Consumption Bin 11: Accumulated Fuel consumption while all NOx sensors are active over the lifetime of the vehicle for Bin 11";
CM_ SG_ 2566588158 NxTrkngVldNxLftmFlCnsmptnBn12 "NOx Tracking Valid NOx Lifetime Fuel Consumption Bin 12: Accumulated Fuel consumption while all NOx sensors are active over the lifetime of the vehicle for Bin 12";
CM_ SG_ 2566588158 NxTrkngVldNxLftmFlCnsmptnBn13 "NOx Tracking Valid NOx Lifetime Fuel Consumption Bin 13: Accumulated Fuel consumption while all NOx sensors are active over the lifetime of the vehicle for Bin 13";
CM_ SG_ 2566588158 NxTrkngVldNxLftmFlCnsmptnBn14 "NOx Tracking Valid NOx Lifetime Fuel Consumption Bin 14 : Accumulated Fuel consumption while all NOx sensors are active over the lifetime of the vehicle for Bin 14";
CM_ SG_ 2566588158 NxTVdNxLtFCsptB15NtB "NOx Tracking Valid NOx Lifetime Fuel Consumption Bin 15 (NTE BIN) : Accumulated Fuel consumption while all NOx sensors are active over the lifetime of the vehicle for Bin 15 [Note Bin 15 is the NTE Bin]";
CM_ SG_ 2566588158 NxTVdNxLtFCsptB16RB "NOx Tracking Valid NOx Lifetime Fuel Consumption Bin 16 (Regen Bin) : Accumulated Fuel consumption while all NOx sensors are active over the lifetime of the vehicle for Bin 16 [Note Bin 16 is the Regen Bin]";
CM_ SG_ 2566588158 NxTVdNxLtFCsptB17MOB "NOx Tracking Valid NOx Lifetime Fuel Consumption Bin 17 (MIL On Bin) : Accumulated Fuel consumption while all NOx sensors are active over the lifetime of the vehicle for Bin 17 [Note Bin 17 is the MIL On Bin]";
CM_ BO_ 2566588414 "NOx Tracking Valid NOx Lifetime Engine Run Time Bins ";
CM_ SG_ 2566588414 NxTrkngVldNxLftmEngnRnTmBn1Ttl "NOx Tracking Valid NOx Lifetime Engine Run Time Bin 1 (Total): Accumulated Engine run time while all NOx sensors are active over the lifetime of the vehicle for Bin 1 [Note Bin 1 is the total of Bins 2-14]";
CM_ SG_ 2566588414 NxTrkngVldNxLftmEngnRnTmBn2 "NOx Tracking Valid NOx Lifetime Engine Run Time Bin 2 : Accumulated Engine run time while all NOx sensors are active over the lifetime of the vehicle for Bin 2 [Note Bin 2 is the 'idle' bin]";
CM_ SG_ 2566588414 NxTrkngVldNxLftmEngnRnTmBn3 "NOx Tracking Valid NOx Lifetime Engine Run Time Bin 3 : Accumulated Engine run time while all NOx sensors are active over the lifetime of the vehicle for Bin 3. ";
CM_ SG_ 2566588414 NxTrkngVldNxLftmEngnRnTmBn4 "NOx Tracking Valid NOx Lifetime Engine Run Time Bin 4: Accumulated Engine run time while all NOx sensors are active over the lifetime of the vehicle for Bin 4.";
CM_ SG_ 2566588414 NxTrkngVldNxLftmEngnRnTmBn5 "NOx Tracking Valid NOx Lifetime Engine Run Time Bin 5: Accumulated Engine run time while all NOx sensors are active over the lifetime of the vehicle for Bin 5.";
CM_ SG_ 2566588414 NxTrkngVldNxLftmEngnRnTmBn6 "NOx Tracking Valid NOx Lifetime Engine Run Time Bin 6: Accumulated Engine run time while all NOx sensors are active over the lifetime of the vehicle for Bin 6. ";
CM_ SG_ 2566588414 NxTrkngVldNxLftmEngnRnTmBn7 "NOx Tracking Valid NOx Lifetime Engine Run Time Bin 7: Accumulated Engine run time while all NOx sensors are active over the lifetime of the vehicle for Bin 7. ";
CM_ SG_ 2566588414 NxTrkngVldNxLftmEngnRnTmBn8 "NOx Tracking Valid NOx Lifetime Engine Run Time Bin 8: Accumulated Engine run time while all NOx sensors are active over the lifetime of the vehicle for Bin 8. ";
CM_ SG_ 2566588414 NxTrkngVldNxLftmEngnRnTmBn9 "NOx Tracking Valid NOx Lifetime Engine Run Time Bin 9: Accumulated Engine run time while all NOx sensors are active over the lifetime of the vehicle for Bin 9";
CM_ SG_ 2566588414 NxTrkngVldNxLftmEngnRnTmBn10 "NOx Tracking Valid NOx Lifetime Engine Run Time Bin 10: Accumulated Engine run time while all NOx sensors are active over the lifetime of the vehicle for Bin 10";
CM_ SG_ 2566588414 NxTrkngVldNxLftmEngnRnTmBn11 "NOx Tracking Valid NOx Lifetime Engine Run Time Bin 11: Accumulated Engine run time while all NOx sensors are active over the lifetime of the vehicle for Bin 11";
CM_ SG_ 2566588414 NxTrkngVldNxLftmEngnRnTmBn12 "NOx Tracking Valid NOx Lifetime Engine Run Time Bin 12: Accumulated Engine run time while all NOx sensors are active over the lifetime of the vehicle for Bin 12";
CM_ SG_ 2566588414 NxTrkngVldNxLftmEngnRnTmBn13 "NOx Tracking Valid NOx Lifetime Engine Run Time Bin 13: Accumulated Engine run time while all NOx sensors are active over the lifetime of the vehicle for Bin 13";
CM_ SG_ 2566588414 NxTrkngVldNxLftmEngnRnTmBn14 "NOx Tracking Valid NOx Lifetime Engine Run Time Bin 14 : Accumulated Engine run time while all NOx sensors are active over the lifetime of the vehicle for Bin 14";
CM_ SG_ 2566588414 NxTVdNxLtERTB15NtB "NOx Tracking Valid NOx Lifetime Engine Run Time Bin 15 (NTE BIN) : Accumulated Engine run time while all NOx sensors are active over the lifetime of the vehicle for Bin 15 [Note Bin 15 is the NTE Bin]";
CM_ SG_ 2566588414 NxTVdNxLtERTB16RB "NOx Tracking Valid NOx Lifetime Engine Run Time Bin 16 (Regen Bin) : Accumulated Engine run time while all NOx sensors are active over the lifetime of the vehicle for Bin 16 [Note Bin 16 is the Regen Bin]";
CM_ SG_ 2566588414 NxTVdNxLtERTB17MOB "NOx Tracking Valid NOx Lifetime Engine Run Time Bin 17 (MIL On Bin) : Accumulated Engine run time while all NOx sensors are active over the lifetime of the vehicle for Bin 17 [Note Bin 17 is the MIL On Bin]";
CM_ BO_ 2566588670 "NOx Tracking Valid NOx Lifetime Vehicle Distance Bins ";
CM_ SG_ 2566588670 NxTrkngVldNxLftmVhlDstnBn1Ttl "NOx Tracking Valid NOx Lifetime Vehicle Distance Bin 1 (Total): Accumulated Vehicle distance while all NOx sensors are active over the lifetime of the vehicle for Bin 1 [Note Bin 1 is the total of Bins 2-14]";
CM_ SG_ 2566588670 NxTrkngVldNxLftmVhlDstnBn2 "NOx Tracking Valid NOx Lifetime Vehicle Distance Bin 2 : Accumulated Vehicle distance while all NOx sensors are active over the lifetime of the vehicle for Bin 2 [Note Bin 2 is the 'idle' bin]";
CM_ SG_ 2566588670 NxTrkngVldNxLftmVhlDstnBn3 "NOx Tracking Valid NOx Lifetime Vehicle Distance Bin 3 : Accumulated Vehicle distance while all NOx sensors are active over the lifetime of the vehicle for Bin 3. ";
CM_ SG_ 2566588670 NxTrkngVldNxLftmVhlDstnBn4 "NOx Tracking Valid NOx Lifetime Vehicle Distance Bin 4: Accumulated Vehicle distance while all NOx sensors are active over the lifetime of the vehicle for Bin 4.";
CM_ SG_ 2566588670 NxTrkngVldNxLftmVhlDstnBn5 "NOx Tracking Valid NOx Lifetime Vehicle Distance Bin 5: Accumulated Vehicle distance while all NOx sensors are active over the lifetime of the vehicle for Bin 5.";
CM_ SG_ 2566588670 NxTrkngVldNxLftmVhlDstnBn6 "NOx Tracking Valid NOx Lifetime Vehicle Distance Bin 6: Accumulated Vehicle distance while all NOx sensors are active over the lifetime of the vehicle for Bin 6. ";
CM_ SG_ 2566588670 NxTrkngVldNxLftmVhlDstnBn7 "NOx Tracking Valid NOx Lifetime Vehicle Distance Bin 7: Accumulated Vehicle distance while all NOx sensors are active over the lifetime of the vehicle for Bin 7. ";
CM_ SG_ 2566588670 NxTrkngVldNxLftmVhlDstnBn8 "NOx Tracking Valid NOx Lifetime Vehicle Distance Bin 8: Accumulated Vehicle distance while all NOx sensors are active over the lifetime of the vehicle for Bin 8. ";
CM_ SG_ 2566588670 NxTrkngVldNxLftmVhlDstnBn9 "NOx Tracking Valid NOx Lifetime Vehicle Distance Bin 9: Accumulated Vehicle distance while all NOx sensors are active over the lifetime of the vehicle for Bin 9";
CM_ SG_ 2566588670 NxTrkngVldNxLftmVhlDstnBn10 "NOx Tracking Valid NOx Lifetime Vehicle Distance Bin 10: Accumulated Vehicle distance while all NOx sensors are active over the lifetime of the vehicle for Bin 10";
CM_ SG_ 2566588670 NxTrkngVldNxLftmVhlDstnBn11 "NOx Tracking Valid NOx Lifetime Vehicle Distance Bin 11: Accumulated Vehicle distance while all NOx sensors are active over the lifetime of the vehicle for Bin 11";
CM_ SG_ 2566588670 NxTrkngVldNxLftmVhlDstnBn12 "NOx Tracking Valid NOx Lifetime Vehicle Distance Bin 12: Accumulated Vehicle distance while all NOx sensors are active over the lifetime of the vehicle for Bin 12";
CM_ SG_ 2566588670 NxTrkngVldNxLftmVhlDstnBn13 "NOx Tracking Valid NOx Lifetime Vehicle Distance Bin 13: Accumulated Vehicle distance while all NOx sensors are active over the lifetime of the vehicle for Bin 13";
CM_ SG_ 2566588670 NxTrkngVldNxLftmVhlDstnBn14 "NOx Tracking Valid NOx Lifetime Vehicle Distance Bin 14 : Accumulated Vehicle distance while all NOx sensors are active over the lifetime of the vehicle for Bin 14";
CM_ SG_ 2566588670 NxTrkngVldNxLftmVhlDstnBn15NtBn "NOx Tracking Valid NOx Lifetime Vehicle Distance Bin 15 (NTE BIN) : Accumulated Vehicle distance while all NOx sensors are active over the lifetime of the vehicle for Bin 15 [Note Bin 15 is the NTE Bin]";
CM_ SG_ 2566588670 NxTVdNxLtVDstB16RB "NOx Tracking Valid NOx Lifetime Vehicle Distance Bin 16 (Regen Bin) : Accumulated Vehicle distance while all NOx sensors are active over the lifetime of the vehicle for Bin 16 [Note Bin 16 is the Regen Bin]";
CM_ SG_ 2566588670 NxTVdNxLtVDstB17MOB "NOx Tracking Valid NOx Lifetime Vehicle Distance Bin 17 (MIL On Bin) : Accumulated Vehicle distance while all NOx sensors are active over the lifetime of the vehicle for Bin 17 [Note Bin 17 is the MIL On Bin]";
CM_ BO_ 2566588926 "NOx Tracking Valid NOx Lifetime Engine Output Energy Bins ";
CM_ SG_ 2566588926 NxTVdNxLtEOtptEB1Tt "NOx Tracking Valid NOx Lifetime Engine Output Energy Bin 1 (Total): Accumulated Engine output energy while all NOx sensors are active over the lifetime of the vehicle for Bin 1 [Note Bin 1 is the total of Bins 2-14]";
CM_ SG_ 2566588926 NxTrkngVldNxLftmEngnOtptEnrgBn2 "NOx Tracking Valid NOx Lifetime Engine Output Energy Bin 2 : Accumulated Engine output energy while all NOx sensors are active over the lifetime of the vehicle for Bin 2 [Note Bin 2 is the 'idle' bin]";
CM_ SG_ 2566588926 NxTrkngVldNxLftmEngnOtptEnrgBn3 "NOx Tracking Valid NOx Lifetime Engine Output Energy Bin 3 : Accumulated Engine output energy while all NOx sensors are active over the lifetime of the vehicle for Bin 3.";
CM_ SG_ 2566588926 NxTrkngVldNxLftmEngnOtptEnrgBn4 "NOx Tracking Valid NOx Lifetime Engine Output Energy Bin 4: Accumulated Engine output energy while all NOx sensors are active over the lifetime of the vehicle for Bin 4. ";
CM_ SG_ 2566588926 NxTrkngVldNxLftmEngnOtptEnrgBn5 "NOx Tracking Valid NOx Lifetime Engine Output Energy Bin 5: Accumulated Engine output energy while all NOx sensors are active over the lifetime of the vehicle for Bin 5.";
CM_ SG_ 2566588926 NxTrkngVldNxLftmEngnOtptEnrgBn6 "NOx Tracking Valid NOx Lifetime Engine Output Energy Bin 6: Accumulated Engine output energy while all NOx sensors are active over the lifetime of the vehicle for Bin 6. ";
CM_ SG_ 2566588926 NxTrkngVldNxLftmEngnOtptEnrgBn7 "NOx Tracking Valid NOx Lifetime Engine Output Energy Bin 7: Accumulated Engine output energy while all NOx sensors are active over the lifetime of the vehicle for Bin 7. ";
CM_ SG_ 2566588926 NxTrkngVldNxLftmEngnOtptEnrgBn8 "NOx Tracking Valid NOx Lifetime Engine Output Energy Bin 8: Accumulated Engine output energy while all NOx sensors are active over the lifetime of the vehicle for Bin 8. ";
CM_ SG_ 2566588926 NxTrkngVldNxLftmEngnOtptEnrgBn9 "NOx Tracking Valid NOx Lifetime Engine Output Energy Bin 9: Accumulated Engine output energy while all NOx sensors are active over the lifetime of the vehicle for Bin 9";
CM_ SG_ 2566588926 NxTVdNxLtEOtptEB10 "NOx Tracking Valid NOx Lifetime Engine Output Energy Bin 10: Accumulated Engine output energy while all NOx sensors are active over the lifetime of the vehicle for Bin 10";
CM_ SG_ 2566588926 NxTVdNxLtEOtptEB11 "NOx Tracking Valid NOx Lifetime Engine Output Energy Bin 11: Accumulated Engine output energy while all NOx sensors are active over the lifetime of the vehicle for Bin 11";
CM_ SG_ 2566588926 NxTVdNxLtEOtptEB12 "NOx Tracking Valid NOx Lifetime Engine Output Energy Bin 12: Accumulated Engine output energy while all NOx sensors are active over the lifetime of the vehicle for Bin 12";
CM_ SG_ 2566588926 NxTVdNxLtEOtptEB13 "NOx Tracking Valid NOx Lifetime Engine Output Energy Bin 13: Accumulated Engine output energy while all NOx sensors are active over the lifetime of the vehicle for Bin 13";
CM_ SG_ 2566588926 NxTVdNxLtEOtptEB14 "NOx Tracking Valid NOx Lifetime Engine Output Energy Bin 14 : Accumulated Engine output energy while all NOx sensors are active over the lifetime of the vehicle for Bin 14";
CM_ SG_ 2566588926 NxTVdNxLtEOtptEB15NtB "NOx Tracking Valid NOx Lifetime Engine Output Energy Bin 15 (NTE BIN) : Accumulated Engine output energy while all NOx sensors are active over the lifetime of the vehicle for Bin 15 [Note Bin 15 is the NTE Bin]";
CM_ SG_ 2566588926 NxTVdNxLtEOtptEB16RB "NOx Tracking Valid NOx Lifetime Engine Output Energy Bin 16 (Regen Bin) : Accumulated Engine output energy while all NOx sensors are active over the lifetime of the vehicle for Bin 16 [Note Bin 16 is the Regen Bin]";
CM_ SG_ 2566588926 NxTVdNxLtEOtptEB17MOB "NOx Tracking Valid NOx Lifetime Engine Output Energy Bin 17 (MIL On Bin) : Accumulated Engine output energy while all NOx sensors are active over the lifetime of the vehicle for Bin 17 [Note Bin 17 is the MIL On Bin]";
CM_ BO_ 2566589182 "NOx Tracking Valid NOx Lifetime Engine Out NOx Mass Bins ";
CM_ SG_ 2566589182 NxTVdNxLtEOtNxMssB1Tt "NOx Tracking Valid NOx Lifetime Engine Out NOx Mass Bin 1 (Total): Accumulated Engine out NOx mass while all NOx sensors are active over the lifetime of the vehicle for Bin 1 [Note Bin 1 is the total of Bins 2-14]";
CM_ SG_ 2566589182 NxTrkngVldNxLftmEngnOtNxMssBn2 "NOx Tracking Valid NOx Lifetime Engine Out NOx Mass Bin 2 : Accumulated Engine out NOx mass while all NOx sensors are active over the lifetime of the vehicle for Bin 2 [Note Bin 2 is the 'idle' bin]";
CM_ SG_ 2566589182 NxTrkngVldNxLftmEngnOtNxMssBn3 "NOx Tracking Valid NOx Lifetime Engine Out NOx Mass Bin 3 : Accumulated Engine out NOx mass while all NOx sensors are active over the lifetime of the vehicle for Bin 3. ";
CM_ SG_ 2566589182 NxTrkngVldNxLftmEngnOtNxMssBn4 "NOx Tracking Valid NOx Lifetime Engine Out NOx Mass Bin 4: Accumulated Engine out NOx mass while all NOx sensors are active over the lifetime of the vehicle for Bin 4. ";
CM_ SG_ 2566589182 NxTrkngVldNxLftmEngnOtNxMssBn5 "NOx Tracking Valid NOx Lifetime Engine Out NOx Mass Bin 5: Accumulated Engine out NOx mass while all NOx sensors are active over the lifetime of the vehicle for Bin 5.";
CM_ SG_ 2566589182 NxTrkngVldNxLftmEngnOtNxMssBn6 "NOx Tracking Valid NOx Lifetime Engine Out NOx Mass Bin 6: Accumulated Engine out NOx mass while all NOx sensors are active over the lifetime of the vehicle for Bin 6. ";
CM_ SG_ 2566589182 NxTrkngVldNxLftmEngnOtNxMssBn7 "NOx Tracking Valid NOx Lifetime Engine Out NOx Mass Bin 7: Accumulated Engine out NOx mass while all NOx sensors are active over the lifetime of the vehicle for Bin 7. ";
CM_ SG_ 2566589182 NxTrkngVldNxLftmEngnOtNxMssBn8 "NOx Tracking Valid NOx Lifetime Engine Out NOx Mass Bin 8: Accumulated Engine out NOx mass while all NOx sensors are active over the lifetime of the vehicle for Bin 8. ";
CM_ SG_ 2566589182 NxTrkngVldNxLftmEngnOtNxMssBn9 "NOx Tracking Valid NOx Lifetime Engine Out NOx Mass Bin 9: Accumulated Engine out NOx mass while all NOx sensors are active over the lifetime of the vehicle for Bin 9";
CM_ SG_ 2566589182 NxTrkngVldNxLftmEngnOtNxMssBn10 "NOx Tracking Valid NOx Lifetime Engine Out NOx Mass Bin 10: Accumulated Engine out NOx mass while all NOx sensors are active over the lifetime of the vehicle for Bin 10";
CM_ SG_ 2566589182 NxTrkngVldNxLftmEngnOtNxMssBn11 "NOx Tracking Valid NOx Lifetime Engine Out NOx Mass Bin 11: Accumulated Engine out NOx mass while all NOx sensors are active over the lifetime of the vehicle for Bin 11";
CM_ SG_ 2566589182 NxTrkngVldNxLftmEngnOtNxMssBn12 "NOx Tracking Valid NOx Lifetime Engine Out NOx Mass Bin 12: Accumulated Engine out NOx mass while all NOx sensors are active over the lifetime of the vehicle for Bin 12";
CM_ SG_ 2566589182 NxTrkngVldNxLftmEngnOtNxMssBn13 "NOx Tracking Valid NOx Lifetime Engine Out NOx Mass Bin 13: Accumulated Engine out NOx mass while all NOx sensors are active over the lifetime of the vehicle for Bin 13";
CM_ SG_ 2566589182 NxTrkngVldNxLftmEngnOtNxMssBn14 "NOx Tracking Valid NOx Lifetime Engine Out NOx Mass Bin 14 : Accumulated Engine out NOx mass while all NOx sensors are active over the lifetime of the vehicle for Bin 14";
CM_ SG_ 2566589182 NxTVdNxLtEOtNxMssB15NtB "NOx Tracking Valid NOx Lifetime Engine Out NOx Mass Bin 15 (NTE BIN) : Accumulated Engine out NOx mass while all NOx sensors are active over the lifetime of the vehicle for Bin 15 [Note Bin 15 is the NTE Bin]";
CM_ SG_ 2566589182 NxTVdNxLtEOtNxMssB16RB "NOx Tracking Valid NOx Lifetime Engine Out NOx Mass Bin 16 (Regen Bin) : Accumulated Engine out NOx mass while all NOx sensors are active over the lifetime of the vehicle for Bin 16 [Note Bin 16 is the Regen Bin]";
CM_ SG_ 2566589182 NxTVdNxLtEOtNxMssB17MOB "NOx Tracking Valid NOx Lifetime Engine Out NOx Mass Bin 17 (MIL On Bin): Accumulated Engine out NOx mass while all NOx sensors are active over the lifetime of the vehicle for Bin 17 [Note Bin 17 is the MIL On Bin]";
CM_ BO_ 2566589438 "NOx Tracking Valid NOx Lifetime System Out NOx Mass Bins ";
CM_ SG_ 2566589438 NxTVdNxLtSstOtNxMssB1Tt "NOx Tracking Valid NOx Lifetime System Out NOx Mass Bin 1 (Total): Accumulated system out [SCR outlet] NOx mass while all NOx sensors are active over the lifetime of the vehicle for Bin 1 [Note Bin 1 is the total of Bins 2-14]";
CM_ SG_ 2566589438 NxTrkngVldNxLftmSstmOtNxMssBn2 "NOx Tracking Valid NOx Lifetime System Out NOx Mass Bin 2 : Accumulated system out [SCR outlet] NOx mass while all NOx sensors are active over the lifetime of the vehicle for Bin 2 [Note Bin 2 is the 'idle' bin]";
CM_ SG_ 2566589438 NxTrkngVldNxLftmSstmOtNxMssBn3 "NOx Tracking Valid NOx Lifetime System Out NOx Mass Bin 3 : Accumulated system out [SCR outlet] NOx mass while all NOx sensors are active over the lifetime of the vehicle for Bin 3. ";
CM_ SG_ 2566589438 NxTrkngVldNxLftmSstmOtNxMssBn4 "NOx Tracking Valid NOx Lifetime System Out NOx Mass Bin 4: Accumulated system out [SCR outlet] NOx mass while all NOx sensors are active over the lifetime of the vehicle for Bin 4.";
CM_ SG_ 2566589438 NxTrkngVldNxLftmSstmOtNxMssBn5 "NOx Tracking Valid NOx Lifetime System Out NOx Mass Bin 5: Accumulated system out [SCR outlet] NOx mass while all NOx sensors are active over the lifetime of the vehicle for Bin 5.";
CM_ SG_ 2566589438 NxTrkngVldNxLftmSstmOtNxMssBn6 "NOx Tracking Valid NOx Lifetime System Out NOx Mass Bin 6: Accumulated system out [SCR outlet] NOx mass while all NOx sensors are active over the lifetime of the vehicle for Bin 6. ";
CM_ SG_ 2566589438 NxTrkngVldNxLftmSstmOtNxMssBn7 "NOx Tracking Valid NOx Lifetime System Out NOx Mass Bin 7: Accumulated system out [SCR outlet] NOx mass while all NOx sensors are active over the lifetime of the vehicle for Bin 7. ";
CM_ SG_ 2566589438 NxTrkngVldNxLftmSstmOtNxMssBn8 "NOx Tracking Valid NOx Lifetime System Out NOx Mass Bin 8: Accumulated system out [SCR outlet] NOx mass while all NOx sensors are active over the lifetime of the vehicle for Bin 8. ";
CM_ SG_ 2566589438 NxTrkngVldNxLftmSstmOtNxMssBn9 "NOx Tracking Valid NOx Lifetime System Out NOx Mass Bin 9: Accumulated system out [SCR outlet] NOx mass while all NOx sensors are active over the lifetime of the vehicle for Bin 9";
CM_ SG_ 2566589438 NxTrkngVldNxLftmSstmOtNxMssBn10 "NOx Tracking Valid NOx Lifetime System Out NOx Mass Bin 10: Accumulated system out [SCR outlet] NOx mass while all NOx sensors are active over the lifetime of the vehicle for Bin 10 ";
CM_ SG_ 2566589438 NxTrkngVldNxLftmSstmOtNxMssBn11 "NOx Tracking Valid NOx Lifetime System Out NOx Mass Bin 11: Accumulated system out [SCR outlet] NOx mass while all NOx sensors are active over the lifetime of the vehicle for Bin 11";
CM_ SG_ 2566589438 NxTrkngVldNxLftmSstmOtNxMssBn12 "NOx Tracking Valid NOx Lifetime System Out NOx Mass Bin 12: Accumulated system out [SCR outlet] NOx mass while all NOx sensors are active over the lifetime of the vehicle for Bin 12";
CM_ SG_ 2566589438 NxTrkngVldNxLftmSstmOtNxMssBn13 "NOx Tracking Valid NOx Lifetime System Out NOx Mass Bin 13: Accumulated system out [SCR outlet] NOx mass while all NOx sensors are active over the lifetime of the vehicle for Bin 13";
CM_ SG_ 2566589438 NxTrkngVldNxLftmSstmOtNxMssBn14 "NOx Tracking Valid NOx Lifetime System Out NOx Mass Bin 14 : Accumulated system out [SCR outlet] NOx mass while all NOx sensors are active over the lifetime of the vehicle for Bin 14";
CM_ SG_ 2566589438 NxTVdNxLtSstOtNxMssB15NtB "NOx Tracking Valid NOx Lifetime System Out NOx Mass Bin 15 (NTE BIN) : Accumulated system out [SCR outlet] NOx mass while all NOx sensors are active over the lifetime of the vehicle for Bin 15 [Note Bin 15 is the Regen Bin]";
CM_ SG_ 2566589438 NxTVdNxLtSstOtNxMssB16RB "NOx Tracking Valid NOx Lifetime System Out NOx Mass Bin 16 (Regen Bin) : Accumulated system out [SCR outlet] NOx mass while all NOx sensors are active over the lifetime of the vehicle for Bin 16 [Note Bin 16 is the Regen Bin]";
CM_ SG_ 2566589438 NxTVdNxLtSstOtNxMssB17MOB "NOx Tracking Valid NOx Lifetime System Out NOx Mass Bin 17 (MIL On Bin) : Accumulated system out [SCR outlet] NOx mass while all NOx sensors are active over the lifetime of the vehicle for Bin 17 [Note Bin 17 is the MIL On Bin]";
CM_ BO_ 2566589694 "NOx Tracking Stored 100 Hour Fuel Consumption Bins ";
CM_ SG_ 2566589694 NxTrkngStrd100HrFlCnsmptnBn1Ttl "NOx Tracking Stored 100 Hour Fuel Consumption Bin 1 (Total): Accumulated Fuel consumption while all NOx sensors are active over the prior 100 hour period for Bin 1 [Note Bin 1 is the total of Bins 2-14]";
CM_ SG_ 2566589694 NxTrkngStrd100HrFlCnsmptnBn2 "NOx Tracking Stored 100 Hour Fuel Consumption Bin 2 : Accumulated Fuel consumption while all NOx sensors are active over the prior 100 hour period for Bin 2 [Note Bin 2 is the 'idle' bin]";
CM_ SG_ 2566589694 NxTrkngStrd100HrFlCnsmptnBn3 "NOx Tracking Stored 100 Hour Fuel Consumption Bin 3 : Accumulated Fuel consumption while all NOx sensors are active over the prior 100 hour period for Bin 3. ";
CM_ SG_ 2566589694 NxTrkngStrd100HrFlCnsmptnBn4 "NOx Tracking Stored 100 Hour Fuel Consumption Bin 4: Accumulated Fuel consumption while all NOx sensors are active over the prior 100 hour period for Bin 4. ";
CM_ SG_ 2566589694 NxTrkngStrd100HrFlCnsmptnBn5 "NOx Tracking Stored 100 Hour Fuel Consumption Bin 5: Accumulated Fuel consumption while all NOx sensors are active over the prior 100 hour period for Bin 5.";
CM_ SG_ 2566589694 NxTrkngStrd100HrFlCnsmptnBn6 "NOx Tracking Stored 100 Hour Fuel Consumption Bin 6: Accumulated Fuel consumption while all NOx sensors are active over the prior 100 hour period for Bin 6. ";
CM_ SG_ 2566589694 NxTrkngStrd100HrFlCnsmptnBn7 "NOx Tracking Stored 100 Hour Fuel Consumption Bin 7: Accumulated Fuel consumption while all NOx sensors are active over the prior 100 hour period for Bin 7. ";
CM_ SG_ 2566589694 NxTrkngStrd100HrFlCnsmptnBn8 "NOx Tracking Stored 100 Hour Fuel Consumption Bin 8: Accumulated Fuel consumption while all NOx sensors are active over the prior 100 hour period for Bin 8. ";
CM_ SG_ 2566589694 NxTrkngStrd100HrFlCnsmptnBn9 "NOx Tracking Stored 100 Hour Fuel Consumption Bin 9: Accumulated Fuel consumption while all NOx sensors are active over the prior 100 hour period for Bin 9";
CM_ SG_ 2566589694 NxTrkngStrd100HrFlCnsmptnBn10 "NOx Tracking Stored 100 Hour Fuel Consumption Bin 10: Accumulated Fuel consumption while all NOx sensors are active over the prior 100 hour period for Bin 10";
CM_ SG_ 2566589694 NxTrkngStrd100HrFlCnsmptnBn11 "NOx Tracking Stored 100 Hour Fuel Consumption Bin 11: Accumulated Fuel consumption while all NOx sensors are active over the prior 100 hour period for Bin 11";
CM_ SG_ 2566589694 NxTrkngStrd100HrFlCnsmptnBn12 "NOx Tracking Stored 100 Hour Fuel Consumption Bin 12: Accumulated Fuel consumption while all NOx sensors are active over the prior 100 hour period for Bin 12";
CM_ SG_ 2566589694 NxTrkngStrd100HrFlCnsmptnBn13 "NOx Tracking Stored 100 Hour Fuel Consumption Bin 13: Accumulated Fuel consumption while all NOx sensors are active over the prior 100 hour period for Bin 13";
CM_ SG_ 2566589694 NxTrkngStrd100HrFlCnsmptnBn14 "NOx Tracking Stored 100 Hour Fuel Consumption Bin 14 : Accumulated Fuel consumption while all NOx sensors are active over the prior 100 hour period for Bin 14";
CM_ SG_ 2566589694 NxTStd100HFCsptB15NtB "NOx Tracking Stored 100 Hour Fuel Consumption Bin 15 (NTE BIN) : Accumulated Fuel consumption while all NOx sensors are active over the prior 100 hour period for Bin 15 [Note Bin 15 is the NTE Bin]";
CM_ SG_ 2566589694 NxTStd100HFCsptB16RB "NOx Tracking Stored 100 Hour Fuel Consumption Bin 16 (Regen Bin) : Accumulated Fuel consumption while all NOx sensors are active over the prior 100 hour period for Bin 16 [Note Bin 16 is the Regen Bin]";
CM_ SG_ 2566589694 NxTStd100HFCsptB17MOB "NOx Tracking Stored 100 Hour Fuel Consumption Bin 17 (MIL On Bin) : Accumulated Fuel consumption while all NOx sensors are active over the prior 100 hour period for Bin 17 [Note Bin 17 is the MIL On Bin]";
CM_ BO_ 2566589950 "NOx Tracking Stored 100 Hour Engine Run Time Bins ";
CM_ SG_ 2566589950 NxTrkngStrd100HrEngnRnTmBn1Ttl "NOx Tracking Stored 100 Hour Engine Run Time Bin 1 (Total): Accumulated Engine run time while all NOx sensors are active over the prior 100 hour period for Bin 1 [Note Bin 1 is the total of Bins 2-14]";
CM_ SG_ 2566589950 NxTrkngStrd100HrEngnRnTmBn2 "NOx Tracking Stored 100 Hour Engine Run Time Bin 2 : Accumulated Engine run time while all NOx sensors are active over the prior 100 hour period for Bin 2 [Note Bin 2 is the 'idle' bin]";
CM_ SG_ 2566589950 NxTrkngStrd100HrEngnRnTmBn3 "NOx Tracking Stored 100 Hour Engine Run Time Bin 3 : Accumulated Engine run time while all NOx sensors are active over the prior 100 hour period for Bin 3.";
CM_ SG_ 2566589950 NxTrkngStrd100HrEngnRnTmBn4 "NOx Tracking Stored 100 Hour Engine Run Time Bin 4: Accumulated Engine run time while all NOx sensors are active over the prior 100 hour period for Bin 4.";
CM_ SG_ 2566589950 NxTrkngStrd100HrEngnRnTmBn5 "NOx Tracking Stored 100 Hour Engine Run Time Bin 5: Accumulated Engine run time while all NOx sensors are active over the prior 100 hour period for Bin 5.";
CM_ SG_ 2566589950 NxTrkngStrd100HrEngnRnTmBn6 "NOx Tracking Stored 100 Hour Engine Run Time Bin 6: Accumulated Engine run time while all NOx sensors are active over the prior 100 hour period for Bin 6. ";
CM_ SG_ 2566589950 NxTrkngStrd100HrEngnRnTmBn7 "NOx Tracking Stored 100 Hour Engine Run Time Bin 7: Accumulated Engine run time while all NOx sensors are active over the prior 100 hour period for Bin 7. ";
CM_ SG_ 2566589950 NxTrkngStrd100HrEngnRnTmBn8 "NOx Tracking Stored 100 Hour Engine Run Time Bin 8: Accumulated Engine run time while all NOx sensors are active over the prior 100 hour period for Bin 8. ";
CM_ SG_ 2566589950 NxTrkngStrd100HrEngnRnTmBn9 "NOx Tracking Stored 100 Hour Engine Run Time Bin 9: Accumulated Engine run time while all NOx sensors are active over the prior 100 hour period for Bin 9";
CM_ SG_ 2566589950 NxTrkngStrd100HrEngnRnTmBn10 "NOx Tracking Stored 100 Hour Engine Run Time Bin 10: Accumulated Engine run time while all NOx sensors are active over the prior 100 hour period for Bin 10";
CM_ SG_ 2566589950 NxTrkngStrd100HrEngnRnTmBn11 "NOx Tracking Stored 100 Hour Engine Run Time Bin 11: Accumulated Engine run time while all NOx sensors are active over the prior 100 hour period for Bin 11";
CM_ SG_ 2566589950 NxTrkngStrd100HrEngnRnTmBn12 "NOx Tracking Stored 100 Hour Engine Run Time Bin 12: Accumulated Engine run time while all NOx sensors are active over the prior 100 hour period for Bin 12";
CM_ SG_ 2566589950 NxTrkngStrd100HrEngnRnTmBn13 "NOx Tracking Stored 100 Hour Engine Run Time Bin 13: Accumulated Engine run time while all NOx sensors are active over the prior 100 hour period for Bin 13";
CM_ SG_ 2566589950 NxTrkngStrd100HrEngnRnTmBn14 "NOx Tracking Stored 100 Hour Engine Run Time Bin 14 : Accumulated Engine run time while all NOx sensors are active over the prior 100 hour period for Bin 14";
CM_ SG_ 2566589950 NxTStd100HERTB15NtB "NOx Tracking Stored 100 Hour Engine Run Time Bin 15 (NTE BIN) : Accumulated Engine run time while all NOx sensors are active over the prior 100 hour period for Bin 15 [Note Bin 15 is the NTE Bin]";
CM_ SG_ 2566589950 NxTStd100HERTB16RB "NOx Tracking Stored 100 Hour Engine Run Time Bin 16 (Regen Bin) : Accumulated Engine run time while all NOx sensors are active over the prior 100 hour period for Bin 16 [Note Bin 16 is the Regen Bin]";
CM_ SG_ 2566589950 NxTStd100HERTB17MOB "NOx Tracking Stored 100 Hour Engine Run Time Bin 17 (MIL On Bin) : Accumulated Engine run time while all NOx sensors are active over the prior 100 hour period for Bin 17 [Note Bin 17 is the MIL On Bin]";
CM_ BO_ 2566590206 "NOx Tracking Stored 100 Hour Vehicle Distance Bins ";
CM_ SG_ 2566590206 NxTrkngStrd100HrVhlDstnBn1Ttl "NOx Tracking Stored 100 Hour Vehicle Distance Bin 1 (Total): Accumulated Vehicle distance while all NOx sensors are active over the prior 100 hour period for Bin 1 [Note Bin 1 is the total of Bins 2-14]";
CM_ SG_ 2566590206 NxTrkngStrd100HrVhlDstnBn2 "NOx Tracking Stored 100 Hour Vehicle Distance Bin 2 : Accumulated Vehicle distance while all NOx sensors are active over the prior 100 hour period for Bin 2 [Note Bin 2 is the 'idle' bin]";
CM_ SG_ 2566590206 NxTrkngStrd100HrVhlDstnBn3 "NOx Tracking Stored 100 Hour Vehicle Distance Bin 3 : Accumulated Vehicle distance while all NOx sensors are active over the prior 100 hour period for Bin 3.";
CM_ SG_ 2566590206 NxTrkngStrd100HrVhlDstnBn4 "NOx Tracking Stored 100 Hour Vehicle Distance Bin 4: Accumulated Vehicle distance while all NOx sensors are active over the prior 100 hour period for Bin 4.";
CM_ SG_ 2566590206 NxTrkngStrd100HrVhlDstnBn5 "NOx Tracking Stored 100 Hour Vehicle Distance Bin 5: Accumulated Vehicle distance while all NOx sensors are active over the prior 100 hour period for Bin 5.";
CM_ SG_ 2566590206 NxTrkngStrd100HrVhlDstnBn6 "NOx Tracking Stored 100 Hour Vehicle Distance Bin 6: Accumulated Vehicle distance while all NOx sensors are active over the prior 100 hour period for Bin 6. ";
CM_ SG_ 2566590206 NxTrkngStrd100HrVhlDstnBn7 "NOx Tracking Stored 100 Hour Vehicle Distance Bin 7: Accumulated Vehicle distance while all NOx sensors are active over the prior 100 hour period for Bin 7. ";
CM_ SG_ 2566590206 NxTrkngStrd100HrVhlDstnBn8 "NOx Tracking Stored 100 Hour Vehicle Distance Bin 8: Accumulated Vehicle distance while all NOx sensors are active over the prior 100 hour period for Bin 8. ";
CM_ SG_ 2566590206 NxTrkngStrd100HrVhlDstnBn9 "NOx Tracking Stored 100 Hour Vehicle Distance Bin 9: Accumulated Vehicle distance while all NOx sensors are active over the prior 100 hour period for Bin 9";
CM_ SG_ 2566590206 NxTrkngStrd100HrVhlDstnBn10 "NOx Tracking Stored 100 Hour Vehicle Distance Bin 10: Accumulated Vehicle distance while all NOx sensors are active over the prior 100 hour period for Bin 10";
CM_ SG_ 2566590206 NxTrkngStrd100HrVhlDstnBn11 "NOx Tracking Stored 100 Hour Vehicle Distance Bin 11: Accumulated Vehicle distance while all NOx sensors are active over the prior 100 hour period for Bin 11";
CM_ SG_ 2566590206 NxTrkngStrd100HrVhlDstnBn12 "NOx Tracking Stored 100 Hour Vehicle Distance Bin 12: Accumulated Vehicle distance while all NOx sensors are active over the prior 100 hour period for Bin 12";
CM_ SG_ 2566590206 NxTrkngStrd100HrVhlDstnBn13 "NOx Tracking Stored 100 Hour Vehicle Distance Bin 13: Accumulated Vehicle distance while all NOx sensors are active over the prior 100 hour period for Bin 13";
CM_ SG_ 2566590206 NxTrkngStrd100HrVhlDstnBn14 "NOx Tracking Stored 100 Hour Vehicle Distance Bin 14 : Accumulated Vehicle distance while all NOx sensors are active over the prior 100 hour period for Bin 14";
CM_ SG_ 2566590206 NxTrkngStrd100HrVhlDstnBn15NtBn "NOx Tracking Stored 100 Hour Vehicle Distance Bin 15 (NTE BIN) : Accumulated Vehicle distance while all NOx sensors are active over the prior 100 hour period for Bin 15 [Note Bin 15 is the NTE Bin]";
CM_ SG_ 2566590206 NxTStd100HVDstB16RB "NOx Tracking Stored 100 Hour Vehicle Distance Bin 16 (Regen Bin) : Accumulated Vehicle distance while all NOx sensors are active over the prior 100 hour period for Bin 16 [Note Bin 16 is the Regen Bin]";
CM_ SG_ 2566590206 NxTStd100HVDstB17MOB "NOx Tracking Stored 100 Hour Vehicle Distance Bin 17 (MIL On Bin) : Accumulated Vehicle distance while all NOx sensors are active over the prior 100 hour period for Bin 17 [Note Bin 17 is the MIL ON Bin]";
BA_DEF_ SG_  "SPN" INT 0 524287;
BA_DEF_ BO_  "VFrameFormat" ENUM  "StandardCAN","ExtendedCAN","reserved","J1939PG";
BA_DEF_DEF_  "SPN" 0;
BA_DEF_DEF_  "VFrameFormat" "J1939PG";
BA_ "SPN" SG_ 2565995006 MtrGnrtr5InvrtrLmtsAtvPwrCntr 12070;
BA_ "SPN" SG_ 2565995006 MtGt5IvtLtsAtvMPwMx 12071;
BA_ "SPN" SG_ 2565995006 MtGt5IvtLtsAtvMPwM 12072;
BA_ "SPN" SG_ 2565995006 MtrGnrtr5InvrtrLmtsAtvPwrCr 12069;
BA_ "SPN" SG_ 2565995006 MtGt5IvtLtsAtvDSdPwMx 12073;
BA_ "SPN" SG_ 2565995006 MtGt5IvtLtsAtvDSdPwM 12074;
BA_ "SPN" SG_ 2565995262 MtrGnrtr5InvrtrLmtsAtvMhnlCntr 12082;
BA_ "SPN" SG_ 2565995262 MtrGnrtr5InvrtrLmtsAtvTrqMxmm 12083;
BA_ "SPN" SG_ 2565995262 MtrGnrtr5InvrtrLmtsAtvTrqMnmm 12084;
BA_ "SPN" SG_ 2565995262 MtrGnrtr5InvrtrLmtsAtvSpdMxmm 12085;
BA_ "SPN" SG_ 2565995262 MtrGnrtr5InvrtrLmtsAtvSpdMnmm 12086;
BA_ "SPN" SG_ 2565995262 MtrGnrtr5InvrtrLmtsAtvMhnlCr 12081;
BA_ "SPN" SG_ 2565995518 MtrGnrtr5InvrtrLmtsAtvDSdCr 12097;
BA_ "SPN" SG_ 2565995518 MtrGnrtr5InvrtrLmtsAtvDSdCntr 12098;
BA_ "SPN" SG_ 2565995518 MtGt5IvtLtsAtvDSdVtMx 12099;
BA_ "SPN" SG_ 2565995518 MtGt5IvtLtsAtvDSdVtM 12100;
BA_ "SPN" SG_ 2565995518 MtGt5IvtLtsAtvDSdCtMx 12101;
BA_ "SPN" SG_ 2565995518 MtGt5IvtLtsAtvDSdCtM 12102;
BA_ "SPN" SG_ 2565995774 MtrGnrtr5InvrtrSwthdIgntnVltg 12042;
BA_ "SPN" SG_ 2565995774 MtrGnrtr5InvrtrUnswthdSlVltg 12043;
BA_ "SPN" SG_ 2565996030 MtrGnrtr5InvrtrStts2Cntr 12111;
BA_ "SPN" SG_ 2565996030 MtrGnrtr5AvllMxmmTrq 12112;
BA_ "SPN" SG_ 2565996030 MtrGnrtr5AvllMnmmTrq 12113;
BA_ "SPN" SG_ 2565996030 MtrGnrtr5InvrtrStts2Cr 12110;
BA_ "SPN" SG_ 2565996286 MtrGnrtr5InvrtrRtLmtsAtv1Cntr 12145;
BA_ "SPN" SG_ 2565996286 MtGt5IvtRtLtsAtvAstSpdRtLt 12146;
BA_ "SPN" SG_ 2565996286 MtGt5IvtRtLtsAtvAstTqRtLt 12147;
BA_ "SPN" SG_ 2565996286 MtrGnrtr5InvrtrRtLmtsAtv1Cr 12144;
BA_ "SPN" SG_ 2364669950 MtrGnrtr6InvrtrMdFdk1Cntr 12170;
BA_ "SPN" SG_ 2364669950 MtrGnrtr6InvrtrCntrlLmtsOvrrdMd 12171;
BA_ "SPN" SG_ 2364669950 MtrGnrtr6InvrtrCntrlStpntMd 12172;
BA_ "SPN" SG_ 2364669950 MtrGnrtr6InvrtrMdFdk1Cr 12169;
BA_ "SPN" SG_ 2364669950 MtrGnrtr6InvrtrHvlStts 12159;
BA_ "SPN" SG_ 2565996798 MtrGnrtr6InvrtrLmtsAtvPwrCntr 12188;
BA_ "SPN" SG_ 2565996798 MtGt6IvtLtsAtvMPwMx 12189;
BA_ "SPN" SG_ 2565996798 MtGt6IvtLtsAtvMPwM 12190;
BA_ "SPN" SG_ 2565996798 MtrGnrtr6InvrtrLmtsAtvPwrCr 12187;
BA_ "SPN" SG_ 2565996798 MtGt6IvtLtsAtvDSdPwMx 12191;
BA_ "SPN" SG_ 2565996798 MtGt6IvtLtsAtvDSdPwM 12192;
BA_ "SPN" SG_ 2565997054 MtrGnrtr6InvrtrLmtsAtvMhnlCntr 12200;
BA_ "SPN" SG_ 2565997054 MtrGnrtr6InvrtrLmtsAtvTrqMxmm 12201;
BA_ "SPN" SG_ 2565997054 MtrGnrtr6InvrtrLmtsAtvTrqMnmm 12202;
BA_ "SPN" SG_ 2565997054 MtrGnrtr6InvrtrLmtsAtvSpdMxmm 12203;
BA_ "SPN" SG_ 2565997054 MtrGnrtr6InvrtrLmtsAtvSpdMnmm 12204;
BA_ "SPN" SG_ 2565997054 MtrGnrtr6InvrtrLmtsAtvMhnlCr 12199;
BA_ "SPN" SG_ 2565997310 MtrGnrtr6InvrtrLmtsAtvDSdCr 12215;
BA_ "SPN" SG_ 2565997310 MtrGnrtr6InvrtrLmtsAtvDSdCntr 12216;
BA_ "SPN" SG_ 2565997310 MtGt6IvtLtsAtvDSdVtMx 12217;
BA_ "SPN" SG_ 2565997310 MtGt6IvtLtsAtvDSdVtM 12218;
BA_ "SPN" SG_ 2565997310 MtGt6IvtLtsAtvDSdCtMx 12219;
BA_ "SPN" SG_ 2565997310 MtGt6IvtLtsAtvDSdCtM 12220;
BA_ "SPN" SG_ 2565997566 MtrGnrtr6InvrtrSwthdIgntnVltg 12160;
BA_ "SPN" SG_ 2565997566 MtrGnrtr6InvrtrUnswthdSlVltg 12161;
BA_ "SPN" SG_ 2565997822 MtrGnrtr6InvrtrStts2Cntr 12229;
BA_ "SPN" SG_ 2565997822 MtrGnrtr6AvllMxmmTrq 12230;
BA_ "SPN" SG_ 2565997822 MtrGnrtr6AvllMnmmTrq 12231;
BA_ "SPN" SG_ 2565997822 MtrGnrtr6InvrtrStts2Cr 12228;
BA_ "SPN" SG_ 2565998078 MtrGnrtr6InvrtrRtLmtsAtv1Cntr 12263;
BA_ "SPN" SG_ 2565998078 MtGt6IvtRtLtsAtvAstSpdRtLt 12264;
BA_ "SPN" SG_ 2565998078 MtGt6IvtRtLtsAtvAstTqRtLt 12265;
BA_ "SPN" SG_ 2565998078 MtrGnrtr6InvrtrRtLmtsAtv1Cr 12262;
BA_ "SPN" SG_ 2364671742 BlindSpotDetectionState 12286;
BA_ "SPN" SG_ 2364671742 BlindSpotCollisionWarningLevel 12287;
BA_ "SPN" SG_ 2364671742 BlndSptWrnngRlvntOjtDttd 12288;
BA_ "SPN" SG_ 2364671742 BlndSptDttnLftSdMntrd 12290;
BA_ "SPN" SG_ 2364671742 BlndSptDttnRghtSdMntrd 12291;
BA_ "SPN" SG_ 2364671742 BlndSptDttnFrntMntrd 12292;
BA_ "SPN" SG_ 2364671742 BlindSpotDetectionRearMonitored 12293;
BA_ "SPN" SG_ 2364671742 BndOffPrltOfMstImprtntOjt 12289;
BA_ "SPN" SG_ 2364671998 WinchMotorEncoderPosition 12309;
BA_ "SPN" SG_ 2364671998 WinchRevolutionCounter 12310;
BA_ "SPN" SG_ 2364671998 WinchMotorSpeed 15265;
BA_ "SPN" SG_ 2364671998 WinchMotorDirection 15266;
BA_ "SPN" SG_ 2364671998 WinchMotorOverspeed 15267;
BA_ "SPN" SG_ 2364672254 MtrGnrtr3InvrtrCntrlCntr 11809;
BA_ "SPN" SG_ 2364672254 MtGt3IvtCtLtsRqstOvdMd 11810;
BA_ "SPN" SG_ 2364672254 MtGt3IvtCtLtsRqstOvdMx 11811;
BA_ "SPN" SG_ 2364672254 MtGt3IvtCtLtsRqstOvdM 11812;
BA_ "SPN" SG_ 2364672254 MtrGnrtr3InvrtrCntrlStpntMdRqst 11813;
BA_ "SPN" SG_ 2364672254 MtrGnrtr3InvrtrCntrlStpntRqst 11814;
BA_ "SPN" SG_ 2364672254 MtrGnrtr3InvrtrCntrlCr 11808;
BA_ "SPN" SG_ 2565999102 MtrGnrtr3InvrtrRtLmtsRqst1Cntr 11905;
BA_ "SPN" SG_ 2565999102 MtGt3IvtRtLtsRqstAstSpdRtLt 11906;
BA_ "SPN" SG_ 2565999102 MtGt3IvtRtLtsRqstAstTqRtLt 11907;
BA_ "SPN" SG_ 2565999102 MtrGnrtr3InvrtrRtLmtsRqst1Cr 11904;
BA_ "SPN" SG_ 2364672766 MtrGnrtr4InvrtrCntrlCntr 11927;
BA_ "SPN" SG_ 2364672766 MtGt4IvtCtLtsRqstOvdMd 11928;
BA_ "SPN" SG_ 2364672766 MtGt4IvtCtLtsRqstOvdMx 11929;
BA_ "SPN" SG_ 2364672766 MtGt4IvtCtLtsRqstOvdM 11930;
BA_ "SPN" SG_ 2364672766 MtrGnrtr4InvrtrCntrlStpntMdRqst 11931;
BA_ "SPN" SG_ 2364672766 MtrGnrtr4InvrtrCntrlStpntRqst 11932;
BA_ "SPN" SG_ 2364672766 MtrGnrtr4InvrtrCntrlCr 11926;
BA_ "SPN" SG_ 2565999614 MtrGnrtr4InvrtrRtLmtsRqst1Cntr 12023;
BA_ "SPN" SG_ 2565999614 MtGt4IvtRtLtsRqstAstSpdRtLt 12024;
BA_ "SPN" SG_ 2565999614 MtGt4IvtRtLtsRqstAstTqRtLt 12025;
BA_ "SPN" SG_ 2565999614 MtrGnrtr4InvrtrRtLmtsRqst1Cr 12022;
BA_ "SPN" SG_ 2364673278 MtrGnrtr5InvrtrCntrlCntr 12045;
BA_ "SPN" SG_ 2364673278 MtGt5IvtCtLtsRqstOvdMd 12046;
BA_ "SPN" SG_ 2364673278 MtGt5IvtCtLtsRqstOvdMx 12047;
BA_ "SPN" SG_ 2364673278 MtGt5IvtCtLtsRqstOvdM 12048;
BA_ "SPN" SG_ 2364673278 MtrGnrtr5InvrtrCntrlStpntMdRqst 12049;
BA_ "SPN" SG_ 2364673278 MtrGnrtr5InvrtrCntrlStpntRqst 12050;
BA_ "SPN" SG_ 2364673278 MtrGnrtr5InvrtrCntrlCr 12044;
BA_ "SPN" SG_ 2566000126 MtrGnrtr5InvrtrRtLmtsRqst1Cntr 12141;
BA_ "SPN" SG_ 2566000126 MtGt5IvtRtLtsRqstAstSpdRtLt 12142;
BA_ "SPN" SG_ 2566000126 MtGt5IvtRtLtsRqstAstTqRtLt 12143;
BA_ "SPN" SG_ 2566000126 MtrGnrtr5InvrtrRtLmtsRqst1Cr 12140;
BA_ "SPN" SG_ 2364673790 MtrGnrtr6InvrtrCntrlCntr 12163;
BA_ "SPN" SG_ 2364673790 MtGt6IvtCtLtsRqstOvdMd 12164;
BA_ "SPN" SG_ 2364673790 MtGt6IvtCtLtsRqstOvdMx 12165;
BA_ "SPN" SG_ 2364673790 MtGt6IvtCtLtsRqstOvdM 12166;
BA_ "SPN" SG_ 2364673790 MtrGnrtr6InvrtrCntrlStpntMdRqst 12167;
BA_ "SPN" SG_ 2364673790 MtrGnrtr6InvrtrCntrlStpntRqst 12168;
BA_ "SPN" SG_ 2364673790 MtrGnrtr6InvrtrCntrlCr 12162;
BA_ "SPN" SG_ 2566000638 MtrGnrtr6InvrtrRtLmtsRqst1Cntr 12259;
BA_ "SPN" SG_ 2566000638 MtGt6IvtRtLtsRqstAstSpdRtLt 12260;
BA_ "SPN" SG_ 2566000638 MtGt6IvtRtLtsRqstAstTqRtLt 12261;
BA_ "SPN" SG_ 2566000638 MtrGnrtr6InvrtrRtLmtsRqst1Cr 12258;
BA_ "SPN" SG_ 2566574078 EvccControlPilotMaximumVoltage 12927;
BA_ "SPN" SG_ 2566574078 EvccControlPilotMinimumVoltage 12928;
BA_ "SPN" SG_ 2566574078 EvccControlPilotPwmFrequency 12929;
BA_ "SPN" SG_ 2566574078 EvccControlPilotDutyCycle 12930;
BA_ "SPN" SG_ 2566574078 EvccControlPilotState 12931;
BA_ "SPN" SG_ 2566574078 EvccControlPilotSubState 12932;
BA_ "SPN" SG_ 2566574078 EvccProximityCircuitVoltage 12933;
BA_ "SPN" SG_ 2566574078 EvccInletConnectorTemperature 12934;
BA_ "SPN" SG_ 2566574078 EvccCompatibilityCode 12935;
BA_ "SPN" SG_ 2499465470 Mirror1LeftRightSelection 12923;
BA_ "SPN" SG_ 2499465470 Mirror2LeftRightSelection 12924;
BA_ "SPN" SG_ 2499465470 MirrorPrimarySecondarySelection 12925;
BA_ "SPN" SG_ 2499465726 EngnClndrTmprtrAvrg 12894;
BA_ "SPN" SG_ 2499465726 EngnClndrBnk1TmprtrAvrg 12895;
BA_ "SPN" SG_ 2499465726 EngnClndrBnk2TmprtrAvrg 12896;
BA_ "SPN" SG_ 2566574846 EngnTrhrgr3OlTmprtr 12889;
BA_ "SPN" SG_ 2566574846 EngnTrhrgr4OlTmprtr 12890;
BA_ "SPN" SG_ 2566574846 EngnTrhrgr5OlTmprtr 12891;
BA_ "SPN" SG_ 2566574846 EngnTrhrgr6OlTmprtr 12892;
BA_ "SPN" SG_ 2566575102 Ts1CntrlPrpsP7InhtCmmnd 12868;
BA_ "SPN" SG_ 2566575102 AdsVehicleSpeedControlConsent 15247;
BA_ "SPN" SG_ 2566575102 Adsc1EmbeddedIntegritySupport 22265;
BA_ "SPN" SG_ 2566575102 Adsc1Counter 22266;
BA_ "SPN" SG_ 2566575102 Adsc1Crc 22267;
BA_ "SPN" SG_ 2566575358 EvseAcRmsCurrent 12866;
BA_ "SPN" SG_ 2566575358 EvseAcRmsVoltage 12867;
BA_ "SPN" SG_ 2566575614 EvseAcRmsCurrentLimitL1 12865;
BA_ "SPN" SG_ 2566575614 EvseAcRmsCurrentLimitL2 13003;
BA_ "SPN" SG_ 2566575614 EvseAcRmsCurrentLimitL3 13004;
BA_ "SPN" SG_ 2566575614 EvseAcRmsCurrentLimitNeutral 13005;
BA_ "SPN" SG_ 2566575870 EvseConnectorReleaseLatch 12861;
BA_ "SPN" SG_ 2566575870 EvseManualOverride 12862;
BA_ "SPN" SG_ 2566575870 EvseConnectorLockState 12863;
BA_ "SPN" SG_ 2566575870 EvseConnectorLockPermission 21086;
BA_ "SPN" SG_ 2566575870 InletContactorState 22688;
BA_ "SPN" SG_ 2566575870 EvseInletState 22689;
BA_ "SPN" SG_ 2566575870 EvseConnectionType 22690;
BA_ "SPN" SG_ 2566575870 EvseCommunicationsPhysicalLayer 22691;
BA_ "SPN" SG_ 2566581758 TmprtrSnsngMdl1PrlmnrFm 12820;
BA_ "SPN" SG_ 2566581758 TmprtrSnsngMdl2PrlmnrFm 12821;
BA_ "SPN" SG_ 2566581758 TmprtrSnsngMdl3PrlmnrFm 12822;
BA_ "SPN" SG_ 2566581758 TmprtrSnsngMdl4PrlmnrFm 12823;
BA_ "SPN" SG_ 2566581758 TmprtrSnsngMdl5PrlmnrFm 12824;
BA_ "SPN" SG_ 2566581758 TmprtrSnsngMdl6PrlmnrFm 12825;
BA_ "SPN" SG_ 2566581758 TmprtrSnsngMdl7PrlmnrFm 12826;
BA_ "SPN" SG_ 2566581758 TmprtrSnsngMdl8PrlmnrFm 12827;
BA_ "SPN" SG_ 2566582014 TmprtrSnsngMdl9PrlmnrFm 12828;
BA_ "SPN" SG_ 2566582014 TmprtrSnsngMdl10PrlmnrFm 12829;
BA_ "SPN" SG_ 2566582014 TmprtrSnsngMdl11PrlmnrFm 12830;
BA_ "SPN" SG_ 2566582014 TmprtrSnsngMdl12PrlmnrFm 12831;
BA_ "SPN" SG_ 2566582014 TmprtrSnsngMdl13PrlmnrFm 12832;
BA_ "SPN" SG_ 2566582014 TmprtrSnsngMdl14PrlmnrFm 12833;
BA_ "SPN" SG_ 2566582014 TmprtrSnsngMdl15PrlmnrFm 12834;
BA_ "SPN" SG_ 2566582014 TmprtrSnsngMdl16PrlmnrFm 12835;
BA_ "SPN" SG_ 2566582270 Aftrtrtmnt2SrNrmlzdCnvrsnEffn 12860;
BA_ "SPN" SG_ 2566582526 Aftrtrtmnt1SrNrmlzdCnvrsnEffn 12859;
BA_ "SPN" SG_ 2566582526 Atttt1DsExstFdUsdTsOptC 21225;
BA_ "SPN" SG_ 2566582782 HrdLftmPrplsnSstmAtvTm 12797;
BA_ "SPN" SG_ 2566582782 HrdLftmIdlPrplsnSstmAtvTm 12798;
BA_ "SPN" SG_ 2566582782 HrdLftmUrnPrplsnSstmAtvTm 12799;
BA_ "SPN" SG_ 2566583038 HrdStrd100HrRntPrplsnSstmAtvTm 12794;
BA_ "SPN" SG_ 2566583038 HrdStrd100HrIdlPrplsnSstmAtvTm 12795;
BA_ "SPN" SG_ 2566583038 HrdStrd100HrUrnPrplsnSstmAtvTm 12796;
BA_ "SPN" SG_ 2566583294 HrdAtv100HrPrplsnSstmAtvTm 12791;
BA_ "SPN" SG_ 2566583294 HrdAtv100HrIdlPrplsnSstmAtvTm 12792;
BA_ "SPN" SG_ 2566583294 HrdAtv100HrUrnPrplsnSstmAtvTm 12793;
BA_ "SPN" SG_ 2566583550 HdLtDstTvdICDptOptWtEO 12783;
BA_ "SPN" SG_ 2566583550 HdLtDstTvdICDptOptWtER 12784;
BA_ "SPN" SG_ 2566583550 HdLtDstTvdIDvStCIsOpt 12785;
BA_ "SPN" SG_ 2566583550 HrdLftmFlCnsmdInChrgDpltngOprtn 12786;
BA_ "SPN" SG_ 2566583550 HdLtFCsdIDvStCIsOpt 12787;
BA_ "SPN" SG_ 2566583550 HdLtGdECsdICDptOptWtEO 12788;
BA_ "SPN" SG_ 2566583550 HdLtGdECsdICDptOptWtER 12789;
BA_ "SPN" SG_ 2566583550 HrdLftmGrdEnrgIntThBttr 12790;
BA_ "SPN" SG_ 2566583806 HdStd100HDstTvdICDptOptWtEO 12775;
BA_ "SPN" SG_ 2566583806 HdStd100HDstTvdICDptOptWtER 12776;
BA_ "SPN" SG_ 2566583806 HdStd100HDstTvdIDvStCIsOpt 12777;
BA_ "SPN" SG_ 2566583806 HdStd100HFCsdICDptOpt 12778;
BA_ "SPN" SG_ 2566583806 HdStd100HFCsdIDvStCIsOpt 12779;
BA_ "SPN" SG_ 2566583806 HdStd100HGdECsdICDptOptWtEO 12780;
BA_ "SPN" SG_ 2566583806 HdStd100HGdECsdICDptOptWtER 12781;
BA_ "SPN" SG_ 2566583806 HrdStrd100HrGrdEnrgIntThBttr 12782;
BA_ "SPN" SG_ 2566584062 HdAtv100HDstTvdICDptOptWtEO 12767;
BA_ "SPN" SG_ 2566584062 HdAtv100HDstTvdICDptOptWtER 12768;
BA_ "SPN" SG_ 2566584062 HdAtv100HDstTvdIDvStCIsOpt 12769;
BA_ "SPN" SG_ 2566584062 HdAtv100HFCsdICDptOpt 12770;
BA_ "SPN" SG_ 2566584062 HdAtv100HFCsdIDvStCIsOpt 12771;
BA_ "SPN" SG_ 2566584062 HdAtv100HGdECsdICDptOptWtEO 12772;
BA_ "SPN" SG_ 2566584062 HdAtv100HGdECsdICDptOptWtER 12773;
BA_ "SPN" SG_ 2566584062 HrdAtv100HrGrdEnrgIntThBttr 12774;
BA_ "SPN" SG_ 2566584318 Atttt1TtERtWtNDDv 12765;
BA_ "SPN" SG_ 2566584318 Atttt1DpRtCptSttEVDst1 12759;
BA_ "SPN" SG_ 2566584318 Atttt1DpRtCptEdEVDst1 12760;
BA_ "SPN" SG_ 2566584318 Atttt1DpRtCptSttEVDst2 12761;
BA_ "SPN" SG_ 2566584318 Atttt1DpRtCptEdEVDst2 12762;
BA_ "SPN" SG_ 2566584318 Atttt1DpRtCptSttEVDst3 12763;
BA_ "SPN" SG_ 2566584318 Atttt1DpRtCptEdEVDst3 12764;
BA_ "SPN" SG_ 2566584318 Atttt1TtTSItTptBw200Css 12766;
BA_ "SPN" SG_ 2566584830 Aftrtrtmnt1Sr2InltNxMssFlw 12754;
BA_ "SPN" SG_ 2566584830 Aftrtrtmnt1Sr2OtltNxMssFlw 12755;
BA_ "SPN" SG_ 2566584830 Aftrtrtmnt1Sr2MdldNh3StrgLvl 12756;
BA_ "SPN" SG_ 2566584830 Aftrtrtmnt1Sr2TrgtNh3StrgLvl 12757;
BA_ "SPN" SG_ 2566585086 Aftrtrtmnt1Sr1EngnExhstNxMssFlw 12750;
BA_ "SPN" SG_ 2566585086 Aftrtrtmnt1Sr1TlppNxMssFlw 12751;
BA_ "SPN" SG_ 2566585086 Aftrtrtmnt1Sr1MdldAtlStrgLvl 12752;
BA_ "SPN" SG_ 2566585086 Aftrtrtmnt1Sr1TrgtNh3StrgLvl 12753;
BA_ "SPN" SG_ 2566585342 EvapSystemPurgePressure 12744;
BA_ "SPN" SG_ 2566585342 EvapSystemVaporPressure 12745;
BA_ "SPN" SG_ 2566585342 EvapSystemPurgeValveCommand 12746;
BA_ "SPN" SG_ 2566585342 EvapSystemPurgeValvePosition 12747;
BA_ "SPN" SG_ 2566585598 GhgTrkngLftmEngnRnTm 12730;
BA_ "SPN" SG_ 2566585598 GhgTrkngLftmVhlDstn 12731;
BA_ "SPN" SG_ 2566585598 GhgTrkngLftmVhlFlCnsmptn 12732;
BA_ "SPN" SG_ 2566585598 GhgTrkngLftmEngnFlCnsmptn 12733;
BA_ "SPN" SG_ 2566585598 GhgTrkngLftmEngnOtptEnrg 12734;
BA_ "SPN" SG_ 2566585598 GhgTrkngLftmPstvKntEnrgNmrtr 12735;
BA_ "SPN" SG_ 2566585598 GhgTrkngLftmUrnSpdRnTm 12736;
BA_ "SPN" SG_ 2566585598 GhgTrackingLifetimeIdleRunTime 12737;
BA_ "SPN" SG_ 2566585598 GhgTrkngLftmEngnIdlFlCnsmptn 12738;
BA_ "SPN" SG_ 2566585598 GhgTrkngLftmEngnPwrTkOffRnTm 12739;
BA_ "SPN" SG_ 2566585598 GhgTrkngLftmStpStrtThnlgRnTm 12742;
BA_ "SPN" SG_ 2566585598 GTLtEPwTOFCspt 12740;
BA_ "SPN" SG_ 2566585598 GTLtAttEStdwTAtvtCt 12741;
BA_ "SPN" SG_ 2566585854 GhgTrkngStrd100HrEngnRnTm 12715;
BA_ "SPN" SG_ 2566585854 GhgTrkngStrd100HrVhlDstn 12716;
BA_ "SPN" SG_ 2566585854 GhgTrkngStrd100HrVhlFlCnsmptn 12717;
BA_ "SPN" SG_ 2566585854 GhgTrkngStrd100HrEngnFlCnsmptn 12718;
BA_ "SPN" SG_ 2566585854 GhgTrkngStrd100HrEngnOtptEnrg 12719;
BA_ "SPN" SG_ 2566585854 GhgTrkngStrd100HrUrnSpdRnTm 12721;
BA_ "SPN" SG_ 2566585854 GhgTrkngStrd100HrIdlRnTm 12722;
BA_ "SPN" SG_ 2566585854 GTStd100HPstvKtENt 12720;
BA_ "SPN" SG_ 2566585854 GTStd100HEIdFCspt 12723;
BA_ "SPN" SG_ 2566585854 GTStd100HEPwTORT 12724;
BA_ "SPN" SG_ 2566585854 GTStd100HEPwTOFCspt 12725;
BA_ "SPN" SG_ 2566585854 GTStd100HAttEStdwTAtvtCt 12726;
BA_ "SPN" SG_ 2566585854 GTStd100HStpSttTRT 12727;
BA_ "SPN" SG_ 2566586110 GhgTrkngAtv100HrEngnRnTm 12700;
BA_ "SPN" SG_ 2566586110 GhgTrkngAtv100HrVhlDstn 12701;
BA_ "SPN" SG_ 2566586110 GhgTrkngAtv100HrVhlFlCnsmptn 12702;
BA_ "SPN" SG_ 2566586110 GhgTrkngAtv100HrEngnFlCnsmptn 12703;
BA_ "SPN" SG_ 2566586110 GhgTrkngAtv100HrEngnOtptEnrg 12704;
BA_ "SPN" SG_ 2566586110 GhgTrkngAtv100HrUrnSpdRnTm 12706;
BA_ "SPN" SG_ 2566586110 GhgTrkngAtv100HrIdlRnTm 12707;
BA_ "SPN" SG_ 2566586110 GTAtv100HPstvKtENt 12705;
BA_ "SPN" SG_ 2566586110 GTAtv100HEIdFCspt 12708;
BA_ "SPN" SG_ 2566586110 GTAtv100HEPwTORT 12709;
BA_ "SPN" SG_ 2566586110 GTAtv100HEPwTOFCspt 12710;
BA_ "SPN" SG_ 2566586110 GTAtv100HAttEStdwTAtvtCt 12711;
BA_ "SPN" SG_ 2566586110 GTAtv100HStpSttTRT 12712;
BA_ "SPN" SG_ 2566587134 NxTEAtvtLtFCsptB1Tt 12675;
BA_ "SPN" SG_ 2566587134 NxTrkngEngnAtvtLftmFlCnsmptnBn2 12676;
BA_ "SPN" SG_ 2566587134 NxTrkngEngnAtvtLftmFlCnsmptnBn3 12677;
BA_ "SPN" SG_ 2566587134 NxTrkngEngnAtvtLftmFlCnsmptnBn4 12678;
BA_ "SPN" SG_ 2566587134 NxTrkngEngnAtvtLftmFlCnsmptnBn5 12679;
BA_ "SPN" SG_ 2566587134 NxTrkngEngnAtvtLftmFlCnsmptnBn6 12680;
BA_ "SPN" SG_ 2566587134 NxTrkngEngnAtvtLftmFlCnsmptnBn7 12681;
BA_ "SPN" SG_ 2566587134 NxTrkngEngnAtvtLftmFlCnsmptnBn8 12682;
BA_ "SPN" SG_ 2566587134 NxTrkngEngnAtvtLftmFlCnsmptnBn9 12683;
BA_ "SPN" SG_ 2566587134 NxTEAtvtLtFCsptB10 12684;
BA_ "SPN" SG_ 2566587134 NxTEAtvtLtFCsptB11 12685;
BA_ "SPN" SG_ 2566587134 NxTEAtvtLtFCsptB12 12686;
BA_ "SPN" SG_ 2566587134 NxTEAtvtLtFCsptB13 12687;
BA_ "SPN" SG_ 2566587134 NxTEAtvtLtFCsptB14 12688;
BA_ "SPN" SG_ 2566587134 NxTEAtvtLtFCsptB15NtB 12689;
BA_ "SPN" SG_ 2566587134 NxTEAtvtLtFCsptB16RB 12690;
BA_ "SPN" SG_ 2566587134 NxTEAtvtLtFCsptB17MOB 12713;
BA_ "SPN" SG_ 2566587390 NxTEAtvtLtERTB1Tt 12659;
BA_ "SPN" SG_ 2566587390 NxTrkngEngnAtvtLftmEngnRnTmBn2 12660;
BA_ "SPN" SG_ 2566587390 NxTrkngEngnAtvtLftmEngnRnTmBn3 12661;
BA_ "SPN" SG_ 2566587390 NxTrkngEngnAtvtLftmEngnRnTmBn4 12662;
BA_ "SPN" SG_ 2566587390 NxTrkngEngnAtvtLftmEngnRnTmBn5 12663;
BA_ "SPN" SG_ 2566587390 NxTrkngEngnAtvtLftmEngnRnTmBn6 12664;
BA_ "SPN" SG_ 2566587390 NxTrkngEngnAtvtLftmEngnRnTmBn7 12665;
BA_ "SPN" SG_ 2566587390 NxTrkngEngnAtvtLftmEngnRnTmBn8 12666;
BA_ "SPN" SG_ 2566587390 NxTrkngEngnAtvtLftmEngnRnTmBn9 12667;
BA_ "SPN" SG_ 2566587390 NxTrkngEngnAtvtLftmEngnRnTmBn10 12668;
BA_ "SPN" SG_ 2566587390 NxTrkngEngnAtvtLftmEngnRnTmBn11 12669;
BA_ "SPN" SG_ 2566587390 NxTrkngEngnAtvtLftmEngnRnTmBn12 12670;
BA_ "SPN" SG_ 2566587390 NxTrkngEngnAtvtLftmEngnRnTmBn13 12671;
BA_ "SPN" SG_ 2566587390 NxTrkngEngnAtvtLftmEngnRnTmBn14 12672;
BA_ "SPN" SG_ 2566587390 NxTEAtvtLtERTB15NtB 12673;
BA_ "SPN" SG_ 2566587390 NxTEAtvtLtERTB16RB 12674;
BA_ "SPN" SG_ 2566587390 NxTEAtvtLtERTB17MOB 12714;
BA_ "SPN" SG_ 2566587646 NxTEAtvtLtVDstB1Tt 12643;
BA_ "SPN" SG_ 2566587646 NxTrkngEngnAtvtLftmVhlDstnBn2 12644;
BA_ "SPN" SG_ 2566587646 NxTrkngEngnAtvtLftmVhlDstnBn3 12645;
BA_ "SPN" SG_ 2566587646 NxTrkngEngnAtvtLftmVhlDstnBn4 12646;
BA_ "SPN" SG_ 2566587646 NxTrkngEngnAtvtLftmVhlDstnBn5 12647;
BA_ "SPN" SG_ 2566587646 NxTrkngEngnAtvtLftmVhlDstnBn6 12648;
BA_ "SPN" SG_ 2566587646 NxTrkngEngnAtvtLftmVhlDstnBn7 12649;
BA_ "SPN" SG_ 2566587646 NxTrkngEngnAtvtLftmVhlDstnBn8 12650;
BA_ "SPN" SG_ 2566587646 NxTrkngEngnAtvtLftmVhlDstnBn9 12651;
BA_ "SPN" SG_ 2566587646 NxTrkngEngnAtvtLftmVhlDstnBn10 12652;
BA_ "SPN" SG_ 2566587646 NxTrkngEngnAtvtLftmVhlDstnBn11 12653;
BA_ "SPN" SG_ 2566587646 NxTrkngEngnAtvtLftmVhlDstnBn12 12654;
BA_ "SPN" SG_ 2566587646 NxTrkngEngnAtvtLftmVhlDstnBn13 12655;
BA_ "SPN" SG_ 2566587646 NxTrkngEngnAtvtLftmVhlDstnBn14 12656;
BA_ "SPN" SG_ 2566587646 NxTEAtvtLtVDstB15NtB 12657;
BA_ "SPN" SG_ 2566587646 NxTEAtvtLtVDstB16RB 12658;
BA_ "SPN" SG_ 2566587646 NxTEAtvtLtVDstB17MOB 12728;
BA_ "SPN" SG_ 2566587902 NxTEAtvtLtEOtptEB1Tt 12627;
BA_ "SPN" SG_ 2566587902 NxTEAtvtLtEOtptEB2 12628;
BA_ "SPN" SG_ 2566587902 NxTEAtvtLtEOtptEB3 12629;
BA_ "SPN" SG_ 2566587902 NxTEAtvtLtEOtptEB4 12630;
BA_ "SPN" SG_ 2566587902 NxTEAtvtLtEOtptEB5 12631;
BA_ "SPN" SG_ 2566587902 NxTEAtvtLtEOtptEB6 12632;
BA_ "SPN" SG_ 2566587902 NxTEAtvtLtEOtptEB7 12633;
BA_ "SPN" SG_ 2566587902 NxTEAtvtLtEOtptEB8 12634;
BA_ "SPN" SG_ 2566587902 NxTEAtvtLtEOtptEB9 12635;
BA_ "SPN" SG_ 2566587902 NxTEAtvtLtEOtptEB10 12636;
BA_ "SPN" SG_ 2566587902 NxTEAtvtLtEOtptEB11 12637;
BA_ "SPN" SG_ 2566587902 NxTEAtvtLtEOtptEB12 12638;
BA_ "SPN" SG_ 2566587902 NxTEAtvtLtEOtptEB13 12639;
BA_ "SPN" SG_ 2566587902 NxTEAtvtLtEOtptEB14 12640;
BA_ "SPN" SG_ 2566587902 NxTEAtvtLtEOtptEB15NtB 12641;
BA_ "SPN" SG_ 2566587902 NxTEAtvtLtEOtptEB16RB 12642;
BA_ "SPN" SG_ 2566587902 NxTEAtvtLtEOtptEB17MOB 12729;
BA_ "SPN" SG_ 2566588158 NxTrkngVldNxLftmFlCnsmptnBn1Ttl 12610;
BA_ "SPN" SG_ 2566588158 NxTrkngVldNxLftmFlCnsmptnBn2 12611;
BA_ "SPN" SG_ 2566588158 NxTrkngVldNxLftmFlCnsmptnBn3 12612;
BA_ "SPN" SG_ 2566588158 NxTrkngVldNxLftmFlCnsmptnBn4 12613;
BA_ "SPN" SG_ 2566588158 NxTrkngVldNxLftmFlCnsmptnBn5 12614;
BA_ "SPN" SG_ 2566588158 NxTrkngVldNxLftmFlCnsmptnBn6 12615;
BA_ "SPN" SG_ 2566588158 NxTrkngVldNxLftmFlCnsmptnBn7 12616;
BA_ "SPN" SG_ 2566588158 NxTrkngVldNxLftmFlCnsmptnBn8 12617;
BA_ "SPN" SG_ 2566588158 NxTrkngVldNxLftmFlCnsmptnBn9 12618;
BA_ "SPN" SG_ 2566588158 NxTrkngVldNxLftmFlCnsmptnBn10 12619;
BA_ "SPN" SG_ 2566588158 NxTrkngVldNxLftmFlCnsmptnBn11 12620;
BA_ "SPN" SG_ 2566588158 NxTrkngVldNxLftmFlCnsmptnBn12 12621;
BA_ "SPN" SG_ 2566588158 NxTrkngVldNxLftmFlCnsmptnBn13 12622;
BA_ "SPN" SG_ 2566588158 NxTrkngVldNxLftmFlCnsmptnBn14 12623;
BA_ "SPN" SG_ 2566588158 NxTVdNxLtFCsptB15NtB 12624;
BA_ "SPN" SG_ 2566588158 NxTVdNxLtFCsptB16RB 12625;
BA_ "SPN" SG_ 2566588158 NxTVdNxLtFCsptB17MOB 12626;
BA_ "SPN" SG_ 2566588414 NxTrkngVldNxLftmEngnRnTmBn1Ttl 12593;
BA_ "SPN" SG_ 2566588414 NxTrkngVldNxLftmEngnRnTmBn2 12594;
BA_ "SPN" SG_ 2566588414 NxTrkngVldNxLftmEngnRnTmBn3 12595;
BA_ "SPN" SG_ 2566588414 NxTrkngVldNxLftmEngnRnTmBn4 12596;
BA_ "SPN" SG_ 2566588414 NxTrkngVldNxLftmEngnRnTmBn5 12597;
BA_ "SPN" SG_ 2566588414 NxTrkngVldNxLftmEngnRnTmBn6 12598;
BA_ "SPN" SG_ 2566588414 NxTrkngVldNxLftmEngnRnTmBn7 12599;
BA_ "SPN" SG_ 2566588414 NxTrkngVldNxLftmEngnRnTmBn8 12600;
BA_ "SPN" SG_ 2566588414 NxTrkngVldNxLftmEngnRnTmBn9 12601;
BA_ "SPN" SG_ 2566588414 NxTrkngVldNxLftmEngnRnTmBn10 12602;
BA_ "SPN" SG_ 2566588414 NxTrkngVldNxLftmEngnRnTmBn11 12603;
BA_ "SPN" SG_ 2566588414 NxTrkngVldNxLftmEngnRnTmBn12 12604;
BA_ "SPN" SG_ 2566588414 NxTrkngVldNxLftmEngnRnTmBn13 12605;
BA_ "SPN" SG_ 2566588414 NxTrkngVldNxLftmEngnRnTmBn14 12606;
BA_ "SPN" SG_ 2566588414 NxTVdNxLtERTB15NtB 12607;
BA_ "SPN" SG_ 2566588414 NxTVdNxLtERTB16RB 12608;
BA_ "SPN" SG_ 2566588414 NxTVdNxLtERTB17MOB 12609;
BA_ "SPN" SG_ 2566588670 NxTrkngVldNxLftmVhlDstnBn1Ttl 12576;
BA_ "SPN" SG_ 2566588670 NxTrkngVldNxLftmVhlDstnBn2 12577;
BA_ "SPN" SG_ 2566588670 NxTrkngVldNxLftmVhlDstnBn3 12578;
BA_ "SPN" SG_ 2566588670 NxTrkngVldNxLftmVhlDstnBn4 12579;
BA_ "SPN" SG_ 2566588670 NxTrkngVldNxLftmVhlDstnBn5 12580;
BA_ "SPN" SG_ 2566588670 NxTrkngVldNxLftmVhlDstnBn6 12581;
BA_ "SPN" SG_ 2566588670 NxTrkngVldNxLftmVhlDstnBn7 12582;
BA_ "SPN" SG_ 2566588670 NxTrkngVldNxLftmVhlDstnBn8 12583;
BA_ "SPN" SG_ 2566588670 NxTrkngVldNxLftmVhlDstnBn9 12584;
BA_ "SPN" SG_ 2566588670 NxTrkngVldNxLftmVhlDstnBn10 12585;
BA_ "SPN" SG_ 2566588670 NxTrkngVldNxLftmVhlDstnBn11 12586;
BA_ "SPN" SG_ 2566588670 NxTrkngVldNxLftmVhlDstnBn12 12587;
BA_ "SPN" SG_ 2566588670 NxTrkngVldNxLftmVhlDstnBn13 12588;
BA_ "SPN" SG_ 2566588670 NxTrkngVldNxLftmVhlDstnBn14 12589;
BA_ "SPN" SG_ 2566588670 NxTrkngVldNxLftmVhlDstnBn15NtBn 12590;
BA_ "SPN" SG_ 2566588670 NxTVdNxLtVDstB16RB 12591;
BA_ "SPN" SG_ 2566588670 NxTVdNxLtVDstB17MOB 12592;
BA_ "SPN" SG_ 2566588926 NxTVdNxLtEOtptEB1Tt 12559;
BA_ "SPN" SG_ 2566588926 NxTrkngVldNxLftmEngnOtptEnrgBn2 12560;
BA_ "SPN" SG_ 2566588926 NxTrkngVldNxLftmEngnOtptEnrgBn3 12561;
BA_ "SPN" SG_ 2566588926 NxTrkngVldNxLftmEngnOtptEnrgBn4 12562;
BA_ "SPN" SG_ 2566588926 NxTrkngVldNxLftmEngnOtptEnrgBn5 12563;
BA_ "SPN" SG_ 2566588926 NxTrkngVldNxLftmEngnOtptEnrgBn6 12564;
BA_ "SPN" SG_ 2566588926 NxTrkngVldNxLftmEngnOtptEnrgBn7 12565;
BA_ "SPN" SG_ 2566588926 NxTrkngVldNxLftmEngnOtptEnrgBn8 12566;
BA_ "SPN" SG_ 2566588926 NxTrkngVldNxLftmEngnOtptEnrgBn9 12567;
BA_ "SPN" SG_ 2566588926 NxTVdNxLtEOtptEB10 12568;
BA_ "SPN" SG_ 2566588926 NxTVdNxLtEOtptEB11 12569;
BA_ "SPN" SG_ 2566588926 NxTVdNxLtEOtptEB12 12570;
BA_ "SPN" SG_ 2566588926 NxTVdNxLtEOtptEB13 12571;
BA_ "SPN" SG_ 2566588926 NxTVdNxLtEOtptEB14 12572;
BA_ "SPN" SG_ 2566588926 NxTVdNxLtEOtptEB15NtB 12573;
BA_ "SPN" SG_ 2566588926 NxTVdNxLtEOtptEB16RB 12574;
BA_ "SPN" SG_ 2566588926 NxTVdNxLtEOtptEB17MOB 12575;
BA_ "SPN" SG_ 2566589182 NxTVdNxLtEOtNxMssB1Tt 12542;
BA_ "SPN" SG_ 2566589182 NxTrkngVldNxLftmEngnOtNxMssBn2 12543;
BA_ "SPN" SG_ 2566589182 NxTrkngVldNxLftmEngnOtNxMssBn3 12544;
BA_ "SPN" SG_ 2566589182 NxTrkngVldNxLftmEngnOtNxMssBn4 12545;
BA_ "SPN" SG_ 2566589182 NxTrkngVldNxLftmEngnOtNxMssBn5 12546;
BA_ "SPN" SG_ 2566589182 NxTrkngVldNxLftmEngnOtNxMssBn6 12547;
BA_ "SPN" SG_ 2566589182 NxTrkngVldNxLftmEngnOtNxMssBn7 12548;
BA_ "SPN" SG_ 2566589182 NxTrkngVldNxLftmEngnOtNxMssBn8 12549;
BA_ "SPN" SG_ 2566589182 NxTrkngVldNxLftmEngnOtNxMssBn9 12550;
BA_ "SPN" SG_ 2566589182 NxTrkngVldNxLftmEngnOtNxMssBn10 12551;
BA_ "SPN" SG_ 2566589182 NxTrkngVldNxLftmEngnOtNxMssBn11 12552;
BA_ "SPN" SG_ 2566589182 NxTrkngVldNxLftmEngnOtNxMssBn12 12553;
BA_ "SPN" SG_ 2566589182 NxTrkngVldNxLftmEngnOtNxMssBn13 12554;
BA_ "SPN" SG_ 2566589182 NxTrkngVldNxLftmEngnOtNxMssBn14 12555;
BA_ "SPN" SG_ 2566589182 NxTVdNxLtEOtNxMssB15NtB 12556;
BA_ "SPN" SG_ 2566589182 NxTVdNxLtEOtNxMssB16RB 12557;
BA_ "SPN" SG_ 2566589182 NxTVdNxLtEOtNxMssB17MOB 12558;
BA_ "SPN" SG_ 2566589438 NxTVdNxLtSstOtNxMssB1Tt 12525;
BA_ "SPN" SG_ 2566589438 NxTrkngVldNxLftmSstmOtNxMssBn2 12526;
BA_ "SPN" SG_ 2566589438 NxTrkngVldNxLftmSstmOtNxMssBn3 12527;
BA_ "SPN" SG_ 2566589438 NxTrkngVldNxLftmSstmOtNxMssBn4 12528;
BA_ "SPN" SG_ 2566589438 NxTrkngVldNxLftmSstmOtNxMssBn5 12529;
BA_ "SPN" SG_ 2566589438 NxTrkngVldNxLftmSstmOtNxMssBn6 12530;
BA_ "SPN" SG_ 2566589438 NxTrkngVldNxLftmSstmOtNxMssBn7 12531;
BA_ "SPN" SG_ 2566589438 NxTrkngVldNxLftmSstmOtNxMssBn8 12532;
BA_ "SPN" SG_ 2566589438 NxTrkngVldNxLftmSstmOtNxMssBn9 12533;
BA_ "SPN" SG_ 2566589438 NxTrkngVldNxLftmSstmOtNxMssBn10 12534;
BA_ "SPN" SG_ 2566589438 NxTrkngVldNxLftmSstmOtNxMssBn11 12535;
BA_ "SPN" SG_ 2566589438 NxTrkngVldNxLftmSstmOtNxMssBn12 12536;
BA_ "SPN" SG_ 2566589438 NxTrkngVldNxLftmSstmOtNxMssBn13 12537;
BA_ "SPN" SG_ 2566589438 NxTrkngVldNxLftmSstmOtNxMssBn14 12538;
BA_ "SPN" SG_ 2566589438 NxTVdNxLtSstOtNxMssB15NtB 12539;
BA_ "SPN" SG_ 2566589438 NxTVdNxLtSstOtNxMssB16RB 12540;
BA_ "SPN" SG_ 2566589438 NxTVdNxLtSstOtNxMssB17MOB 12541;
BA_ "SPN" SG_ 2566589694 NxTrkngStrd100HrFlCnsmptnBn1Ttl 12508;
BA_ "SPN" SG_ 2566589694 NxTrkngStrd100HrFlCnsmptnBn2 12509;
BA_ "SPN" SG_ 2566589694 NxTrkngStrd100HrFlCnsmptnBn3 12510;
BA_ "SPN" SG_ 2566589694 NxTrkngStrd100HrFlCnsmptnBn4 12511;
BA_ "SPN" SG_ 2566589694 NxTrkngStrd100HrFlCnsmptnBn5 12512;
BA_ "SPN" SG_ 2566589694 NxTrkngStrd100HrFlCnsmptnBn6 12513;
BA_ "SPN" SG_ 2566589694 NxTrkngStrd100HrFlCnsmptnBn7 12514;
BA_ "SPN" SG_ 2566589694 NxTrkngStrd100HrFlCnsmptnBn8 12515;
BA_ "SPN" SG_ 2566589694 NxTrkngStrd100HrFlCnsmptnBn9 12516;
BA_ "SPN" SG_ 2566589694 NxTrkngStrd100HrFlCnsmptnBn10 12517;
BA_ "SPN" SG_ 2566589694 NxTrkngStrd100HrFlCnsmptnBn11 12518;
BA_ "SPN" SG_ 2566589694 NxTrkngStrd100HrFlCnsmptnBn12 12519;
BA_ "SPN" SG_ 2566589694 NxTrkngStrd100HrFlCnsmptnBn13 12520;
BA_ "SPN" SG_ 2566589694 NxTrkngStrd100HrFlCnsmptnBn14 12521;
BA_ "SPN" SG_ 2566589694 NxTStd100HFCsptB15NtB 12522;
BA_ "SPN" SG_ 2566589694 NxTStd100HFCsptB16RB 12523;
BA_ "SPN" SG_ 2566589694 NxTStd100HFCsptB17MOB 12524;
BA_ "SPN" SG_ 2566589950 NxTrkngStrd100HrEngnRnTmBn1Ttl 12491;
BA_ "SPN" SG_ 2566589950 NxTrkngStrd100HrEngnRnTmBn2 12492;
BA_ "SPN" SG_ 2566589950 NxTrkngStrd100HrEngnRnTmBn3 12493;
BA_ "SPN" SG_ 2566589950 NxTrkngStrd100HrEngnRnTmBn4 12494;
BA_ "SPN" SG_ 2566589950 NxTrkngStrd100HrEngnRnTmBn5 12495;
BA_ "SPN" SG_ 2566589950 NxTrkngStrd100HrEngnRnTmBn6 12496;
BA_ "SPN" SG_ 2566589950 NxTrkngStrd100HrEngnRnTmBn7 12497;
BA_ "SPN" SG_ 2566589950 NxTrkngStrd100HrEngnRnTmBn8 12498;
BA_ "SPN" SG_ 2566589950 NxTrkngStrd100HrEngnRnTmBn9 12499;
BA_ "SPN" SG_ 2566589950 NxTrkngStrd100HrEngnRnTmBn10 12500;
BA_ "SPN" SG_ 2566589950 NxTrkngStrd100HrEngnRnTmBn11 12501;
BA_ "SPN" SG_ 2566589950 NxTrkngStrd100HrEngnRnTmBn12 12502;
BA_ "SPN" SG_ 2566589950 NxTrkngStrd100HrEngnRnTmBn13 12503;
BA_ "SPN" SG_ 2566589950 NxTrkngStrd100HrEngnRnTmBn14 12504;
BA_ "SPN" SG_ 2566589950 NxTStd100HERTB15NtB 12505;
BA_ "SPN" SG_ 2566589950 NxTStd100HERTB16RB 12506;
BA_ "SPN" SG_ 2566589950 NxTStd100HERTB17MOB 12507;
BA_ "SPN" SG_ 2566590206 NxTrkngStrd100HrVhlDstnBn1Ttl 12474;
BA_ "SPN" SG_ 2566590206 NxTrkngStrd100HrVhlDstnBn2 12475;
BA_ "SPN" SG_ 2566590206 NxTrkngStrd100HrVhlDstnBn3 12476;
BA_ "SPN" SG_ 2566590206 NxTrkngStrd100HrVhlDstnBn4 12477;
BA_ "SPN" SG_ 2566590206 NxTrkngStrd100HrVhlDstnBn5 12478;
BA_ "SPN" SG_ 2566590206 NxTrkngStrd100HrVhlDstnBn6 12479;
BA_ "SPN" SG_ 2566590206 NxTrkngStrd100HrVhlDstnBn7 12480;
BA_ "SPN" SG_ 2566590206 NxTrkngStrd100HrVhlDstnBn8 12481;
BA_ "SPN" SG_ 2566590206 NxTrkngStrd100HrVhlDstnBn9 12482;
BA_ "SPN" SG_ 2566590206 NxTrkngStrd100HrVhlDstnBn10 12483;
BA_ "SPN" SG_ 2566590206 NxTrkngStrd100HrVhlDstnBn11 12484;
BA_ "SPN" SG_ 2566590206 NxTrkngStrd100HrVhlDstnBn12 12485;
BA_ "SPN" SG_ 2566590206 NxTrkngStrd100HrVhlDstnBn13 12486;
BA_ "SPN" SG_ 2566590206 NxTrkngStrd100HrVhlDstnBn14 12487;
BA_ "SPN" SG_ 2566590206 NxTrkngStrd100HrVhlDstnBn15NtBn 12488;
BA_ "SPN" SG_ 2566590206 NxTStd100HVDstB16RB 12489;
BA_ "SPN" SG_ 2566590206 NxTStd100HVDstB17MOB 12490;
